VERSION "dbc-export 1 2026.26.6.5"

NS_ :

BS_:

BU_: ADSP APB APP APS APSB BB BMS CC CMP CMPD CP DAS DI DIF DIR DPB EPAS3P EPAS3S EPASTP EPASTS EPBL EPBR ESP EVSE FC GTW HCML HCMR HVP IBST ICR IDB LS OCS1P ODIN PARK PCS PCS2 PLG PM PMF PMR PNCD PTC RADC RCM RCM2 RCM3 RCU SCCM SCM SCS SDCR TAS TCU TCU2 TPMS TRCM UDS UI UIS UMC USM V2G VC VCBATT VCBATT0 VCBATT1 VCBATT2 VCCC VCFRONT VCFRONT1 VCFRONT2 VCLEFT VCRIGHT VCSEAT2L VCSEAT2R VCSEC VEH

BO_ 1318 DIF_alertLog: 8 DIF
 SG_ DIF_alertID M : 0|8@1+ (1,0) [0|255] "" Vector__XXX
 SG_ DIF_alertState : 15|1@1+ (1,0) [0|1] "" Vector__XXX
 SG_ DIF_a001_thermalWarning_H m1 : 16|1@1+ (1,0) [0|1] "" Vector__XXX
 SG_ DIF_a001_thermalShutdown_H m1 : 17|1@1+ (1,0) [0|1] "" Vector__XXX
 SG_ DIF_a001_undervoltVL_H m1 : 18|1@1+ (1,0) [0|1] "" Vector__XXX
 SG_ DIF_a001_undervoltVH_H m1 : 19|1@1+ (1,0) [0|1] "" Vector__XXX
 SG_ DIF_a001_sense_H m1 : 20|1@1+ (1,0) [0|1] "" Vector__XXX
 SG_ DIF_a001_desat_H m1 : 21|1@1+ (1,0) [0|1] "" Vector__XXX
 SG_ DIF_a001_overvoltVL_H m1 : 22|1@1+ (1,0) [0|1] "" Vector__XXX
 SG_ DIF_a001_overvoltVH_H m1 : 23|1@1+ (1,0) [0|1] "" Vector__XXX
 SG_ DIF_a001_undervoltVCC_H m1 : 24|1@1+ (1,0) [0|1] "" Vector__XXX
 SG_ DIF_a001_asynchStop_H m1 : 25|1@1+ (1,0) [0|1] "" Vector__XXX
 SG_ DIF_a001_remoteRegError_H m1 : 26|1@1+ (1,0) [0|1] "" Vector__XXX
 SG_ DIF_a001_undervoltVDD_H m1 : 27|1@1+ (1,0) [0|1] "" Vector__XXX
 SG_ DIF_a001_overvoltVDD_H m1 : 28|1@1+ (1,0) [0|1] "" Vector__XXX
 SG_ DIF_a001_localRegError_H m1 : 29|1@1+ (1,0) [0|1] "" Vector__XXX
 SG_ DIF_a001_spiError_H m1 : 30|1@1+ (1,0) [0|1] "" Vector__XXX
 SG_ DIF_a001_deadtimeError_H m1 : 31|1@1+ (1,0) [0|1] "" Vector__XXX
 SG_ DIF_a001_thermalWarning_L m1 : 32|1@1+ (1,0) [0|1] "" Vector__XXX
 SG_ DIF_a001_thermalShutdown_L m1 : 33|1@1+ (1,0) [0|1] "" Vector__XXX
 SG_ DIF_a001_undervoltVL_L m1 : 34|1@1+ (1,0) [0|1] "" Vector__XXX
 SG_ DIF_a001_undervoltVH_L m1 : 35|1@1+ (1,0) [0|1] "" Vector__XXX
 SG_ DIF_a001_sense_L m1 : 36|1@1+ (1,0) [0|1] "" Vector__XXX
 SG_ DIF_a001_desat_L m1 : 37|1@1+ (1,0) [0|1] "" Vector__XXX
 SG_ DIF_a001_overvoltVL_L m1 : 38|1@1+ (1,0) [0|1] "" Vector__XXX
 SG_ DIF_a001_overvoltVH_L m1 : 39|1@1+ (1,0) [0|1] "" Vector__XXX
 SG_ DIF_a001_undervoltVCC_L m1 : 40|1@1+ (1,0) [0|1] "" Vector__XXX
 SG_ DIF_a001_asynchStop_L m1 : 41|1@1+ (1,0) [0|1] "" Vector__XXX
 SG_ DIF_a001_remoteRegError_L m1 : 42|1@1+ (1,0) [0|1] "" Vector__XXX
 SG_ DIF_a001_undervoltVDD_L m1 : 43|1@1+ (1,0) [0|1] "" Vector__XXX
 SG_ DIF_a001_overvoltVDD_L m1 : 44|1@1+ (1,0) [0|1] "" Vector__XXX
 SG_ DIF_a001_localRegError_L m1 : 45|1@1+ (1,0) [0|1] "" Vector__XXX
 SG_ DIF_a001_spiError_L m1 : 46|1@1+ (1,0) [0|1] "" Vector__XXX
 SG_ DIF_a001_deadtimeError_L m1 : 47|1@1+ (1,0) [0|1] "" Vector__XXX
 SG_ DIF_a001_gateDriveErrCounter m1 : 48|4@1+ (1,0) [0|15] "" Vector__XXX
 SG_ DIF_a001_remoteCommError_H m1 : 52|1@1+ (1,0) [0|1] "" Vector__XXX
 SG_ DIF_a001_localCommError_H m1 : 53|1@1+ (1,0) [0|1] "" Vector__XXX
 SG_ DIF_a001_remoteReset_H m1 : 54|1@1+ (1,0) [0|1] "" Vector__XXX
 SG_ DIF_a001_localReset_H m1 : 55|1@1+ (1,0) [0|1] "" Vector__XXX
 SG_ DIF_a001_remoteCommError_L m1 : 56|1@1+ (1,0) [0|1] "" Vector__XXX
 SG_ DIF_a001_localCommError_L m1 : 57|1@1+ (1,0) [0|1] "" Vector__XXX
 SG_ DIF_a001_remoteReset_L m1 : 58|1@1+ (1,0) [0|1] "" Vector__XXX
 SG_ DIF_a001_localReset_L m1 : 59|1@1+ (1,0) [0|1] "" Vector__XXX
 SG_ DIF_a001_faultLine1Gpio_H m1 : 60|1@1+ (1,0) [0|1] "" Vector__XXX
 SG_ DIF_a001_faultLine1Gpio_L m1 : 61|1@1+ (1,0) [0|1] "" Vector__XXX
 SG_ DIF_a002_thermalWarning_H m2 : 16|1@1+ (1,0) [0|1] "" Vector__XXX
 SG_ DIF_a002_thermalShutdown_H m2 : 17|1@1+ (1,0) [0|1] "" Vector__XXX
 SG_ DIF_a002_undervoltVL_H m2 : 18|1@1+ (1,0) [0|1] "" Vector__XXX
 SG_ DIF_a002_undervoltVH_H m2 : 19|1@1+ (1,0) [0|1] "" Vector__XXX
 SG_ DIF_a002_sense_H m2 : 20|1@1+ (1,0) [0|1] "" Vector__XXX
 SG_ DIF_a002_desat_H m2 : 21|1@1+ (1,0) [0|1] "" Vector__XXX
 SG_ DIF_a002_overvoltVL_H m2 : 22|1@1+ (1,0) [0|1] "" Vector__XXX
 SG_ DIF_a002_overvoltVH_H m2 : 23|1@1+ (1,0) [0|1] "" Vector__XXX
 SG_ DIF_a002_undervoltVCC_H m2 : 24|1@1+ (1,0) [0|1] "" Vector__XXX
 SG_ DIF_a002_asynchStop_H m2 : 25|1@1+ (1,0) [0|1] "" Vector__XXX
 SG_ DIF_a002_remoteRegError_H m2 : 26|1@1+ (1,0) [0|1] "" Vector__XXX
 SG_ DIF_a002_undervoltVDD_H m2 : 27|1@1+ (1,0) [0|1] "" Vector__XXX
 SG_ DIF_a002_overvoltVDD_H m2 : 28|1@1+ (1,0) [0|1] "" Vector__XXX
 SG_ DIF_a002_localRegError_H m2 : 29|1@1+ (1,0) [0|1] "" Vector__XXX
 SG_ DIF_a002_spiError_H m2 : 30|1@1+ (1,0) [0|1] "" Vector__XXX
 SG_ DIF_a002_deadtimeError_H m2 : 31|1@1+ (1,0) [0|1] "" Vector__XXX
 SG_ DIF_a002_thermalWarning_L m2 : 32|1@1+ (1,0) [0|1] "" Vector__XXX
 SG_ DIF_a002_thermalShutdown_L m2 : 33|1@1+ (1,0) [0|1] "" Vector__XXX
 SG_ DIF_a002_undervoltVL_L m2 : 34|1@1+ (1,0) [0|1] "" Vector__XXX
 SG_ DIF_a002_undervoltVH_L m2 : 35|1@1+ (1,0) [0|1] "" Vector__XXX
 SG_ DIF_a002_sense_L m2 : 36|1@1+ (1,0) [0|1] "" Vector__XXX
 SG_ DIF_a002_desat_L m2 : 37|1@1+ (1,0) [0|1] "" Vector__XXX
 SG_ DIF_a002_overvoltVL_L m2 : 38|1@1+ (1,0) [0|1] "" Vector__XXX
 SG_ DIF_a002_overvoltVH_L m2 : 39|1@1+ (1,0) [0|1] "" Vector__XXX
 SG_ DIF_a002_undervoltVCC_L m2 : 40|1@1+ (1,0) [0|1] "" Vector__XXX
 SG_ DIF_a002_asynchStop_L m2 : 41|1@1+ (1,0) [0|1] "" Vector__XXX
 SG_ DIF_a002_remoteRegError_L m2 : 42|1@1+ (1,0) [0|1] "" Vector__XXX
 SG_ DIF_a002_undervoltVDD_L m2 : 43|1@1+ (1,0) [0|1] "" Vector__XXX
 SG_ DIF_a002_overvoltVDD_L m2 : 44|1@1+ (1,0) [0|1] "" Vector__XXX
 SG_ DIF_a002_localRegError_L m2 : 45|1@1+ (1,0) [0|1] "" Vector__XXX
 SG_ DIF_a002_spiError_L m2 : 46|1@1+ (1,0) [0|1] "" Vector__XXX
 SG_ DIF_a002_deadtimeError_L m2 : 47|1@1+ (1,0) [0|1] "" Vector__XXX
 SG_ DIF_a002_gateDriveErrCounter m2 : 48|4@1+ (1,0) [0|15] "" Vector__XXX
 SG_ DIF_a002_remoteCommError_H m2 : 52|1@1+ (1,0) [0|1] "" Vector__XXX
 SG_ DIF_a002_localCommError_H m2 : 53|1@1+ (1,0) [0|1] "" Vector__XXX
 SG_ DIF_a002_remoteReset_H m2 : 54|1@1+ (1,0) [0|1] "" Vector__XXX
 SG_ DIF_a002_localReset_H m2 : 55|1@1+ (1,0) [0|1] "" Vector__XXX
 SG_ DIF_a002_remoteCommError_L m2 : 56|1@1+ (1,0) [0|1] "" Vector__XXX
 SG_ DIF_a002_localCommError_L m2 : 57|1@1+ (1,0) [0|1] "" Vector__XXX
 SG_ DIF_a002_remoteReset_L m2 : 58|1@1+ (1,0) [0|1] "" Vector__XXX
 SG_ DIF_a002_localReset_L m2 : 59|1@1+ (1,0) [0|1] "" Vector__XXX
 SG_ DIF_a002_faultLine1Gpio_H m2 : 60|1@1+ (1,0) [0|1] "" Vector__XXX
 SG_ DIF_a002_faultLine1Gpio_L m2 : 61|1@1+ (1,0) [0|1] "" Vector__XXX
 SG_ DIF_a003_thermalWarning_H m3 : 16|1@1+ (1,0) [0|1] "" Vector__XXX
 SG_ DIF_a003_thermalShutdown_H m3 : 17|1@1+ (1,0) [0|1] "" Vector__XXX
 SG_ DIF_a003_undervoltVL_H m3 : 18|1@1+ (1,0) [0|1] "" Vector__XXX
 SG_ DIF_a003_undervoltVH_H m3 : 19|1@1+ (1,0) [0|1] "" Vector__XXX
 SG_ DIF_a003_sense_H m3 : 20|1@1+ (1,0) [0|1] "" Vector__XXX
 SG_ DIF_a003_desat_H m3 : 21|1@1+ (1,0) [0|1] "" Vector__XXX
 SG_ DIF_a003_overvoltVL_H m3 : 22|1@1+ (1,0) [0|1] "" Vector__XXX
 SG_ DIF_a003_overvoltVH_H m3 : 23|1@1+ (1,0) [0|1] "" Vector__XXX
 SG_ DIF_a003_undervoltVCC_H m3 : 24|1@1+ (1,0) [0|1] "" Vector__XXX
 SG_ DIF_a003_asynchStop_H m3 : 25|1@1+ (1,0) [0|1] "" Vector__XXX
 SG_ DIF_a003_remoteRegError_H m3 : 26|1@1+ (1,0) [0|1] "" Vector__XXX
 SG_ DIF_a003_undervoltVDD_H m3 : 27|1@1+ (1,0) [0|1] "" Vector__XXX
 SG_ DIF_a003_overvoltVDD_H m3 : 28|1@1+ (1,0) [0|1] "" Vector__XXX
 SG_ DIF_a003_localRegError_H m3 : 29|1@1+ (1,0) [0|1] "" Vector__XXX
 SG_ DIF_a003_spiError_H m3 : 30|1@1+ (1,0) [0|1] "" Vector__XXX
 SG_ DIF_a003_deadtimeError_H m3 : 31|1@1+ (1,0) [0|1] "" Vector__XXX
 SG_ DIF_a003_thermalWarning_L m3 : 32|1@1+ (1,0) [0|1] "" Vector__XXX
 SG_ DIF_a003_thermalShutdown_L m3 : 33|1@1+ (1,0) [0|1] "" Vector__XXX
 SG_ DIF_a003_undervoltVL_L m3 : 34|1@1+ (1,0) [0|1] "" Vector__XXX
 SG_ DIF_a003_undervoltVH_L m3 : 35|1@1+ (1,0) [0|1] "" Vector__XXX
 SG_ DIF_a003_sense_L m3 : 36|1@1+ (1,0) [0|1] "" Vector__XXX
 SG_ DIF_a003_desat_L m3 : 37|1@1+ (1,0) [0|1] "" Vector__XXX
 SG_ DIF_a003_overvoltVL_L m3 : 38|1@1+ (1,0) [0|1] "" Vector__XXX
 SG_ DIF_a003_overvoltVH_L m3 : 39|1@1+ (1,0) [0|1] "" Vector__XXX
 SG_ DIF_a003_undervoltVCC_L m3 : 40|1@1+ (1,0) [0|1] "" Vector__XXX
 SG_ DIF_a003_asynchStop_L m3 : 41|1@1+ (1,0) [0|1] "" Vector__XXX
 SG_ DIF_a003_remoteRegError_L m3 : 42|1@1+ (1,0) [0|1] "" Vector__XXX
 SG_ DIF_a003_undervoltVDD_L m3 : 43|1@1+ (1,0) [0|1] "" Vector__XXX
 SG_ DIF_a003_overvoltVDD_L m3 : 44|1@1+ (1,0) [0|1] "" Vector__XXX
 SG_ DIF_a003_localRegError_L m3 : 45|1@1+ (1,0) [0|1] "" Vector__XXX
 SG_ DIF_a003_spiError_L m3 : 46|1@1+ (1,0) [0|1] "" Vector__XXX
 SG_ DIF_a003_deadtimeError_L m3 : 47|1@1+ (1,0) [0|1] "" Vector__XXX
 SG_ DIF_a003_gateDriveErrCounter m3 : 48|4@1+ (1,0) [0|15] "" Vector__XXX
 SG_ DIF_a003_remoteCommError_H m3 : 52|1@1+ (1,0) [0|1] "" Vector__XXX
 SG_ DIF_a003_localCommError_H m3 : 53|1@1+ (1,0) [0|1] "" Vector__XXX
 SG_ DIF_a003_remoteReset_H m3 : 54|1@1+ (1,0) [0|1] "" Vector__XXX
 SG_ DIF_a003_localReset_H m3 : 55|1@1+ (1,0) [0|1] "" Vector__XXX
 SG_ DIF_a003_remoteCommError_L m3 : 56|1@1+ (1,0) [0|1] "" Vector__XXX
 SG_ DIF_a003_localCommError_L m3 : 57|1@1+ (1,0) [0|1] "" Vector__XXX
 SG_ DIF_a003_remoteReset_L m3 : 58|1@1+ (1,0) [0|1] "" Vector__XXX
 SG_ DIF_a003_localReset_L m3 : 59|1@1+ (1,0) [0|1] "" Vector__XXX
 SG_ DIF_a003_faultLine1Gpio_H m3 : 60|1@1+ (1,0) [0|1] "" Vector__XXX
 SG_ DIF_a003_faultLine1Gpio_L m3 : 61|1@1+ (1,0) [0|1] "" Vector__XXX
 SG_ DIF_a007_phaseAcurrent m7 : 16|8@1+ (8,0) [0|2040] "A" Vector__XXX
 SG_ DIF_a007_phaseBcurrent m7 : 24|8@1+ (8,0) [0|2040] "A" Vector__XXX
 SG_ DIF_a007_offsetError m7 : 32|14@1- (0.0003834952,0) [-3.1415926784|3.1412091832] "rad" Vector__XXX
 SG_ DIF_a007_idFdbStdDeviation m7 : 46|8@1+ (4,0) [0|1020] "A" Vector__XXX
 SG_ DIF_a007_iqFdbStdDeviation m7 : 54|8@1+ (4,0) [0|1020] "A" Vector__XXX
 SG_ DIF_a007_motorShift m7 : 62|1@1+ (1,0) [0|1] "" Vector__XXX
 SG_ DIF_a007_motorShort m7 : 63|1@1+ (1,0) [0|1] "" Vector__XXX
 SG_ DIF_a010_sccReset m10 : 16|1@1+ (1,0) [0|1] "" Vector__XXX
 SG_ DIF_a010_hibernate m10 : 17|1@1+ (1,0) [0|1] "" Vector__XXX
 SG_ DIF_a010_hwBist m10 : 18|1@1+ (1,0) [0|1] "" Vector__XXX
 SG_ DIF_a010_nmiWatchdog m10 : 19|1@1+ (1,0) [0|1] "" Vector__XXX
 SG_ DIF_a010_watchdog m10 : 20|1@1+ (1,0) [0|1] "" Vector__XXX
 SG_ DIF_a010_clockFailNmi m10 : 21|1@1+ (1,0) [0|1] "" Vector__XXX
 SG_ DIF_a010_ramUncErrorNmi m10 : 22|1@1+ (1,0) [0|1] "" Vector__XXX
 SG_ DIF_a010_flashUncErrorNmi m10 : 23|1@1+ (1,0) [0|1] "" Vector__XXX
 SG_ DIF_a010_cpu1signMismatchNmi m10 : 24|1@1+ (1,0) [0|1] "" Vector__XXX
 SG_ DIF_a010_cpu2signMismatchNmi m10 : 25|1@1+ (1,0) [0|1] "" Vector__XXX
 SG_ DIF_a010_pieVectErrorNmi m10 : 26|1@1+ (1,0) [0|1] "" Vector__XXX
 SG_ DIF_a010_sysDbgNmi m10 : 27|1@1+ (1,0) [0|1] "" Vector__XXX
 SG_ DIF_a010_rlNmi m10 : 28|1@1+ (1,0) [0|1] "" Vector__XXX
 SG_ DIF_a010_ovfNmi m10 : 29|1@1+ (1,0) [0|1] "" Vector__XXX
 SG_ DIF_a010_wdtFlags m10 : 32|16@1+ (1,0) [0|65535] "" Vector__XXX
 SG_ DIF_a011_reason m11 : 16|3@1+ (1,0) [0|7] "" Vector__XXX
 SG_ DIF_a011_phaseAHigh m11 : 19|1@1+ (1,0) [0|1] "" Vector__XXX
 SG_ DIF_a011_phaseALow m11 : 20|1@1+ (1,0) [0|1] "" Vector__XXX
 SG_ DIF_a011_phaseBHigh m11 : 21|1@1+ (1,0) [0|1] "" Vector__XXX
 SG_ DIF_a011_phaseBLow m11 : 22|1@1+ (1,0) [0|1] "" Vector__XXX
 SG_ DIF_a011_phaseCHigh m11 : 23|1@1+ (1,0) [0|1] "" Vector__XXX
 SG_ DIF_a011_phaseCLow m11 : 24|1@1+ (1,0) [0|1] "" Vector__XXX
 SG_ DIF_a011_regAddress m11 : 25|5@1+ (1,0) [0|31] "" Vector__XXX
 SG_ DIF_a011_badGateDriveIC m11 : 32|3@1+ (1,0) [0|7] "" Vector__XXX
 SG_ DIF_a011_badDataRead m11 : 40|8@1+ (1,0) [0|255] "" Vector__XXX
 SG_ DIF_a011_badDataExpected m11 : 48|8@1+ (1,0) [0|255] "" Vector__XXX
 SG_ DIF_a011_codeBranch m11 : 56|4@1+ (1,0) [0|15] "" Vector__XXX
 SG_ DIF_a012_hvilStatus m12 : 16|2@1+ (1,0) [0|2] "" Vector__XXX
 SG_ DIF_a012_hvilCmVoltage m12 : 24|8@1+ (0.08,0) [0|20.4] "V" Vector__XXX
 SG_ DIF_a012_hvilCurrent m12 : 32|8@1+ (0.1,0) [0|25.5] "mA" Vector__XXX
 SG_ DIF_a012_hvilFaultGpio m12 : 40|1@1+ (1,0) [0|1] "" Vector__XXX
 SG_ DIF_a012_hvilSupplyPinDI m12 : 41|1@1+ (1,0) [0|1] "" Vector__XXX
 SG_ DIF_a012_hvilSupplyPinPM m12 : 42|1@1+ (1,0) [0|1] "" Vector__XXX
 SG_ DIF_a012_activeDisOn3V3 m12 : 43|1@1+ (1,0) [0|1] "" Vector__XXX
 SG_ DIF_a012_hvilHeaderFault m12 : 44|1@1+ (1,0) [0|1] "" Vector__XXX
 SG_ DIF_a013_address m13 : 16|32@1+ (1,0) [0|4294967295] "" Vector__XXX
 SG_ DIF_a013_errorType m13 : 48|4@1+ (1,0) [0|15] "" Vector__XXX
 SG_ DIF_a014_motorSpeed m14 : 16|14@1- (2,0) [-16384|16382] "RPM" Vector__XXX
 SG_ DIF_a014_adState m14 : 30|2@1+ (1,0) [0|3] "" Vector__XXX
 SG_ DIF_a014_torqueCommandFwd m14 : 32|10@1- (2,0) [-1024|1022] "Nm" Vector__XXX
 SG_ DIF_a014_brakeMasterCylPress m14 : 42|10@1+ (0.25,-42.5) [-42.5|213.25] "bar" Vector__XXX
 SG_ DIF_a014_rmsTorqueError m14 : 52|10@1+ (1,0) [0|1023] "Nm" Vector__XXX
 SG_ DIF_a014_tcEnabled m14 : 62|1@1+ (1,0) [0|1] "" Vector__XXX
 SG_ DIF_a014_fbDeratedForRmsError m14 : 63|1@1+ (1,0) [0|1] "" Vector__XXX
 SG_ DIF_a016_newSafeState m16 : 16|2@1+ (1,0) [0|3] "" Vector__XXX
 SG_ DIF_a016_oldSafeState m16 : 18|2@1+ (1,0) [0|3] "" Vector__XXX
 SG_ DIF_a016_gateDriveFaultLine m16 : 20|1@1+ (1,0) [0|1] "" Vector__XXX
 SG_ DIF_a016_ascMonitor m16 : 21|1@1+ (1,0) [0|1] "" Vector__XXX
 SG_ DIF_a016_uncontrolledRegenZone m16 : 22|1@1+ (1,0) [0|1] "" Vector__XXX
 SG_ DIF_a016_pedalMonitorPreWatchdog m16 : 23|1@1+ (1,0) [0|1] "" Vector__XXX
 SG_ DIF_a016_motorRPM m16 : 24|16@1- (1,0) [-32768|32767] "RPM" Vector__XXX
 SG_ DIF_a016_torqueMotor m16 : 40|16@1- (1,0) [-32768|32767] "Nm" Vector__XXX
 SG_ DIF_a016_safetyICfaultLine m16 : 56|1@1+ (1,0) [0|1] "" Vector__XXX
 SG_ DIF_a016_triggerEvent m16 : 57|5@1+ (1,0) [0|31] "" Vector__XXX
 SG_ DIF_a024_vBat m24 : 16|8@1+ (2,0) [0|510] "V" Vector__XXX
 SG_ DIF_a024_failReason m24 : 24|3@1+ (1,0) [0|7] "" Vector__XXX
 SG_ DIF_a024_state m24 : 27|4@1+ (1,0) [0|15] "" Vector__XXX
 SG_ DIF_a024_Ia m24 : 31|7@1- (22.5,0) [-1440|1417.5] "A" Vector__XXX
 SG_ DIF_a024_Ib m24 : 38|7@1- (22.5,0) [-1440|1417.5] "A" Vector__XXX
 SG_ DIF_a024_maxCurrMagSqrd m24 : 45|12@1+ (500,0) [0|2047500] "A2" Vector__XXX
 SG_ DIF_a024_rotorAngle m24 : 57|7@1- (3,0) [-192|189] "degrees" Vector__XXX
 SG_ DIF_a025_Ia m25 : 16|16@1- (0.1,0) [-3276.8|3276.7] "A" Vector__XXX
 SG_ DIF_a025_torqueMotor m25 : 32|13@1- (0.25,0) [-1024|1023.75] "Nm" Vector__XXX
 SG_ DIF_a025_motorSpeed m25 : 48|16@1- (1,0) [-32768|32767] "RPM" Vector__XXX
 SG_ DIF_a026_Ib m26 : 16|16@1- (0.1,0) [-3276.8|3276.7] "A" Vector__XXX
 SG_ DIF_a026_torqueMotor m26 : 32|13@1- (0.25,0) [-1024|1023.75] "Nm" Vector__XXX
 SG_ DIF_a026_motorSpeed m26 : 48|16@1- (1,0) [-32768|32767] "RPM" Vector__XXX
 SG_ DIF_a027_Ic m27 : 16|16@1- (0.1,0) [-3276.8|3276.7] "A" Vector__XXX
 SG_ DIF_a027_torqueMotor m27 : 32|13@1- (0.25,0) [-1024|1023.75] "Nm" Vector__XXX
 SG_ DIF_a027_motorSpeed m27 : 48|16@1- (1,0) [-32768|32767] "RPM" Vector__XXX
 SG_ DIF_a028_phaseAirms m28 : 16|16@1+ (1,0) [0|65535] "A" Vector__XXX
 SG_ DIF_a028_iArmsTorque m28 : 32|16@1+ (0.25,0) [0|16383.75] "Nm" Vector__XXX
 SG_ DIF_a028_iArmsSpeed m28 : 48|16@1+ (1,0) [0|65535] "RPM" Vector__XXX
 SG_ DIF_a029_phaseBirms m29 : 16|16@1+ (1,0) [0|65535] "A" Vector__XXX
 SG_ DIF_a029_iBrmsTorque m29 : 32|16@1+ (0.25,0) [0|16383.75] "Nm" Vector__XXX
 SG_ DIF_a029_iBrmsSpeed m29 : 48|16@1+ (1,0) [0|65535] "RPM" Vector__XXX
 SG_ DIF_a030_phaseCirms m30 : 16|16@1+ (1,0) [0|65535] "A" Vector__XXX
 SG_ DIF_a030_iCrmsTorque m30 : 32|16@1+ (0.25,0) [0|16383.75] "Nm" Vector__XXX
 SG_ DIF_a030_iCrmsSpeed m30 : 48|16@1+ (1,0) [0|65535] "RPM" Vector__XXX
 SG_ DIF_a031_phaseAoffset m31 : 16|15@1- (0.002,0) [-32.768|32.766] "A" Vector__XXX
 SG_ DIF_a032_phaseBoffset m32 : 16|15@1- (0.002,0) [-32.768|32.766] "A" Vector__XXX
 SG_ DIF_a033_phaseAcurrent m33 : 16|16@1- (1,0) [-32768|32767] "A" Vector__XXX
 SG_ DIF_a033_deltaIa m33 : 32|16@1- (1,0) [-32768|32767] "A" Vector__XXX
 SG_ DIF_a033_vRefIa m33 : 48|16@1- (0.001,0) [-32.768|32.767] "V" Vector__XXX
 SG_ DIF_a034_phaseBcurrent m34 : 16|16@1- (1,0) [-32768|32767] "A" Vector__XXX
 SG_ DIF_a034_deltaIb m34 : 32|16@1- (1,0) [-32768|32767] "A" Vector__XXX
 SG_ DIF_a034_vRefIb m34 : 48|16@1- (0.001,0) [-32.768|32.767] "V" Vector__XXX
 SG_ DIF_a035_phaseAerror m35 : 16|1@1+ (1,0) [0|1] "" Vector__XXX
 SG_ DIF_a035_phaseBerror m35 : 17|1@1+ (1,0) [0|1] "" Vector__XXX
 SG_ DIF_a035_phaseCerror m35 : 18|1@1+ (1,0) [0|1] "" Vector__XXX
 SG_ DIF_a035_standbyCurrent m35 : 19|1@1+ (1,0) [0|1] "" Vector__XXX
 SG_ DIF_a035_unbalancedCurrent m35 : 20|1@1+ (1,0) [0|1] "" Vector__XXX
 SG_ DIF_a035_wontMoveCurrent m35 : 21|1@1+ (1,0) [0|1] "" Vector__XXX
 SG_ DIF_a035_reportingPhase m35 : 22|2@1+ (1,0) [0|3] "" Vector__XXX
 SG_ DIF_a035_noDriveCurrent m35 : 24|1@1+ (1,0) [0|1] "" Vector__XXX
 SG_ DIF_a035_phaseDifference m35 : 25|7@1+ (1,0) [0|127] "%" Vector__XXX
 SG_ DIF_a035_phaseCurrent m35 : 32|16@1+ (1,0) [0|65535] "A" Vector__XXX
 SG_ DIF_a035_frequency m35 : 48|10@1+ (1,0) [0|1023] "Hz" Vector__XXX
 SG_ DIF_a036_busVoltage m36 : 16|16@1+ (0.1,0) [0|6553.5] "V" Vector__XXX
 SG_ DIF_a036_busHighLimit m36 : 32|16@1+ (0.1,0) [0|6553.5] "V" Vector__XXX
 SG_ DIF_a037_busVoltage m37 : 16|16@1+ (0.1,0) [0|6553.5] "V" Vector__XXX
 SG_ DIF_a037_busLowLimit m37 : 32|16@1+ (0.1,0) [0|6553.5] "V" Vector__XXX
 SG_ DIF_a038_vBMS m38 : 16|13@1+ (0.2,0) [0|1638.2] "V" Vector__XXX
 SG_ DIF_a038_vBat m38 : 32|13@1+ (0.2,0) [0|1638.2] "V" Vector__XXX
 SG_ DIF_a038_iBat m38 : 48|13@1+ (0.5,0) [0|4095.5] "A" Vector__XXX
 SG_ DIF_a038_reason m38 : 61|2@1+ (1,0) [0|3] "" Vector__XXX
 SG_ DIF_a040_torque m40 : 16|1@1+ (1,0) [0|1] "" Vector__XXX
 SG_ DIF_a040_capability m40 : 17|1@1+ (1,0) [0|1] "" Vector__XXX
 SG_ DIF_a040_power m40 : 18|1@1+ (1,0) [0|1] "" Vector__XXX
 SG_ DIF_a040_status m40 : 19|1@1+ (1,0) [0|1] "" Vector__XXX
 SG_ DIF_a040_capability2 m40 : 20|1@1+ (1,0) [0|1] "" Vector__XXX
 SG_ DIF_a040_hvStatus m40 : 21|1@1+ (1,0) [0|1] "" Vector__XXX
 SG_ DIF_a040_temperature m40 : 22|1@1+ (1,0) [0|1] "" Vector__XXX
 SG_ DIF_a041_uartRxDataAvailable m41 : 16|1@1+ (1,0) [0|1] "" Vector__XXX
 SG_ DIF_a041_SDC_status_MIA m41 : 17|1@1+ (1,0) [0|1] "" Vector__XXX
 SG_ DIF_a041_diUartRxVersion m41 : 18|4@1+ (1,0) [0|15] "" Vector__XXX
 SG_ DIF_a041_sdcUartRxVersion m41 : 24|4@1+ (1,0) [0|15] "" Vector__XXX
 SG_ DIF_a043_outletTemp m43 : 16|16@1- (0.1,0) [-3276.8|3276.7] "C" Vector__XXX
 SG_ DIF_a044_outletTemp m44 : 16|16@1- (0.1,0) [-3276.8|3276.7] "C" Vector__XXX
 SG_ DIF_a045_inletTemp m45 : 16|10@1+ (0.25,-60) [-60|195.75] "DegC" Vector__XXX
 SG_ DIF_a045_outletTemp m45 : 26|10@1+ (0.25,-60) [-60|195.75] "DegC" Vector__XXX
 SG_ DIF_a045_heatsinkTemp m45 : 36|10@1+ (0.25,-60) [-60|195.75] "DegC" Vector__XXX
 SG_ DIF_a045_outletTempSlope m45 : 48|8@1- (0.5,0) [-64|63.5] "DegC/s" Vector__XXX
 SG_ DIF_a046_statorTemp1 m46 : 16|16@1- (0.1,0) [-3276.8|3276.7] "DegC" Vector__XXX
 SG_ DIF_a046_statorTemp2 m46 : 32|16@1- (0.1,0) [-3276.8|3276.7] "DegC" Vector__XXX
 SG_ DIF_a047_statorTemp1 m47 : 16|16@1- (0.1,0) [-3276.8|3276.7] "DegC" Vector__XXX
 SG_ DIF_a047_statorTslope1 m47 : 32|16@1- (0.1,0) [-3276.8|3276.7] "DegC/s" Vector__XXX
 SG_ DIF_a050_statorTemp1 m50 : 16|16@1- (0.1,0) [-3276.8|3276.7] "DegC" Vector__XXX
 SG_ DIF_a050_statorTemp2 m50 : 32|16@1- (0.1,0) [-3276.8|3276.7] "DegC" Vector__XXX
 SG_ DIF_a052_torque m52 : 16|1@1+ (1,0) [0|1] "" Vector__XXX
 SG_ DIF_a052_capability m52 : 17|1@1+ (1,0) [0|1] "" Vector__XXX
 SG_ DIF_a052_power m52 : 18|1@1+ (1,0) [0|1] "" Vector__XXX
 SG_ DIF_a052_status m52 : 19|1@1+ (1,0) [0|1] "" Vector__XXX
 SG_ DIF_a052_capability2 m52 : 20|1@1+ (1,0) [0|1] "" Vector__XXX
 SG_ DIF_a052_hvStatus m52 : 21|1@1+ (1,0) [0|1] "" Vector__XXX
 SG_ DIF_a052_temperature m52 : 22|1@1+ (1,0) [0|1] "" Vector__XXX
 SG_ DIF_a054_outletTemp m54 : 16|16@1- (0.1,0) [-3276.8|3276.7] "C" Vector__XXX
 SG_ DIF_a054_heatsinkTemp m54 : 32|16@1- (0.1,0) [-3276.8|3276.7] "C" Vector__XXX
 SG_ DIF_a055_parameterDI m55 : 16|13@1- (0.25,0) [-1024|1023.75] "Nm" Vector__XXX
 SG_ DIF_a055_parameterPM m55 : 32|13@1- (0.25,0) [-1024|1023.75] "Nm" Vector__XXX
 SG_ DIF_a055_torqueType m55 : 45|2@1+ (1,0) [0|3] "" Vector__XXX
 SG_ DIF_a055_motorRPM m55 : 48|16@1- (1,0) [-32768|32767] "RPM" Vector__XXX
 SG_ DIF_a056_pcbTemp m56 : 16|16@1- (0.1,0) [-3276.8|3276.7] "C" Vector__XXX
 SG_ DIF_a057_pcbTemp m57 : 16|16@1- (0.1,0) [-3276.8|3276.7] "C" Vector__XXX
 SG_ DIF_a058_pcbTemp m58 : 16|10@1+ (0.25,-60) [-60|195.75] "DegC" Vector__XXX
 SG_ DIF_a058_outletTemp m58 : 26|10@1+ (0.25,-60) [-60|195.75] "DegC" Vector__XXX
 SG_ DIF_a058_heatsinkTemp m58 : 36|10@1+ (0.25,-60) [-60|195.75] "DegC" Vector__XXX
 SG_ DIF_a058_pcbTempSlope m58 : 48|8@1- (0.5,0) [-64|63.5] "DegC/s" Vector__XXX
 SG_ DIF_a059_heatsinkTemp m59 : 16|16@1- (0.1,0) [-3276.8|3276.7] "C" Vector__XXX
 SG_ DIF_a060_heatsinkTemp m60 : 16|16@1- (0.1,0) [-3276.8|3276.7] "C" Vector__XXX
 SG_ DIF_a061_sensor m61 : 16|2@1+ (1,0) [0|3] "" Vector__XXX
 SG_ DIF_a061_reason m61 : 18|1@1+ (1,0) [0|1] "" Vector__XXX
 SG_ DIF_a061_phTemp m61 : 24|16@1- (0.1,0) [-3276.8|3276.7] "C" Vector__XXX
 SG_ DIF_a061_otherTemp m61 : 40|16@1- (0.1,0) [-3276.8|3276.7] "C" Vector__XXX
 SG_ DIF_a062_limpReason m62 : 16|6@1+ (1,0) [0|63] "" Vector__XXX
 SG_ DIF_a063_BB_status m63 : 16|1@1+ (1,0) [0|1] "" Vector__XXX
 SG_ DIF_a064_interventionType m64 : 16|4@1+ (1,0) [0|15] "" Vector__XXX
 SG_ DIF_a064_torqueCmdState m64 : 20|4@1+ (1,0) [1|15] "" Vector__XXX
 SG_ DIF_a069_motorSpeed m69 : 16|16@1- (1,0) [-32768|32767] "RPM" Vector__XXX
 SG_ DIF_a069_rotorCoolingPower m69 : 32|8@1+ (20,0) [0|5100] "W" Vector__XXX
 SG_ DIF_a069_rotorMagnetTemp m69 : 40|10@1+ (0.25,-60) [-60|195.75] "DegC" Vector__XXX
 SG_ DIF_a069_fittedTorqueLimit m69 : 50|13@1- (0.25,0) [-1024|1023.75] "Nm" Vector__XXX
 SG_ DIF_a072_reason m72 : 16|2@1+ (1,0) [0|3] "" Vector__XXX
 SG_ DIF_a073_motorSpeedrpm m73 : 16|16@1- (1,0) [-32768|32767] "RPM" Vector__XXX
 SG_ DIF_a075_motorSpeed m75 : 16|16@1+ (1,0) [0|65535] "RPM" Vector__XXX
 SG_ DIF_a075_absSpeed m75 : 32|16@1+ (1,0) [0|65535] "RPM" Vector__XXX
 SG_ DIF_a076_lvSupplyV m76 : 16|16@1+ (0.001,0) [0|65.535] "V" Vector__XXX
 SG_ DIF_a077_lvSupplyV m77 : 16|16@1+ (0.001,0) [0|65.535] "V" Vector__XXX
 SG_ DIF_a078_adcRefChan m78 : 16|4@1+ (1,0) [0|15] "" Vector__XXX
 SG_ DIF_a078_adcRefLowAvg m78 : 24|16@1+ (1,0) [0|65535] "" Vector__XXX
 SG_ DIF_a079_adcRefChan m79 : 16|4@1+ (1,0) [0|15] "" Vector__XXX
 SG_ DIF_a079_adcRefHighAvg m79 : 24|16@1+ (1,0) [0|65535] "" Vector__XXX
 SG_ DIF_a087_gtwCarConfig m87 : 16|1@1+ (1,0) [0|1] "" Vector__XXX
 SG_ DIF_a087_gtwTime m87 : 17|1@1+ (1,0) [0|1] "" Vector__XXX
 SG_ DIF_a087_gtwUpdateStatus m87 : 18|1@1+ (1,0) [0|1] "" Vector__XXX
 SG_ DIF_a087_gearControl m87 : 19|1@1+ (1,0) [0|1] "" Vector__XXX
 SG_ DIF_a087_carState m87 : 20|1@1+ (1,0) [0|1] "" Vector__XXX
 SG_ DIF_a090_reason m90 : 16|1@1+ (1,0) [0|1] "" Vector__XXX
 SG_ DIF_a090_systemState m90 : 17|1@1+ (1,0) [0|1] "" Vector__XXX
 SG_ DIF_a090_state m90 : 18|1@1+ (1,0) [0|1] "" Vector__XXX
 SG_ DIF_a090_locState m90 : 19|1@1+ (1,0) [0|1] "" Vector__XXX
 SG_ DIF_a090_state2 m90 : 20|1@1+ (1,0) [0|1] "" Vector__XXX
 SG_ DIF_a090_state4 m90 : 21|1@1+ (1,0) [0|1] "" Vector__XXX
 SG_ DIF_a091_ESP_brakeTorque m91 : 16|1@1+ (1,0) [0|1] "" Vector__XXX
 SG_ DIF_a091_ESP_wheelSpeeds m91 : 17|1@1+ (1,0) [0|1] "" Vector__XXX
 SG_ DIF_a091_ESP_wheelRotation m91 : 18|1@1+ (1,0) [0|1] "" Vector__XXX
 SG_ DIF_a091_ESP_motorLimits m91 : 19|1@1+ (1,0) [0|1] "" Vector__XXX
 SG_ DIF_a091_ESP_offsets m91 : 20|1@1+ (1,0) [0|1] "" Vector__XXX
 SG_ DIF_a091_ESP_status m91 : 21|1@1+ (1,0) [0|1] "" Vector__XXX
 SG_ DIF_a091_ESP_party3 m91 : 22|1@1+ (1,0) [0|1] "" Vector__XXX
 SG_ DIF_a091_ESP_redundantBrakingSta m91 : 23|1@1+ (1,0) [0|1] "" Vector__XXX
 SG_ DIF_a092_bmsStatus m92 : 16|1@1+ (1,0) [0|1] "" Vector__XXX
 SG_ DIF_a092_bmsDriveLimits m92 : 17|1@1+ (1,0) [0|1] "" Vector__XXX
 SG_ DIF_a092_bmsHvBusStatus m92 : 18|1@1+ (1,0) [0|1] "" Vector__XXX
 SG_ DIF_a092_bmsPowerAvailable m92 : 19|1@1+ (1,0) [0|1] "" Vector__XXX
 SG_ DIF_a092_bmsBmbMinMax m92 : 20|1@1+ (1,0) [0|1] "" Vector__XXX
 SG_ DIF_a092_bmsSocStatus m92 : 21|1@1+ (1,0) [0|1] "" Vector__XXX
 SG_ DIF_a092_bmsThermalStatus m92 : 22|1@1+ (1,0) [0|1] "" Vector__XXX
 SG_ DIF_a092_bmsCtrStatus m92 : 23|1@1+ (1,0) [0|1] "" Vector__XXX
 SG_ DIF_a092_bmsVoltageRegGain m92 : 24|1@1+ (1,0) [0|1] "" Vector__XXX
 SG_ DIF_a092_bmsPackConfig m92 : 25|1@1+ (1,0) [0|1] "" Vector__XXX
 SG_ DIF_a092_bmsSystemStatus m92 : 26|1@1+ (1,0) [0|1] "" Vector__XXX
 SG_ DIF_a096_const_fast m96 : 16|1@1+ (1,0) [0|1] "" Vector__XXX
 SG_ DIF_a096_text_fast m96 : 17|1@1+ (1,0) [0|1] "" Vector__XXX
 SG_ DIF_a096_text_flash m96 : 18|1@1+ (1,0) [0|1] "" Vector__XXX
 SG_ DIF_a096_mem_data m96 : 19|1@1+ (1,0) [0|1] "" Vector__XXX
 SG_ DIF_a096_mem_regs m96 : 20|1@1+ (1,0) [0|1] "" Vector__XXX
 SG_ DIF_a096_boot_flash m96 : 21|1@1+ (1,0) [0|1] "" Vector__XXX
 SG_ DIF_a096_word1 m96 : 24|16@1+ (1,0) [0|65535] "" Vector__XXX
 SG_ DIF_a096_word2 m96 : 40|16@1+ (1,0) [0|65535] "" Vector__XXX
 SG_ DIF_a097_errorType m97 : 16|3@1+ (1,0) [0|7] "" Vector__XXX
 SG_ DIF_a097_lineNumber m97 : 24|16@1+ (1,0) [0|65535] "" Vector__XXX
 SG_ DIF_a097_argument m97 : 40|16@1+ (1,0) [0|65535] "" Vector__XXX
 SG_ DIF_a098_pwmCount m98 : 16|16@1+ (1,0) [0|65535] "" Vector__XXX
 SG_ DIF_a098_fluxState m98 : 32|4@1+ (1,0) [0|15] "" Vector__XXX
 SG_ DIF_a103_fluidTorDeltaT m103 : 16|8@1- (2.007874,68.2677154541) [-188.740156546|323.267713454] "C" Vector__XXX
 SG_ DIF_a103_noFlowDetected m103 : 24|1@1+ (1,0) [0|1] "" Vector__XXX
 SG_ DIF_a103_lowFlowDetected m103 : 25|1@1+ (1,0) [0|1] "" Vector__XXX
 SG_ DIF_a103_fluidImplausible m103 : 26|1@1+ (1,0) [0|1] "" Vector__XXX
 SG_ DIF_a103_inverterTemp m103 : 27|8@1- (2.007874,68.2677154541) [-188.740156546|323.267713454] "C" Vector__XXX
 SG_ DIF_a103_rmsCurrent m103 : 35|10@1- (12.8199605942,0) [-6563.81982423|6550.99986364] "A" Vector__XXX
 SG_ DIF_a103_ambientTemp m103 : 45|7@1- (1.5873016119,11.1111106873) [-90.4761924743|111.111112237] "C" Vector__XXX
 SG_ DIF_a103_sensorTempEst m103 : 52|8@1- (1.25984251499,40.31496) [-120.944881919|200.314959404] "C" Vector__XXX
 SG_ DIF_a107_fpgaVersion m107 : 16|16@1+ (1,0) [0|65535] "" Vector__XXX
 SG_ DIF_a107_fpgaBootVersion m107 : 32|16@1+ (1,0) [0|65535] "" Vector__XXX
 SG_ DIF_a107_fpgaMasterActive m107 : 48|1@1+ (1,0) [0|1] "" Vector__XXX
 SG_ DIF_a107_fpgaFaultActive m107 : 49|1@1+ (1,0) [0|1] "" Vector__XXX
 SG_ DIF_a107_fpgaWarningActive m107 : 50|1@1+ (1,0) [0|1] "" Vector__XXX
 SG_ DIF_a108_fromState m108 : 16|8@1+ (1,0) [0|255] "" Vector__XXX
 SG_ DIF_a108_toState m108 : 24|8@1+ (1,0) [0|255] "" Vector__XXX
 SG_ DIF_a108_blockingAlert m108 : 32|8@1+ (1,0) [0|255] "" Vector__XXX
 SG_ DIF_a110_EPBL_status m110 : 16|1@1+ (1,0) [0|1] "" Vector__XXX
 SG_ DIF_a110_EPBR_status m110 : 17|1@1+ (1,0) [0|1] "" Vector__XXX
 SG_ DIF_a110_EPBL_autonomyHealth m110 : 18|1@1+ (1,0) [0|1] "" Vector__XXX
 SG_ DIF_a110_EPBR_autonomyHealth m110 : 19|1@1+ (1,0) [0|1] "" Vector__XXX
 SG_ DIF_a111_phAcalib m111 : 16|16@1+ (1,0) [0|65535] "" Vector__XXX
 SG_ DIF_a111_phBcalib m111 : 32|16@1+ (1,0) [0|65535] "" Vector__XXX
 SG_ DIF_a112_pwmSwitching m112 : 16|1@1+ (1,0) [0|1] "" Vector__XXX
 SG_ DIF_a112_gdicResetLine m112 : 17|1@1+ (1,0) [0|1] "" Vector__XXX
 SG_ DIF_a112_allOffSafeState m112 : 18|1@1+ (1,0) [0|1] "" Vector__XXX
 SG_ DIF_a112_ls3psSafeState m112 : 19|1@1+ (1,0) [0|1] "" Vector__XXX
 SG_ DIF_a112_hs3psSafeState m112 : 20|1@1+ (1,0) [0|1] "" Vector__XXX
 SG_ DIF_a112_modulationIndex m112 : 21|11@1+ (0.00048828125,0) [0|0.99951171875] "-" Vector__XXX
 SG_ DIF_a113_heatsink1Temp m113 : 16|16@1- (0.1,0) [-3276.8|3276.7] "C" Vector__XXX
 SG_ DIF_a113_heatsink2Temp m113 : 32|16@1- (0.1,0) [-3276.8|3276.7] "C" Vector__XXX
 SG_ DIF_a113_heatsink3Temp m113 : 48|16@1- (0.1,0) [-3276.8|3276.7] "C" Vector__XXX
 SG_ DIF_a117_torque m117 : 16|1@1+ (1,0) [0|1] "" Vector__XXX
 SG_ DIF_a117_slaveCommand m117 : 17|1@1+ (1,0) [0|1] "" Vector__XXX
 SG_ DIF_a117_power m117 : 18|1@1+ (1,0) [0|1] "" Vector__XXX
 SG_ DIF_a117_slaveCommand2 m117 : 19|1@1+ (1,0) [0|1] "" Vector__XXX
 SG_ DIF_a117_speed m117 : 20|1@1+ (1,0) [0|1] "" Vector__XXX
 SG_ DIF_a117_chassisControl m117 : 21|1@1+ (1,0) [0|1] "" Vector__XXX
 SG_ DIF_a117_systemStatus m117 : 22|1@1+ (1,0) [0|1] "" Vector__XXX
 SG_ DIF_a117_temperature m117 : 23|1@1+ (1,0) [0|1] "" Vector__XXX
 SG_ DIF_a117_vehicle m117 : 24|1@1+ (1,0) [0|1] "" Vector__XXX
 SG_ DIF_a117_AddTcLimit m117 : 26|1@1+ (1,0) [0|1] "" Vector__XXX
 SG_ DIF_a117_dixCommand m117 : 27|1@1+ (1,0) [0|1] "" Vector__XXX
 SG_ DIF_a117_odometerStatus m117 : 30|1@1+ (1,0) [0|1] "" Vector__XXX
 SG_ DIF_a119_hvpFaults m119 : 16|1@1+ (1,0) [0|1] "" Vector__XXX
 SG_ DIF_a120_dcLinkInfo m120 : 16|1@1+ (1,0) [0|1] "" Vector__XXX
 SG_ DIF_a121_badRegReason m121 : 16|3@1+ (1,0) [0|7] "" Vector__XXX
 SG_ DIF_a121_torqueDelta m121 : 19|13@1- (0.25,0) [-1024|1023.75] "Nm" Vector__XXX
 SG_ DIF_a121_badCurrent m121 : 32|16@1- (0.1,0) [-3276.8|3276.7] "A" Vector__XXX
 SG_ DIF_a121_badFlux m121 : 48|16@1+ (0.0001,0) [0|6.5535] "Wb" Vector__XXX
 SG_ DIF_a123_lossReason m123 : 16|3@1+ (1,0) [0|7] "" Vector__XXX
 SG_ DIF_a123_busVoltage m123 : 19|6@1+ (4,250) [250|502] "V" Vector__XXX
 SG_ DIF_a123_badFlux m123 : 25|7@1+ (0.0015,0) [0|0.1905] "Wb" Vector__XXX
 SG_ DIF_a123_lossRequest m123 : 32|7@1+ (0.1,0) [0|12.7] "kW" Vector__XXX
 SG_ DIF_a123_badCurrent m123 : 39|9@1- (10,0) [-2560|2550] "A" Vector__XXX
 SG_ DIF_a123_motorRPM m123 : 48|8@1- (150,0) [-19200|19050] "RPM" Vector__XXX
 SG_ DIF_a123_varianceD m123 : 56|4@1+ (20,0) [0|300] "A" Vector__XXX
 SG_ DIF_a123_varianceQ m123 : 60|4@1+ (20,0) [0|300] "A" Vector__XXX
 SG_ DIF_a126_limpReason m126 : 16|6@1+ (1,0) [0|63] "" Vector__XXX
 SG_ DIF_a127_gpoReason m127 : 16|4@1+ (1,0) [0|15] "" Vector__XXX
 SG_ DIF_a127_temp m127 : 24|16@1- (0.1,0) [-3276.8|3276.7] "C" Vector__XXX
 SG_ DIF_a133_capacitorTemp m133 : 16|16@1- (0.1,0) [-3276.8|3276.7] "C" Vector__XXX
 SG_ DIF_a133_badValue1 m133 : 32|16@1- (0.1,0) [-3276.8|3276.7] "C" Vector__XXX
 SG_ DIF_a133_badValue2 m133 : 48|16@1- (0.1,0) [-3276.8|3276.7] "C" Vector__XXX
 SG_ DIF_a134_wheelSpeedDiffFrL m134 : 16|12@1- (0.0625,0) [-128|127.9375] "kph" Vector__XXX
 SG_ DIF_a134_wheelSpeedDiffFrR m134 : 28|12@1- (0.0625,0) [-128|127.9375] "kph" Vector__XXX
 SG_ DIF_a134_wheelSpeedDiffReL m134 : 40|12@1- (0.0625,0) [-128|127.9375] "kph" Vector__XXX
 SG_ DIF_a134_wheelSpeedDiffReR m134 : 52|12@1- (0.0625,0) [-128|127.9375] "kph" Vector__XXX
 SG_ DIF_a136_spiError_BL m136 : 16|1@1+ (1,0) [0|1] "" Vector__XXX
 SG_ DIF_a136_crcError_BL m136 : 17|1@1+ (1,0) [0|1] "" Vector__XXX
 SG_ DIF_a136_busyError_BL m136 : 18|1@1+ (1,0) [0|1] "" Vector__XXX
 SG_ DIF_a136_spiError_BH m136 : 19|1@1+ (1,0) [0|1] "" Vector__XXX
 SG_ DIF_a136_crcError_BH m136 : 20|1@1+ (1,0) [0|1] "" Vector__XXX
 SG_ DIF_a136_busyError_BH m136 : 21|1@1+ (1,0) [0|1] "" Vector__XXX
 SG_ DIF_a136_spiError_CL m136 : 22|1@1+ (1,0) [0|1] "" Vector__XXX
 SG_ DIF_a136_crcError_CL m136 : 23|1@1+ (1,0) [0|1] "" Vector__XXX
 SG_ DIF_a136_busyError_CL m136 : 24|1@1+ (1,0) [0|1] "" Vector__XXX
 SG_ DIF_a136_spiError_CH m136 : 25|1@1+ (1,0) [0|1] "" Vector__XXX
 SG_ DIF_a136_crcError_CH m136 : 26|1@1+ (1,0) [0|1] "" Vector__XXX
 SG_ DIF_a136_busyError_CH m136 : 27|1@1+ (1,0) [0|1] "" Vector__XXX
 SG_ DIF_a136_spiError_AL m136 : 28|1@1+ (1,0) [0|1] "" Vector__XXX
 SG_ DIF_a136_crcError_AL m136 : 29|1@1+ (1,0) [0|1] "" Vector__XXX
 SG_ DIF_a136_busyError_AL m136 : 30|1@1+ (1,0) [0|1] "" Vector__XXX
 SG_ DIF_a136_spiError_AH m136 : 31|1@1+ (1,0) [0|1] "" Vector__XXX
 SG_ DIF_a136_crcError_AH m136 : 32|1@1+ (1,0) [0|1] "" Vector__XXX
 SG_ DIF_a136_busyError_AH m136 : 33|1@1+ (1,0) [0|1] "" Vector__XXX
 SG_ DIF_a144_autopilot m144 : 16|1@1+ (1,0) [0|1] "" Vector__XXX
 SG_ DIF_a144_chassisType m144 : 17|1@1+ (1,0) [0|1] "" Vector__XXX
 SG_ DIF_a144_drivetrainType m144 : 18|1@1+ (1,0) [0|1] "" Vector__XXX
 SG_ DIF_a144_packEnergy m144 : 19|1@1+ (1,0) [0|1] "" Vector__XXX
 SG_ DIF_a144_packPerformanceDeviatio m144 : 20|1@1+ (1,0) [0|1] "" Vector__XXX
 SG_ DIF_a144_performancePackage m144 : 21|1@1+ (1,0) [0|1] "" Vector__XXX
 SG_ DIF_a144_vdcType m144 : 22|1@1+ (1,0) [0|1] "" Vector__XXX
 SG_ DIF_a144_brakeHWType m144 : 23|1@1+ (1,0) [0|1] "" Vector__XXX
 SG_ DIF_a144_inverterHardware m144 : 24|1@1+ (1,0) [0|1] "" Vector__XXX
 SG_ DIF_a144_cabinPTCHeaterType m144 : 25|1@1+ (1,0) [0|1] "" Vector__XXX
 SG_ DIF_a144_frunkLatchType m144 : 26|1@1+ (1,0) [0|1] "" Vector__XXX
 SG_ DIF_a144_platformMaxBusVoltage m144 : 27|1@1+ (1,0) [0|1] "" Vector__XXX
 SG_ DIF_a144_oilPump1HwType m144 : 28|1@1+ (1,0) [0|1] "" Vector__XXX
 SG_ DIF_a144_oilPump2HwType m144 : 29|1@1+ (1,0) [0|1] "" Vector__XXX
 SG_ DIF_a144_heatsinkType m144 : 30|1@1+ (1,0) [0|1] "" Vector__XXX
 SG_ DIF_a144_softPerformanceLimit m144 : 31|1@1+ (1,0) [0|1] "" Vector__XXX
 SG_ DIF_a144_brakeActuationType m144 : 32|1@1+ (1,0) [0|1] "" Vector__XXX
 SG_ DIF_a144_dasHw m144 : 33|1@1+ (1,0) [0|1] "" Vector__XXX
 SG_ DIF_a144_powerLiftgateType m144 : 34|1@1+ (1,0) [0|1] "" Vector__XXX
 SG_ DIF_a144_chassisSubType m144 : 35|1@1+ (1,0) [0|1] "" Vector__XXX
 SG_ DIF_a144_autonomyFeatureType m144 : 36|1@1+ (1,0) [0|1] "" Vector__XXX
 SG_ DIF_a147_overtorque1UsedCount m147 : 16|8@1+ (1,0) [0|255] "" Vector__XXX
 SG_ DIF_a147_overtorque2UsedCount m147 : 24|10@1+ (1,0) [0|1023] "" Vector__XXX
 SG_ DIF_a147_accumulatedWear m147 : 34|10@1+ (0.005,0) [0|5.115] "1" Vector__XXX
 SG_ DIF_a147_wearIsValid m147 : 44|1@1+ (1,0) [0|1] "" Vector__XXX
 SG_ DIF_a149_flow m149 : 16|8@1+ (0.1,0) [0|25.4] "LPM" Vector__XXX
 SG_ DIF_a149_voltage m149 : 24|8@1+ (0.1,0) [0|25.5] "V" Vector__XXX
 SG_ DIF_a149_temperature m149 : 32|8@1+ (1,-40) [-40|215] "DegC" Vector__XXX
 SG_ DIF_a149_state m149 : 40|3@1+ (1,0) [0|6] "" Vector__XXX
 SG_ DIF_a149_fluidTempSNA m149 : 43|1@1+ (1,0) [0|1] "" Vector__XXX
 SG_ DIF_a149_insufficientFlow m149 : 44|1@1+ (1,0) [0|1] "" Vector__XXX
 SG_ DIF_a149_motorOpenPhase m149 : 45|1@1+ (1,0) [0|1] "" Vector__XXX
 SG_ DIF_a149_motorShorted m149 : 46|1@1+ (1,0) [0|1] "" Vector__XXX
 SG_ DIF_a149_motorFlowSNA m149 : 47|1@1+ (1,0) [0|1] "" Vector__XXX
 SG_ DIF_a149_responseError m149 : 48|1@1+ (1,0) [0|1] "" Vector__XXX
 SG_ DIF_a149_pcbaID m149 : 49|1@1+ (1,0) [0|1] "" Vector__XXX
 SG_ DIF_a150_vBatRawMinusFiltered m150 : 16|10@1- (1,0) [-512|511] "V" Vector__XXX
 SG_ DIF_a150_vBatFilteredRate m150 : 32|8@1- (100,0) [-12800|12700] "V/s" Vector__XXX
 SG_ DIF_a150_elapsedMs m150 : 40|8@1+ (1,0) [0|255] "ms" Vector__XXX
 SG_ DIF_a150_energy m150 : 48|16@1+ (1,0) [0|65535] "J" Vector__XXX
 SG_ DIF_a152_errorType m152 : 16|3@1+ (1,0) [0|7] "" Vector__XXX
 SG_ DIF_a152_frameId m152 : 24|8@1+ (1,0) [0|255] "" Vector__XXX
 SG_ DIF_a152_badValue m152 : 32|8@1+ (1,0) [0|255] "" Vector__XXX
 SG_ DIF_a152_expectedValue m152 : 40|8@1+ (1,0) [0|255] "" Vector__XXX
 SG_ DIF_a154_motorRPM m154 : 16|16@1- (1,0) [-32768|32767] "RPM" Vector__XXX
 SG_ DIF_a154_phaseError m154 : 32|8@1- (0.004,0) [-0.512|0.508] "1" Vector__XXX
 SG_ DIF_a154_commonGain m154 : 40|8@1+ (0.02,0) [0|5.1] "1" Vector__XXX
 SG_ DIF_a154_noCalibration m154 : 48|1@1+ (1,0) [0|1] "" Vector__XXX
 SG_ DIF_a154_noPhaseLock m154 : 49|1@1+ (1,0) [0|1] "" Vector__XXX
 SG_ DIF_a154_noCarrier m154 : 50|1@1+ (1,0) [0|1] "" Vector__XXX
 SG_ DIF_a154_notReady m154 : 51|1@1+ (1,0) [0|1] "" Vector__XXX
 SG_ DIF_a154_errorTableInvalid m154 : 52|1@1+ (1,0) [0|1] "" Vector__XXX
 SG_ DIF_a154_carrierOffset m154 : 53|1@1+ (1,0) [0|1] "" Vector__XXX
 SG_ DIF_a154_trackerIrrational m154 : 54|1@1+ (1,0) [0|1] "" Vector__XXX
 SG_ DIF_a154_claMIA m154 : 55|1@1+ (1,0) [0|1] "" Vector__XXX
 SG_ DIF_a155_sensors m155 : 16|1@1+ (1,0) [0|1] "" Vector__XXX
 SG_ DIF_a155_coolant m155 : 17|1@1+ (1,0) [0|1] "" Vector__XXX
 SG_ DIF_a155_LVPowerState m155 : 18|1@1+ (1,0) [0|1] "" Vector__XXX
 SG_ DIF_a155_vehicleStatus m155 : 19|1@1+ (1,0) [0|1] "" Vector__XXX
 SG_ DIF_a155_status m155 : 20|1@1+ (1,0) [0|1] "" Vector__XXX
 SG_ DIF_a155_leftDoorStatus m155 : 21|1@1+ (1,0) [0|1] "" Vector__XXX
 SG_ DIF_a155_rightDoorStatus m155 : 22|1@1+ (1,0) [0|1] "" Vector__XXX
 SG_ DIF_a155_vcleftSwitchStatus m155 : 23|1@1+ (1,0) [0|1] "" Vector__XXX
 SG_ DIF_a155_restraintStatus m155 : 24|1@1+ (1,0) [0|1] "" Vector__XXX
 SG_ DIF_a155_systemStatus m155 : 25|1@1+ (1,0) [0|1] "" Vector__XXX
 SG_ DIF_a155_prndStatus m155 : 26|1@1+ (1,0) [0|1] "" Vector__XXX
 SG_ DIF_a155_liftgateStatus m155 : 27|1@1+ (1,0) [0|1] "" Vector__XXX
 SG_ DIF_a157_RCM_inertial1 m157 : 16|1@1+ (1,0) [0|1] "" Vector__XXX
 SG_ DIF_a157_RCM_inertial2 m157 : 17|1@1+ (1,0) [0|1] "" Vector__XXX
 SG_ DIF_a158_IBST_party1 m158 : 16|1@1+ (1,0) [0|1] "" Vector__XXX
 SG_ DIF_a158_BUS1_IBST_status m158 : 17|1@1+ (1,0) [0|1] "" Vector__XXX
 SG_ DIF_a158_BUS2_IBST_status m158 : 18|1@1+ (1,0) [0|1] "" Vector__XXX
 SG_ DIF_a158_IBST_redundantBrakingSt m158 : 19|1@1+ (1,0) [0|1] "" Vector__XXX
 SG_ DIF_a160_vBatRawMinusFiltered m160 : 16|10@1- (1,0) [-512|511] "V" Vector__XXX
 SG_ DIF_a160_vBatFilteredRate m160 : 32|8@1- (100,0) [-12800|12700] "V/s" Vector__XXX
 SG_ DIF_a160_elapsedMs m160 : 40|8@1+ (1,0) [0|255] "ms" Vector__XXX
 SG_ DIF_a160_energy m160 : 48|16@1+ (1,0) [0|65535] "J" Vector__XXX
 SG_ DIF_a161_EPAS3P_sysStatus m161 : 16|1@1+ (1,0) [0|1] "" Vector__XXX
 SG_ DIF_a161_EPAS3P_angleCalib m161 : 17|1@1+ (1,0) [0|1] "" Vector__XXX
 SG_ DIF_a172_statorTemp1 m172 : 16|16@1- (0.1,0) [-3276.8|3276.7] "DegC" Vector__XXX
 SG_ DIF_a172_statorTemp2 m172 : 32|16@1- (0.1,0) [-3276.8|3276.7] "DegC" Vector__XXX
 SG_ DIF_a202_reason m202 : 16|4@1+ (1,0) [0|15] "" Vector__XXX
 SG_ DIF_a202_movement m202 : 20|9@1+ (0.005,0) [0|2.555] "m" Vector__XXX
 SG_ DIF_a202_sysStateExitCondition m202 : 32|5@1+ (1,0) [0|31] "" Vector__XXX
 SG_ DIF_a233_missedMsgCount m233 : 16|4@1+ (1,0) [0|15] "" Vector__XXX
 SG_ DIF_a233_serviceModeActive m233 : 20|1@1+ (1,0) [0|1] "" Vector__XXX
 SG_ DIF_a234_PCS_dcdcStatus m234 : 16|1@1+ (1,0) [0|1] "" Vector__XXX
 SG_ DIF_a236_states m236 : 16|1@1+ (1,0) [0|1] "" Vector__XXX
 SG_ DIF_a240_shortedSwitches m240 : 16|6@1+ (1,0) [0|63] "" Vector__XXX
 SG_ DIF_a240_primaryPattern m240 : 22|6@1+ (1,0) [0|63] "" Vector__XXX
 SG_ DIF_a240_secondaryPattern m240 : 28|6@1+ (1,0) [0|63] "" Vector__XXX
 SG_ DIF_a240_fuseA_I2t m240 : 34|6@1+ (8,0) [0|504] "A^2s" Vector__XXX
 SG_ DIF_a240_fuseB_I2t m240 : 40|6@1+ (8,0) [0|504] "A^2s" Vector__XXX
 SG_ DIF_a240_primaryTimeout m240 : 46|1@1+ (1,0) [0|1] "" Vector__XXX
 SG_ DIF_a240_secondaryTimeout m240 : 47|1@1+ (1,0) [0|1] "" Vector__XXX
 SG_ DIF_a240_primNoCurrentA m240 : 48|1@1+ (1,0) [0|1] "" Vector__XXX
 SG_ DIF_a240_primNoCurrentB m240 : 49|1@1+ (1,0) [0|1] "" Vector__XXX
 SG_ DIF_a240_secNoCurrentA m240 : 50|1@1+ (1,0) [0|1] "" Vector__XXX
 SG_ DIF_a240_secNoCurrentB m240 : 51|1@1+ (1,0) [0|1] "" Vector__XXX
 SG_ DIF_a240_primaryDutyCycle m240 : 52|5@1+ (1,0) [0|31] "" Vector__XXX
 SG_ DIF_a240_secondaryDutyCycle m240 : 57|5@1+ (1,0) [0|31] "" Vector__XXX
 SG_ DIF_a240_confNoCurrentDetected m240 : 62|1@1+ (1,0) [0|1] "" Vector__XXX
 SG_ DIF_a240_secondaryStrategy3ps m240 : 63|1@1+ (1,0) [0|1] "" Vector__XXX
 SG_ DIF_a242_RotorOffset m242 : 16|1@1+ (1,0) [0|1] "" Vector__XXX
 SG_ DIF_a242_RotorFlux m242 : 17|1@1+ (1,0) [0|1] "" Vector__XXX
 SG_ DIF_a242_ResolverError m242 : 18|1@1+ (1,0) [0|1] "" Vector__XXX
 SG_ DIF_a244_desatHighSide m244 : 16|1@1+ (1,0) [0|1] "" Vector__XXX
 SG_ DIF_a244_desatLowSide m244 : 17|1@1+ (1,0) [0|1] "" Vector__XXX
 SG_ DIF_a244_singleSwitchShort m244 : 18|1@1+ (1,0) [0|1] "" Vector__XXX
 SG_ DIF_a244_flybackFault m244 : 19|1@1+ (1,0) [0|1] "" Vector__XXX
 SG_ DIF_a244_postShortTestFailed m244 : 20|1@1+ (1,0) [0|1] "" Vector__XXX
 SG_ DIF_a244_udsSelfTest m244 : 21|1@1+ (1,0) [0|1] "" Vector__XXX
 SG_ DIF_a244_irSensorV m244 : 24|6@1+ (0.1,0) [0|6.3] "V" Vector__XXX
 SG_ DIF_a244_gateDriveICUndervoltage m244 : 30|1@1+ (1,0) [0|1] "" Vector__XXX
 SG_ DIF_a244_plausibleSingleSwitchSh m244 : 31|1@1+ (1,0) [0|1] "" Vector__XXX
 SG_ DIF_a244_delay m244 : 32|16@1+ (1,0) [0|65535] "us" Vector__XXX
 SG_ DIF_a246_atSpeedDIResetCount m246 : 16|4@1+ (1,4294967295) [4294967295|4294967310] "" Vector__XXX
 SG_ DIF_a246_didPMCauseSwitchOf_0001 m246 : 20|1@1+ (1,0) [0|1] "" Vector__XXX
 SG_ DIF_a246_didPMCauseSwitchOffPath m246 : 21|1@1+ (1,0) [0|1] "" Vector__XXX
 SG_ DIF_a246_currentSensorRational m246 : 22|1@1+ (1,0) [0|1] "" Vector__XXX
 SG_ DIF_a246_observerDetectedSw_0001 m246 : 23|1@1+ (1,0) [0|1] "" Vector__XXX
 SG_ DIF_a246_observerDetectedSwitchO m246 : 24|1@1+ (1,0) [0|1] "" Vector__XXX
 SG_ DIF_a246_hvIsGood m246 : 25|1@1+ (1,0) [0|1] "" Vector__XXX
 SG_ DIF_a246_lvIsGood m246 : 26|1@1+ (1,0) [0|1] "" Vector__XXX
 SG_ DIF_a246_codeBranch m246 : 27|2@1+ (1,0) [0|3] "" Vector__XXX
 SG_ DIF_a246_motorRPM m246 : 32|8@1- (150,0) [-19200|19050] "RPM" Vector__XXX
 SG_ DIF_a246_eepromOffsetIa m246 : 40|6@1- (0.763,0) [-24.416|23.653] "A" Vector__XXX
 SG_ DIF_a246_eepromOffsetIb m246 : 48|6@1- (0.763,0) [-24.416|23.653] "A" Vector__XXX
 SG_ DIF_a246_soptPreviouslyPassed m246 : 54|1@1+ (1,0) [0|1] "" Vector__XXX
 SG_ DIF_a246_lowSpeedRecoveryEnabled m246 : 55|1@1+ (1,0) [0|1] "" Vector__XXX
 SG_ DIF_a247_rotorOffsetEst m247 : 16|10@1- (0.05,0) [-25.6|25.55] "degrees" Vector__XXX
 SG_ DIF_a247_motorRPM m247 : 32|16@1- (1,0) [-32768|32767] "RPM" Vector__XXX
 SG_ DIF_a247_torqueMotor m247 : 48|16@1- (1,0) [-32768|32767] "Nm" Vector__XXX
 SG_ DIF_a251_oilFlow m251 : 16|8@1+ (0.1,0) [0|25.4] "LPM" Vector__XXX
 SG_ DIF_a251_oilTemperature m251 : 24|8@1+ (1,-40) [-40|214] "DegC" Vector__XXX
 SG_ DIF_a251_dcVoltage m251 : 32|8@1+ (0.3,0) [0|76.2] "V" Vector__XXX
 SG_ DIF_a251_dcCurrent m251 : 40|8@1+ (0.1,0) [0|25.4] "A" Vector__XXX
 SG_ DIF_a251_phaseCurrent m251 : 48|8@1+ (0.1,0) [0|25.4] "A" Vector__XXX
 SG_ DIF_a251_leadAngle m251 : 56|4@1+ (1.875,0) [0|28.125] "degrees" Vector__XXX
 SG_ DIF_a251_reason m251 : 60|3@1+ (1,0) [0|7] "" Vector__XXX
 SG_ DIF_a253_voltage m253 : 16|14@1+ (0.002,0) [0|32.766] "V" Vector__XXX
 SG_ DIF_a253_reason m253 : 30|2@1+ (1,0) [0|3] "" Vector__XXX

BO_ 854 DIF_alertMatrix: 8 DIF
 SG_ DIF_matrixIndex M : 0|4@1+ (1,0) [0|15] "" Vector__XXX
 SG_ DIF_a001_hwPhaseAgateDrive m0 : 4|1@1+ (1,0) [0|1] "" Vector__XXX
 SG_ DIF_a002_hwPhaseBgateDrive m0 : 5|1@1+ (1,0) [0|1] "" Vector__XXX
 SG_ DIF_a003_hwPhaseCgateDrive m0 : 6|1@1+ (1,0) [0|1] "" Vector__XXX
 SG_ DIF_a004_hwPhaseApeak m0 : 7|1@1+ (1,0) [0|1] "" Vector__XXX
 SG_ DIF_a005_hwPhaseBpeak m0 : 8|1@1+ (1,0) [0|1] "" Vector__XXX
 SG_ DIF_a006_hwPhaseCpeak m0 : 9|1@1+ (1,0) [0|1] "" Vector__XXX
 SG_ DIF_a007_statorAnomalyDetected m0 : 10|1@1+ (1,0) [0|1] "" Vector__XXX
 SG_ DIF_a008_hwEncoderA m0 : 11|1@1+ (1,0) [0|1] "" Vector__XXX
 SG_ DIF_a009_hwEncoderB m0 : 12|1@1+ (1,0) [0|1] "" Vector__XXX
 SG_ DIF_a010_unintendedReset m0 : 13|1@1+ (1,0) [0|1] "" Vector__XXX
 SG_ DIF_a011_swPowerStageNotReady m0 : 14|1@1+ (1,0) [0|1] "" Vector__XXX
 SG_ DIF_a012_hvilNotClosed m0 : 15|1@1+ (1,0) [0|1] "" Vector__XXX
 SG_ DIF_a013_eccError m0 : 16|1@1+ (1,0) [0|1] "" Vector__XXX
 SG_ DIF_a014_activeDamping m0 : 17|1@1+ (1,0) [0|1] "" Vector__XXX
 SG_ DIF_a015_mechSafeStateAnomaly m0 : 18|1@1+ (1,0) [0|1] "" Vector__XXX
 SG_ DIF_a016_safeStateApplied m0 : 19|1@1+ (1,0) [0|1] "" Vector__XXX
 SG_ DIF_a017_hwPedalMonitor m0 : 20|1@1+ (1,0) [0|1] "" Vector__XXX
 SG_ DIF_a018_hwLVSupplyUV m0 : 21|1@1+ (1,0) [0|1] "" Vector__XXX
 SG_ DIF_a020_hwMotorEncoder m0 : 23|1@1+ (1,0) [0|1] "" Vector__XXX
 SG_ DIF_a021_hwBusOV m0 : 24|1@1+ (1,0) [0|1] "" Vector__XXX
 SG_ DIF_a022_hw5vSupplyUV m0 : 25|1@1+ (1,0) [0|1] "" Vector__XXX
 SG_ DIF_a024_selfTest m0 : 27|1@1+ (1,0) [0|1] "" Vector__XXX
 SG_ DIF_a025_phaseApeak m0 : 28|1@1+ (1,0) [0|1] "" Vector__XXX
 SG_ DIF_a026_phaseBpeak m0 : 29|1@1+ (1,0) [0|1] "" Vector__XXX
 SG_ DIF_a027_phaseCpeak m0 : 30|1@1+ (1,0) [0|1] "" Vector__XXX
 SG_ DIF_a028_phaseArms m0 : 31|1@1+ (1,0) [0|1] "" Vector__XXX
 SG_ DIF_a029_phaseBrms m0 : 32|1@1+ (1,0) [0|1] "" Vector__XXX
 SG_ DIF_a030_phaseCrms m0 : 33|1@1+ (1,0) [0|1] "" Vector__XXX
 SG_ DIF_a031_phaseAcurrentOffset m0 : 34|1@1+ (1,0) [0|1] "" Vector__XXX
 SG_ DIF_a032_phaseBcurrentOffset m0 : 35|1@1+ (1,0) [0|1] "" Vector__XXX
 SG_ DIF_a033_phaseAcurrentSensor m0 : 36|1@1+ (1,0) [0|1] "" Vector__XXX
 SG_ DIF_a034_phaseBcurrentSensor m0 : 37|1@1+ (1,0) [0|1] "" Vector__XXX
 SG_ DIF_a035_phaseCurrentBalance m0 : 38|1@1+ (1,0) [0|1] "" Vector__XXX
 SG_ DIF_a036_busOV m0 : 39|1@1+ (1,0) [0|1] "" Vector__XXX
 SG_ DIF_a037_busUV m0 : 40|1@1+ (1,0) [0|1] "" Vector__XXX
 SG_ DIF_a038_busVsensor m0 : 41|1@1+ (1,0) [0|1] "" Vector__XXX
 SG_ DIF_a039_exceptionUndefinedInstr m0 : 42|1@1+ (1,0) [0|1] "" Vector__XXX
 SG_ DIF_a040_difMIA m0 : 43|1@1+ (1,0) [0|1] "" Vector__XXX
 SG_ DIF_a041_sdcMIA m0 : 44|1@1+ (1,0) [0|1] "" Vector__XXX
 SG_ DIF_a042_inletSensor m0 : 45|1@1+ (1,0) [0|1] "" Vector__XXX
 SG_ DIF_a043_outletOT m0 : 46|1@1+ (1,0) [0|1] "" Vector__XXX
 SG_ DIF_a044_outletUT m0 : 47|1@1+ (1,0) [0|1] "" Vector__XXX
 SG_ DIF_a045_outletSensor m0 : 48|1@1+ (1,0) [0|1] "" Vector__XXX
 SG_ DIF_a046_statorOT m0 : 49|1@1+ (1,0) [0|1] "" Vector__XXX
 SG_ DIF_a047_statorSensor1 m0 : 50|1@1+ (1,0) [0|1] "" Vector__XXX
 SG_ DIF_a048_statorSensor2 m0 : 51|1@1+ (1,0) [0|1] "" Vector__XXX
 SG_ DIF_a049_statorSensorDiff m0 : 52|1@1+ (1,0) [0|1] "" Vector__XXX
 SG_ DIF_a050_noStatorSensor m0 : 53|1@1+ (1,0) [0|1] "" Vector__XXX
 SG_ DIF_a052_dirMIA m0 : 55|1@1+ (1,0) [0|1] "" Vector__XXX
 SG_ DIF_a053_unexpectedLatchState m0 : 56|1@1+ (1,0) [0|1] "" Vector__XXX
 SG_ DIF_a054_driveInverterOT m0 : 57|1@1+ (1,0) [0|1] "" Vector__XXX
 SG_ DIF_a055_trqCrossCheck m0 : 58|1@1+ (1,0) [0|1] "" Vector__XXX
 SG_ DIF_a056_ambientOT m0 : 59|1@1+ (1,0) [0|1] "" Vector__XXX
 SG_ DIF_a057_ambientUT m0 : 60|1@1+ (1,0) [0|1] "" Vector__XXX
 SG_ DIF_a058_ambientSensor m0 : 61|1@1+ (1,0) [0|1] "" Vector__XXX
 SG_ DIF_a059_heatsinkOT m0 : 62|1@1+ (1,0) [0|1] "" Vector__XXX
 SG_ DIF_a060_heatsinkUT m0 : 63|1@1+ (1,0) [0|1] "" Vector__XXX
 SG_ DIF_a061_heatsinkSensor m1 : 4|1@1+ (1,0) [0|1] "" Vector__XXX
 SG_ DIF_a062_systemLimpMode m1 : 5|1@1+ (1,0) [0|1] "" Vector__XXX
 SG_ DIF_a063_bbMIA m1 : 6|1@1+ (1,0) [0|1] "" Vector__XXX
 SG_ DIF_a064_torqueIntervention m1 : 7|1@1+ (1,0) [0|1] "" Vector__XXX
 SG_ DIF_a065_canHardwareBusB m1 : 8|1@1+ (1,0) [0|1] "" Vector__XXX
 SG_ DIF_a066_canDataBusB m1 : 9|1@1+ (1,0) [0|1] "" Vector__XXX
 SG_ DIF_a067_canOverrunBusB m1 : 10|1@1+ (1,0) [0|1] "" Vector__XXX
 SG_ DIF_a069_rotorTempLimit m1 : 12|1@1+ (1,0) [0|1] "" Vector__XXX
 SG_ DIF_a070_udsTransactionInitiated m1 : 13|1@1+ (1,0) [0|1] "" Vector__XXX
 SG_ DIF_a071_busDisconnected m1 : 14|1@1+ (1,0) [0|1] "" Vector__XXX
 SG_ DIF_a072_gateDriveFaultCounter m1 : 15|1@1+ (1,0) [0|1] "" Vector__XXX
 SG_ DIF_a073_motorSpeed m1 : 16|1@1+ (1,0) [0|1] "" Vector__XXX
 SG_ DIF_a074_motorEncoder m1 : 17|1@1+ (1,0) [0|1] "" Vector__XXX
 SG_ DIF_a075_motorSpeedMismatch m1 : 18|1@1+ (1,0) [0|1] "" Vector__XXX
 SG_ DIF_a076_lvSupplyOV m1 : 19|1@1+ (1,0) [0|1] "" Vector__XXX
 SG_ DIF_a077_lvSupplyUV m1 : 20|1@1+ (1,0) [0|1] "" Vector__XXX
 SG_ DIF_a078_adcRefLow m1 : 21|1@1+ (1,0) [0|1] "" Vector__XXX
 SG_ DIF_a079_adcRefHigh m1 : 22|1@1+ (1,0) [0|1] "" Vector__XXX
 SG_ DIF_a084_eccTestData0 m1 : 27|1@1+ (1,0) [0|1] "" Vector__XXX
 SG_ DIF_d085_driveInverterBoardFailu m1 : 28|1@1+ (1,0) [0|1] "" Vector__XXX
 SG_ DIF_a086_activeDischargeOn m1 : 29|1@1+ (1,0) [0|1] "" Vector__XXX
 SG_ DIF_a087_gtwMIA m1 : 30|1@1+ (1,0) [0|1] "" Vector__XXX
 SG_ DIF_a088_uiMIA m1 : 31|1@1+ (1,0) [0|1] "" Vector__XXX
 SG_ DIF_d089_invalidTorqueCommand m1 : 32|1@1+ (1,0) [0|1] "" Vector__XXX
 SG_ DIF_a090_pmMIA m1 : 33|1@1+ (1,0) [0|1] "" Vector__XXX
 SG_ DIF_a091_espMIA m1 : 34|1@1+ (1,0) [0|1] "" Vector__XXX
 SG_ DIF_a092_bmsMIA m1 : 35|1@1+ (1,0) [0|1] "" Vector__XXX
 SG_ DIF_a093_canHardwareBusA m1 : 36|1@1+ (1,0) [0|1] "" Vector__XXX
 SG_ DIF_a094_canDataBusA m1 : 37|1@1+ (1,0) [0|1] "" Vector__XXX
 SG_ DIF_a095_canOverrunBusA m1 : 38|1@1+ (1,0) [0|1] "" Vector__XXX
 SG_ DIF_a096_memoryError m1 : 39|1@1+ (1,0) [0|1] "" Vector__XXX
 SG_ DIF_a097_eepromError m1 : 40|1@1+ (1,0) [0|1] "" Vector__XXX
 SG_ DIF_a098_intTimeTooLong m1 : 41|1@1+ (1,0) [0|1] "" Vector__XXX
 SG_ DIF_a099_threadOverrun m1 : 42|1@1+ (1,0) [0|1] "" Vector__XXX
 SG_ DIF_a100_assertion m1 : 43|1@1+ (1,0) [0|1] "" Vector__XXX
 SG_ DIF_a101_eccTestData1 m1 : 44|1@1+ (1,0) [0|1] "" Vector__XXX
 SG_ DIF_a102_exceptionPrefetchAbort m1 : 45|1@1+ (1,0) [0|1] "" Vector__XXX
 SG_ DIF_a103_lowFlow m1 : 46|1@1+ (1,0) [0|1] "" Vector__XXX
 SG_ DIF_d104_resetUnintended m1 : 47|1@1+ (1,0) [0|1] "" Vector__XXX
 SG_ DIF_d105_busVoltageSensorIssue m1 : 48|1@1+ (1,0) [0|1] "" Vector__XXX
 SG_ DIF_a106_idleTaskStarving m1 : 49|1@1+ (1,0) [0|1] "" Vector__XXX
 SG_ DIF_a107_fpgaError m1 : 50|1@1+ (1,0) [0|1] "" Vector__XXX
 SG_ DIF_a108_stateTrans m1 : 51|1@1+ (1,0) [0|1] "" Vector__XXX
 SG_ DIF_a109_ahbWriteError m1 : 52|1@1+ (1,0) [0|1] "" Vector__XXX
 SG_ DIF_a110_brakeMIA m1 : 53|1@1+ (1,0) [0|1] "" Vector__XXX
 SG_ DIF_a111_badPhaseSensorCalib m1 : 54|1@1+ (1,0) [0|1] "" Vector__XXX
 SG_ DIF_a112_noPhaseCurrent m1 : 55|1@1+ (1,0) [0|1] "" Vector__XXX
 SG_ DIF_a113_noFuncHeatsinkSensor m1 : 56|1@1+ (1,0) [0|1] "" Vector__XXX
 SG_ DIF_a114_exceptionDataAbort m1 : 57|1@1+ (1,0) [0|1] "" Vector__XXX
 SG_ DIF_a115_exceptionDataAbort2 m1 : 58|1@1+ (1,0) [0|1] "" Vector__XXX
 SG_ DIF_a116_highSpeedWearCounter m1 : 59|1@1+ (1,0) [0|1] "" Vector__XXX
 SG_ DIF_a117_diMIA m1 : 60|1@1+ (1,0) [0|1] "" Vector__XXX
 SG_ DIF_d118_oilPumpCommsLost m1 : 61|1@1+ (1,0) [0|1] "" Vector__XXX
 SG_ DIF_a119_hvpMIA m1 : 62|1@1+ (1,0) [0|1] "" Vector__XXX
 SG_ DIF_a120_hvlinkMIA m1 : 63|1@1+ (1,0) [0|1] "" Vector__XXX
 SG_ DIF_a121_motorControlRegulation m2 : 4|1@1+ (1,0) [0|1] "" Vector__XXX
 SG_ DIF_a122_highStackUsage m2 : 5|1@1+ (1,0) [0|1] "" Vector__XXX
 SG_ DIF_a123_lossMotorControl m2 : 6|1@1+ (1,0) [0|1] "" Vector__XXX
 SG_ DIF_d124_oilPumpServiceRequired m2 : 7|1@1+ (1,0) [0|1] "" Vector__XXX
 SG_ DIF_d125_currentSensorIssue m2 : 8|1@1+ (1,0) [0|1] "" Vector__XXX
 SG_ DIF_a126_limpMode m2 : 9|1@1+ (1,0) [0|1] "" Vector__XXX
 SG_ DIF_a127_gracefulPowerOff m2 : 10|1@1+ (1,0) [0|1] "" Vector__XXX
 SG_ DIF_a128_fpgaVersionMismatch m2 : 11|1@1+ (1,0) [0|1] "" Vector__XXX
 SG_ DIF_d129_oilPumpIssue m2 : 12|1@1+ (1,0) [0|1] "" Vector__XXX
 SG_ DIF_d130_positionSensorIssue m2 : 13|1@1+ (1,0) [0|1] "" Vector__XXX
 SG_ DIF_d131_currentSensorOffset m2 : 14|1@1+ (1,0) [0|1] "" Vector__XXX
 SG_ DIF_d132_busUVIssue m2 : 15|1@1+ (1,0) [0|1] "" Vector__XXX
 SG_ DIF_a133_capacitorOT m2 : 16|1@1+ (1,0) [0|1] "" Vector__XXX
 SG_ DIF_a134_wheelSpeedIrrational m2 : 17|1@1+ (1,0) [0|1] "" Vector__XXX
 SG_ DIF_d135_rotatedStator m2 : 18|1@1+ (1,0) [0|1] "" Vector__XXX
 SG_ DIF_a136_spiError m2 : 19|1@1+ (1,0) [0|1] "" Vector__XXX
 SG_ DIF_d137_currentSensorOutOfRange m2 : 20|1@1+ (1,0) [0|1] "" Vector__XXX
 SG_ DIF_d138_inverterLVPowerSupplyLo m2 : 21|1@1+ (1,0) [0|1] "" Vector__XXX
 SG_ DIF_d141_coolingSystemIssue m2 : 24|1@1+ (1,0) [0|1] "" Vector__XXX
 SG_ DIF_a142_highLashAngle m2 : 25|1@1+ (1,0) [0|1] "" Vector__XXX
 SG_ DIF_d143_wheelSpeedCorrelationIs m2 : 26|1@1+ (1,0) [0|1] "" Vector__XXX
 SG_ DIF_a144_configMismatch m2 : 27|1@1+ (1,0) [0|1] "" Vector__XXX
 SG_ DIF_a147_highTorqueWearLimit m2 : 30|1@1+ (1,0) [0|1] "" Vector__XXX
 SG_ DIF_a148_burnInCycleEnded m2 : 31|1@1+ (1,0) [0|1] "" Vector__XXX
 SG_ DIF_a149_oilPumpFailure m2 : 32|1@1+ (1,0) [0|1] "" Vector__XXX
 SG_ DIF_a150_busVD m2 : 33|1@1+ (1,0) [0|1] "" Vector__XXX
 SG_ DIF_a151_shockTorqueLimiter m2 : 34|1@1+ (1,0) [0|1] "" Vector__XXX
 SG_ DIF_a152_linError m2 : 35|1@1+ (1,0) [0|1] "" Vector__XXX
 SG_ DIF_a153_oilPumpDiagnostics m2 : 36|1@1+ (1,0) [0|1] "" Vector__XXX
 SG_ DIF_a154_resolver m2 : 37|1@1+ (1,0) [0|1] "" Vector__XXX
 SG_ DIF_a155_vcfrontMIA m2 : 38|1@1+ (1,0) [0|1] "" Vector__XXX
 SG_ DIF_a156_currentObserver m2 : 39|1@1+ (1,0) [0|1] "" Vector__XXX
 SG_ DIF_a157_rcmMIA m2 : 40|1@1+ (1,0) [0|1] "" Vector__XXX
 SG_ DIF_a158_ibstMIA m2 : 41|1@1+ (1,0) [0|1] "" Vector__XXX
 SG_ DIF_a160_busVoltageAnomaly m2 : 43|1@1+ (1,0) [0|1] "" Vector__XXX
 SG_ DIF_a161_epas3pMIA m2 : 44|1@1+ (1,0) [0|1] "" Vector__XXX
 SG_ DIF_a162_endOfLifetimeBurnIn m2 : 45|1@1+ (1,0) [0|1] "" Vector__XXX
 SG_ DIF_d163_recoverableOvercurrent m2 : 46|1@1+ (1,0) [0|1] "" Vector__XXX
 SG_ DIF_d164_firmwareConfigMismatch m2 : 47|1@1+ (1,0) [0|1] "" Vector__XXX
 SG_ DIF_d165_statorOverTemperature m2 : 48|1@1+ (1,0) [0|1] "" Vector__XXX
 SG_ DIF_d166_rotorOverTemperature m2 : 49|1@1+ (1,0) [0|1] "" Vector__XXX
 SG_ DIF_d167_tempSensorIssue m2 : 50|1@1+ (1,0) [0|1] "" Vector__XXX
 SG_ DIF_d168_clutchPerformance m2 : 51|1@1+ (1,0) [0|1] "" Vector__XXX
 SG_ DIF_d169_clutchPosition m2 : 52|1@1+ (1,0) [0|1] "" Vector__XXX
 SG_ DIF_d170_clutchFailure m2 : 53|1@1+ (1,0) [0|1] "" Vector__XXX
 SG_ DIF_a172_statorOilTempOT m2 : 55|1@1+ (1,0) [0|1] "" Vector__XXX
 SG_ DIF_a173_ascFdbkDiagnostic m2 : 56|1@1+ (1,0) [0|1] "" Vector__XXX
 SG_ DIF_a174_unitMayNotRestart m2 : 57|1@1+ (1,0) [0|1] "" Vector__XXX
 SG_ DIF_a176_safetyICFault m2 : 59|1@1+ (1,0) [0|1] "" Vector__XXX
 SG_ DIF_a177_fluxReferenceCorrected m2 : 60|1@1+ (1,0) [0|1] "" Vector__XXX
 SG_ DIF_a202_excessHeatUnavailable m3 : 25|1@1+ (1,0) [0|1] "" Vector__XXX
 SG_ DIF_a225_tmpEstPlausibility m3 : 48|1@1+ (1,0) [0|1] "" Vector__XXX
 SG_ DIF_a229_busVsensorOverCAN m3 : 52|1@1+ (1,0) [0|1] "" Vector__XXX
 SG_ DIF_a233_diMsgMissed m3 : 56|1@1+ (1,0) [0|1] "" Vector__XXX
 SG_ DIF_a234_pcsMIA m3 : 57|1@1+ (1,0) [0|1] "" Vector__XXX
 SG_ DIF_a236_tasMIA m3 : 59|1@1+ (1,0) [0|1] "" Vector__XXX
 SG_ DIF_a240_clearFusesRoutine m3 : 63|1@1+ (1,0) [0|1] "" Vector__XXX
 SG_ DIF_a241_systemThermallyLimited m4 : 4|1@1+ (1,0) [0|1] "" Vector__XXX
 SG_ DIF_a242_spinDownLearning m4 : 5|1@1+ (1,0) [0|1] "" Vector__XXX
 SG_ DIF_a243_ecuLogAvailable m4 : 6|1@1+ (1,0) [0|1] "" Vector__XXX
 SG_ DIF_a244_mechSafeStateApplied m4 : 7|1@1+ (1,0) [0|1] "" Vector__XXX
 SG_ DIF_a245_mechSafeStatePreWarn m4 : 8|1@1+ (1,0) [0|1] "" Vector__XXX
 SG_ DIF_a246_recoveryAtSpeedError m4 : 9|1@1+ (1,0) [0|1] "" Vector__XXX
 SG_ DIF_a247_rotorOffsetError m4 : 10|1@1+ (1,0) [0|1] "" Vector__XXX
 SG_ DIF_a249_highStatorTempFromResis m4 : 12|1@1+ (1,0) [0|1] "" Vector__XXX
 SG_ DIF_a250_preregulatorRail m4 : 13|1@1+ (1,0) [0|1] "" Vector__XXX
 SG_ DIF_a251_oilPumpService m4 : 14|1@1+ (1,0) [0|1] "" Vector__XXX
 SG_ DIF_a252_currentCoreFallback m4 : 15|1@1+ (1,0) [0|1] "" Vector__XXX
 SG_ DIF_a253_lvBoostedRail m4 : 16|1@1+ (1,0) [0|1] "" Vector__XXX
 SG_ DIF_a254_activeDischargeRail m4 : 17|1@1+ (1,0) [0|1] "" Vector__XXX
 SG_ DIF_a255_currentGainFallback m4 : 18|1@1+ (1,0) [0|1] "" Vector__XXX

BO_ 1879 DIF_debug: 8 DIF
 SG_ DIF_debugSelector M : 0|8@1+ (1,0) [0|255] "" Vector__XXX
 SG_ DIF_motorIA m32 : 8|16@1+ (0.1,0) [0|6553.5] "A" Vector__XXX
 SG_ DIF_motorIB m32 : 24|16@1+ (0.1,0) [0|6553.5] "A" Vector__XXX
 SG_ DIF_motorIC m32 : 40|16@1+ (0.1,0) [0|6553.5] "A" Vector__XXX
 SG_ DIF_statorIDref m33 : 8|16@1- (0.1,0) [-3276.8|3276.7] "A" Vector__XXX
 SG_ DIF_statorIDfdb m33 : 24|16@1- (0.1,0) [-3276.8|3276.7] "A" Vector__XXX
 SG_ DIF_torquePerAmp m33 : 40|16@1+ (0.0001,0) [0|6.5535] "Nm/A" Vector__XXX
 SG_ DIF_rsScale m34 : 8|8@1+ (0.01,0) [0|2.55] "scale" Vector__XXX
 SG_ DIF_statorIQref m34 : 16|16@1- (0.1,0) [-3276.8|3276.7] "A" Vector__XXX
 SG_ DIF_statorIQfdb m34 : 32|16@1- (0.1,0) [-3276.8|3276.7] "A" Vector__XXX
 SG_ DIF_motorV m34 : 48|16@1+ (2.0e-05,0) [0|1.3107] "mindex" Vector__XXX
 SG_ DIF_tqScaleDifferential m35 : 8|8@1+ (0.4,0) [0|102] "%" Vector__XXX
 SG_ DIF_statorFluxRef m35 : 16|16@1+ (0.0001,0) [0|6.5535] "Wb" Vector__XXX
 SG_ DIF_statorFluxFdb m35 : 32|16@1+ (0.0001,0) [0|6.5535] "Wb" Vector__XXX
 SG_ DIF_lmScale m36 : 8|8@1+ (0.004,0) [0|1.02] "scale" Vector__XXX
 SG_ DIF_statorVQ m36 : 16|16@1- (4.0e-05,0) [-1.31072|1.31068] "mindex" Vector__XXX
 SG_ DIF_statorVD m36 : 32|16@1- (4.0e-05,0) [-1.31072|1.31068] "mindex" Vector__XXX
 SG_ DIF_peakFlux m36 : 48|16@1+ (0.0001,0) [0|6.5535] "Wb" Vector__XXX
 SG_ DIF_gainScale m37 : 8|8@1+ (0.01,0) [0|2.55] "scale" Vector__XXX
 SG_ DIF_usmState m38 : 12|3@1+ (1,0) [0|7] "" Vector__XXX
 SG_ DIF_peakIQref m38 : 16|16@1+ (0.1,0) [0|6553.5] "A" Vector__XXX
 SG_ DIF_motorIAavg m38 : 32|16@1- (0.1,0) [-3276.8|3276.7] "A" Vector__XXX
 SG_ DIF_motorIBavg m38 : 48|16@1- (0.1,0) [-3276.8|3276.7] "A" Vector__XXX
 SG_ DIF_tqSatThermal m39 : 8|8@1+ (0.4,0) [0|102] "%" Vector__XXX
 SG_ DIF_tqSatMotorVoltage m39 : 32|8@1+ (0.4,0) [0|102] "%" Vector__XXX
 SG_ DIF_tqSatMotorCurrent m39 : 40|8@1+ (0.4,0) [0|102] "%" Vector__XXX
 SG_ DIF_tcMaxRequest m40 : 16|8@1+ (5,0) [0|1275] "Nm" Vector__XXX
 SG_ DIF_tcMinRequest m40 : 24|8@1+ (5,0) [0|1275] "Nm" Vector__XXX
 SG_ DIF_tqScaleMaxMotorSpeed m40 : 48|8@1+ (0.4,0) [0|102] "%" Vector__XXX
 SG_ DIF_wasteCurrentLimit m41 : 32|16@1+ (0.1,0) [0|6553.5] "A" Vector__XXX
 SG_ DIF_llsScale m42 : 24|8@1+ (0.004,0) [0|1.02] "scale" Vector__XXX
 SG_ DIF_llrScale m42 : 32|8@1+ (0.015,0) [0|3.825] "scale" Vector__XXX
 SG_ DIF_oilPumpMotorSpeed m46 : 8|8@1+ (40,0) [0|10200] "RPM" Vector__XXX
 SG_ DIF_rotorFlux m47 : 16|16@1+ (0.0001,0) [0|6.5535] "Wb" Vector__XXX
 SG_ DIF_dcCableHeat m47 : 32|16@1+ (0.001,0) [0|65.535] "kA2s" Vector__XXX
 SG_ DIF_magnetTempEst m47 : 48|8@1+ (1,-40) [-40|215] "DegC" Vector__XXX
 SG_ DIF_resolverReady m48 : 40|1@1+ (1,0) [0|1] "" Vector__XXX
 SG_ DIF_resolverNoCarrier m48 : 41|1@1+ (1,0) [0|1] "" Vector__XXX
 SG_ DIF_resolverNoPhaseLock m48 : 42|1@1+ (1,0) [0|1] "" Vector__XXX
 SG_ DIF_resolverClaMIA m48 : 43|1@1+ (1,0) [0|1] "" Vector__XXX
 SG_ DIF_soptMaxCurrentMagSqrd m49 : 40|16@1+ (100,0) [0|6553500] "A2" Vector__XXX
 SG_ DIF_statorVDFiltered m63 : 16|16@1- (4.0e-05,0) [-1.31072|1.31068] "mindex" Vector__XXX
 SG_ DIF_statorVQFiltered m63 : 32|16@1- (4.0e-05,0) [-1.31072|1.31068] "mindex" Vector__XXX
 SG_ DIF_pwmState m63 : 48|2@1+ (1,0) [0|3] "" Vector__XXX
 SG_ DIF_dcCapTemp m64 : 8|8@1+ (1,-40) [-40|215] "DegC" Vector__XXX
 SG_ DIF_busbarTemp m64 : 16|8@1+ (1,-40) [-40|215] "DegC" Vector__XXX
 SG_ DIF_pcsTemp m64 : 24|8@1+ (1,-40) [-40|215] "DegC" Vector__XXX
 SG_ DIF_statorTemp1 m64 : 32|8@1+ (1,-40) [-40|215] "DegC" Vector__XXX
 SG_ DIF_statorTemp2 m64 : 40|8@1+ (1,-40) [-40|215] "DegC" Vector__XXX
 SG_ DIF_cpu10HzMin m66 : 8|8@1+ (0.4,0) [0|102] "%" Vector__XXX
 SG_ DIF_cpu10HzAvg m66 : 16|8@1+ (0.4,0) [0|102] "%" Vector__XXX
 SG_ DIF_cpu100HzMin m66 : 24|8@1+ (0.4,0) [0|102] "%" Vector__XXX
 SG_ DIF_cpu100HzAvg m66 : 32|8@1+ (0.4,0) [0|102] "%" Vector__XXX
 SG_ DIF_cpu10msMin m66 : 40|8@1+ (0.4,0) [0|102] "%" Vector__XXX
 SG_ DIF_cpu1kHzMin m67 : 8|8@1+ (0.4,0) [0|102] "%" Vector__XXX
 SG_ DIF_cpu1kHzAvg m67 : 16|8@1+ (0.4,0) [0|102] "%" Vector__XXX
 SG_ DIF_cpu20kHzMin m67 : 24|8@1+ (0.4,0) [0|102] "%" Vector__XXX
 SG_ DIF_cpu20kHzAvg m67 : 32|8@1+ (0.4,0) [0|102] "%" Vector__XXX
 SG_ DIF_hwFaultCount m69 : 8|4@1+ (1,0) [0|15] "" Vector__XXX
 SG_ DIF_driveUnitOdometer m69 : 32|32@1+ (10,0) [0|42949672950] "rev" Vector__XXX
 SG_ DIF_phaseOutBusbarTemp m70 : 8|8@1+ (1,-40) [-39|215] "DegC" Vector__XXX
 SG_ DIF_phaseOutBusbarWeldTemp m70 : 16|8@1+ (1,-40) [-39|215] "DegC" Vector__XXX
 SG_ DIF_phaseOutLugTemp m70 : 24|8@1+ (1,-40) [-39|215] "DegC" Vector__XXX
 SG_ DIF_dcLinkCapTemp m70 : 32|8@1+ (1,-40) [-39|215] "DegC" Vector__XXX
 SG_ DIF_hvDcCableTemp m70 : 40|8@1+ (1,-40) [-39|215] "DegC" Vector__XXX
 SG_ DIF_negDcBusbarTemp m70 : 48|8@1+ (1,-40) [-39|215] "DegC" Vector__XXX
 SG_ DIF_posDcBusbarTemp m70 : 56|8@1+ (1,-40) [-39|215] "DegC" Vector__XXX
 SG_ DIF_statorEndWindingTemp m72 : 8|8@1+ (1,-40) [-39|215] "DegC" Vector__XXX
 SG_ DIF_rotorMaxMagnetTemp m72 : 16|8@1+ (1,-40) [-39|215] "DegC" Vector__XXX
 SG_ DIF_lightSenseV m72 : 24|6@1+ (0.1,0) [0|3.3] "V" Vector__XXX
 SG_ DIF_pyroSenseV m72 : 30|8@1+ (0.02,0) [0|3.3] "V" Vector__XXX
 SG_ DIF_statorSlotWindingTemp m72 : 46|8@1+ (1,-40) [-39|215] "DegC" Vector__XXX
 SG_ DIF_intervalMaxHvBusV m72 : 54|10@1+ (1,0) [0|1023] "V" Vector__XXX
 SG_ DIF_cpu1HzMin m128 : 8|8@1+ (0.4,0) [0|102] "%" Vector__XXX
 SG_ DIF_cpu1HzAvg m128 : 16|8@1+ (0.4,0) [0|102] "%" Vector__XXX
 SG_ DIF_cpuIDWord0 m131 : 16|16@1+ (1,0) [0|65535] "" Vector__XXX
 SG_ DIF_cpuIDWord1 m132 : 16|16@1+ (1,0) [0|65535] "" Vector__XXX
 SG_ DIF_cpuIDWord2 m132 : 32|16@1+ (1,0) [0|65535] "" Vector__XXX
 SG_ DIF_cpuIDWord3 m132 : 48|16@1+ (1,0) [0|65535] "" Vector__XXX

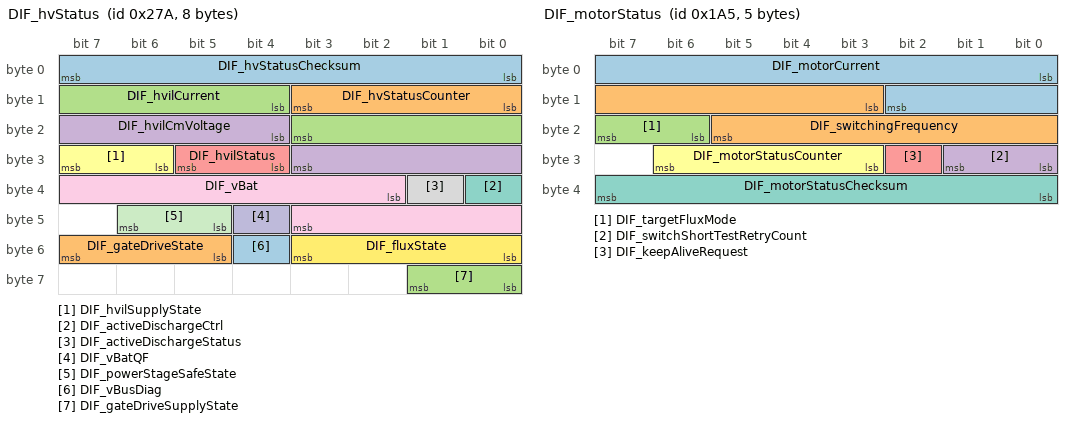
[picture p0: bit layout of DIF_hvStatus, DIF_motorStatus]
BO_ 634 DIF_hvStatus: 8 DIF
 SG_ DIF_hvStatusChecksum : 0|8@1+ (1,0) [0|255] "" Vector__XXX
 SG_ DIF_hvStatusCounter : 8|4@1+ (1,0) [0|15] "" Vector__XXX
 SG_ DIF_hvilCurrent : 12|8@1+ (0.1,0) [0|25.5] "mA" Vector__XXX
 SG_ DIF_hvilCmVoltage : 20|8@1+ (0.08,0) [0|20.4] "V" Vector__XXX
 SG_ DIF_hvilStatus : 28|2@1+ (1,0) [0|2] "" Vector__XXX
 SG_ DIF_hvilSupplyState : 30|2@1+ (1,0) [0|3] "" Vector__XXX
 SG_ DIF_activeDischargeCtrl : 32|1@1+ (1,0) [0|1] "" Vector__XXX
 SG_ DIF_activeDischargeStatus : 33|1@1+ (1,0) [0|1] "" Vector__XXX
 SG_ DIF_vBat : 34|10@1+ (1,0) [0|1023] "V" Vector__XXX
 SG_ DIF_vBatQF : 44|1@1+ (1,0) [0|1] "" Vector__XXX
 SG_ DIF_powerStageSafeState : 45|2@1+ (1,0) [0|3] "" Vector__XXX
 SG_ DIF_fluxState : 48|4@1+ (1,0) [0|15] "" Vector__XXX
 SG_ DIF_vBusDiag : 52|1@1+ (1,0) [0|1] "" Vector__XXX
 SG_ DIF_gateDriveState : 53|3@1+ (1,0) [0|7] "" Vector__XXX
 SG_ DIF_gateDriveSupplyState : 56|2@1+ (1,0) [0|3] "" Vector__XXX

BO_ 1622 DIF_info: 8 DIF
 SG_ DIF_infoIndex M : 0|8@1+ (1,0) [0|255] "" Vector__XXX
 SG_ DIF_buildType m10 : 8|3@1+ (1,0) [0|7] "" Vector__XXX
 SG_ DIF_buildConfigurationId m10 : 16|16@1+ (1,0) [0|65535] "" Vector__XXX
 SG_ DIF_hardwareId m10 : 32|8@1+ (1,0) [0|252] "" Vector__XXX
 SG_ DIF_componentId m10 : 48|16@1+ (1,0) [0|65535] "" Vector__XXX
 SG_ DIF_pcbaId m11 : 16|8@1+ (1,0) [0|255] "" Vector__XXX
 SG_ DIF_assemblyId m11 : 24|8@1+ (1,0) [0|255] "" Vector__XXX
 SG_ DIF_usageId m11 : 32|16@1+ (1,0) [0|65535] "" Vector__XXX
 SG_ DIF_subUsageId m11 : 48|16@1+ (1,0) [0|65535] "" Vector__XXX
 SG_ DIF_motorType m12 : 8|6@1+ (1,0) [1|63] "" Vector__XXX
 SG_ DIF_siliconType m12 : 16|1@1+ (1,0) [0|1] "" Vector__XXX
 SG_ DIF_mechSafeStateType m12 : 24|2@1+ (1,0) [1|3] "" Vector__XXX
 SG_ DIF_applicationCrc m13 : 32|32@1+ (1,0) [0|4294967295] "" Vector__XXX
 SG_ DIF_oilPumpBuildType m16 : 8|3@1+ (1,0) [0|7] "" Vector__XXX
 SG_ DIF_oilPumpAppCrc m16 : 16|32@1+ (1,0) [0|4294967295] "" Vector__XXX
 SG_ DIF_FPGA_version m16 : 48|8@1+ (1,0) [0|254] "" Vector__XXX
 SG_ DIF_appGitHash m17 : 8|56@1+ (1,0) [0|7.20575940379e+16] "" Vector__XXX
 SG_ DIF_bootGitHash m18 : 8|56@1+ (1,0) [0|7.20575940379e+16] "" Vector__XXX
 SG_ DIF_platformTyp m19 : 8|8@1+ (1,0) [0|255] "" Vector__XXX
 SG_ DIF_infoBootLdUdsProtocolVersion m20 : 8|8@1+ (1,0) [0|255] "" Vector__XXX
 SG_ DIF_bootloaderCrc m20 : 32|32@1+ (1,0) [0|4294967295] "" Vector__XXX
 SG_ DIF_subcomponentGitHash m31 : 8|56@1+ (1,0) [0|7.20575940379e+16] "" Vector__XXX
 SG_ DIF_oilPumpPcbaId m33 : 8|8@1+ (1,0) [0|255] "" Vector__XXX
 SG_ DIF_oilPumpAssemblyId m33 : 16|8@1+ (1,0) [0|255] "" Vector__XXX
 SG_ DIF_oilPumpUsageId m33 : 24|16@1+ (1,0) [0|65535] "" Vector__XXX
 SG_ DIF_refRotorFlux m35 : 8|16@1+ (0.0001,0) [0|6.5535] "Wb" Vector__XXX
 SG_ DIF_refRotorOffset m35 : 24|12@1- (0.1,0) [-180|180] "deg" Vector__XXX
 SG_ DIF_speedWearTotal m36 : 8|8@1+ (0.4,0) [0|100] "%" Vector__XXX
 SG_ DIF_torqueWearTotal m36 : 24|8@1+ (0.02,0) [0|5.08] "1" Vector__XXX

BO_ 421 DIF_motorStatus: 5 DIF
 SG_ DIF_motorCurrent : 0|11@1+ (1,0) [0|2047] "A" Vector__XXX
 SG_ DIF_switchingFrequency : 11|11@1+ (0.01,0) [0|20] "kHz" Vector__XXX
 SG_ DIF_targetFluxMode : 22|2@1+ (1,0) [0|3] "" Vector__XXX
 SG_ DIF_switchShortTestRetryCount : 24|2@1+ (1,0) [0|3] "" Vector__XXX
 SG_ DIF_keepAliveRequest : 26|1@1+ (1,0) [0|1] "" Vector__XXX
 SG_ DIF_motorStatusCounter : 27|4@1+ (1,0) [0|15] "" Vector__XXX
 SG_ DIF_motorStatusChecksum : 32|8@1+ (1,0) [0|255] "" Vector__XXX

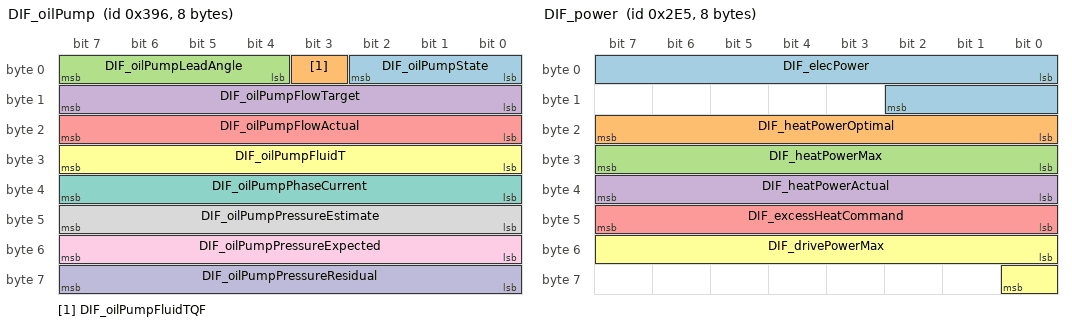
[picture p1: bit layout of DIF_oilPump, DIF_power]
BO_ 918 DIF_oilPump: 8 DIF
 SG_ DIF_oilPumpState : 0|3@1+ (1,0) [0|6] "" Vector__XXX
 SG_ DIF_oilPumpFluidTQF : 3|1@1+ (1,0) [0|1] "" Vector__XXX
 SG_ DIF_oilPumpLeadAngle : 4|4@1+ (1.875,0) [0|28.125] "degrees" Vector__XXX
 SG_ DIF_oilPumpFlowTarget : 8|8@1+ (0.1,0) [0|25.4] "LPM" Vector__XXX
 SG_ DIF_oilPumpFlowActual : 16|8@1+ (0.1,0) [0|25.4] "LPM" Vector__XXX
 SG_ DIF_oilPumpFluidT : 24|8@1+ (1,-40) [-40|214] "DegC" Vector__XXX
 SG_ DIF_oilPumpPhaseCurrent : 32|8@1+ (0.1,0) [0|25.4] "A" Vector__XXX
 SG_ DIF_oilPumpPressureEstimate : 40|8@1+ (2,0) [0|500] "kPa" Vector__XXX
 SG_ DIF_oilPumpPressureExpected : 48|8@1+ (2,0) [0|500] "kPa" Vector__XXX
 SG_ DIF_oilPumpPressureResidual : 56|8@1+ (4,-500) [-500|500] "kPa" Vector__XXX

BO_ 741 DIF_power: 8 DIF
 SG_ DIF_elecPower : 0|11@1- (0.5,0) [-500|500] "kW" Vector__XXX
 SG_ DIF_heatPowerOptimal : 16|8@1+ (0.08,0) [0|20] "kW" Vector__XXX
 SG_ DIF_heatPowerMax : 24|8@1+ (0.08,0) [0|20] "kW" Vector__XXX
 SG_ DIF_heatPowerActual : 32|8@1+ (0.08,0) [0|20] "kW" Vector__XXX
 SG_ DIF_excessHeatCommand : 40|8@1+ (0.08,0) [0|20] "kW" Vector__XXX
 SG_ DIF_drivePowerMax : 48|9@1+ (1,0) [0|400] "kW" Vector__XXX

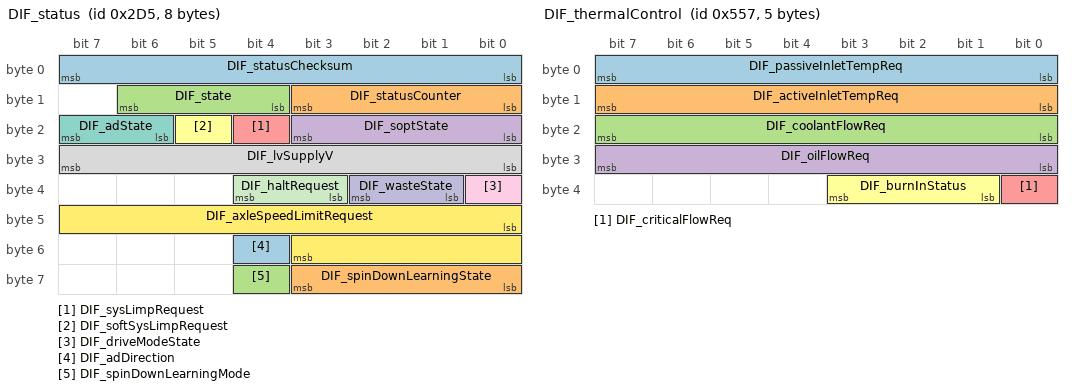
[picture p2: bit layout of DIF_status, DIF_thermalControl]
BO_ 725 DIF_status: 8 DIF
 SG_ DIF_statusChecksum : 0|8@1+ (1,0) [0|255] "" Vector__XXX
 SG_ DIF_statusCounter : 8|4@1+ (1,0) [0|15] "" Vector__XXX
 SG_ DIF_state : 12|3@1+ (1,0) [0|7] "" Vector__XXX
 SG_ DIF_soptState : 16|4@1+ (1,0) [0|15] "" Vector__XXX
 SG_ DIF_sysLimpRequest : 20|1@1+ (1,0) [0|1] "" Vector__XXX
 SG_ DIF_softSysLimpRequest : 21|1@1+ (1,0) [0|1] "" Vector__XXX
 SG_ DIF_adState : 22|2@1+ (1,0) [0|3] "" Vector__XXX
 SG_ DIF_lvSupplyV : 24|8@1+ (0.1,0) [0|25.5] "V" Vector__XXX
 SG_ DIF_driveModeState : 32|1@1+ (1,0) [0|1] "" Vector__XXX
 SG_ DIF_wasteState : 33|2@1+ (1,0) [0|3] "" Vector__XXX
 SG_ DIF_haltRequest : 35|2@1+ (1,0) [0|3] "" Vector__XXX
 SG_ DIF_axleSpeedLimitRequest : 40|12@1+ (1,40) [40|2750] "RPM" Vector__XXX
 SG_ DIF_adDirection : 52|1@1+ (1,0) [0|1] "" Vector__XXX
 SG_ DIF_spinDownLearningState : 56|4@1+ (1,0) [0|15] "" Vector__XXX
 SG_ DIF_spinDownLearningMode : 60|1@1+ (1,0) [0|1] "" Vector__XXX

BO_ 886 DIF_temperature: 8 DIF
 SG_ DIF_tempIndex M : 0|3@1+ (1,0) [0|7] "" Vector__XXX
 SG_ DIF_inverterTQF m0 : 3|2@1+ (1,0) [0|3] "" Vector__XXX
 SG_ DIF_pcbT m0 : 8|8@1+ (1,-40) [-39|215] "DegC" Vector__XXX
 SG_ DIF_inverterT m0 : 16|8@1+ (1,-40) [-40|215] "DegC" Vector__XXX
 SG_ DIF_statorT m0 : 24|8@1+ (1,-40) [-39|215] "DegC" Vector__XXX
 SG_ DIF_dcCapT m0 : 32|8@1+ (1,-40) [-39|215] "DegC" Vector__XXX
 SG_ DIF_heatsinkT m0 : 40|8@1+ (1,-40) [-39|215] "DegC" Vector__XXX
 SG_ DIF_inverterTpct m0 : 48|8@1+ (0.4,0) [0|100] "%" Vector__XXX
 SG_ DIF_statorTpct m0 : 56|8@1+ (0.4,0) [0|100] "%" Vector__XXX
 SG_ DIF_fluidInTemp m2 : 8|8@1+ (1,-40) [-39|215] "DegC" Vector__XXX
 SG_ DIF_normalFetBurnIn m2 : 16|16@1+ (0.00763,0) [0|500] "Hours" Vector__XXX
 SG_ DIF_additionalFetBurnIn m2 : 32|16@1+ (0.00763,0) [0|500] "Hours" Vector__XXX
 SG_ DIF_currentWeibullMiles m3 : 3|16@1+ (8,0) [0|500000] "miles" Vector__XXX
 SG_ DIF_endOfServiceWeibullMiles m3 : 19|16@1+ (8,0) [0|500000] "miles" Vector__XXX
 SG_ DIF_burnInDamageRatio m3 : 35|9@1+ (0.01,0) [0|5] "1" Vector__XXX
 SG_ DIF_inverterSensorEst m3 : 44|8@1+ (1,-40) [-40|120] "C" Vector__XXX
 SG_ DIF_inverterHS1Est m3 : 52|8@1+ (1,-40) [-40|120] "C" Vector__XXX
 SG_ DIF_initialBurnInVehicleOdometer m4 : 8|32@1+ (0.001,0) [0|4294967.294] "km" Vector__XXX
 SG_ DIF_inverterHS2Est m4 : 40|8@1+ (1,-40) [-40|120] "C" Vector__XXX
 SG_ DIF_inverterInletEst m4 : 48|8@1+ (1,-40) [-40|120] "C" Vector__XXX
 SG_ DIF_statorHousingTemp m4 : 56|8@1+ (1,-40) [-39|215] "DegC" Vector__XXX

BO_ 1367 DIF_thermalControl: 5 DIF
 SG_ DIF_passiveInletTempReq : 0|8@1+ (1,-40) [-40|215] "DegC" Vector__XXX
 SG_ DIF_activeInletTempReq : 8|8@1+ (1,-40) [-40|215] "DegC" Vector__XXX
 SG_ DIF_coolantFlowReq : 16|8@1+ (0.2,0) [0|50] "LPM" Vector__XXX
 SG_ DIF_oilFlowReq : 24|8@1+ (0.1,0) [0|25.4] "LPM" Vector__XXX
 SG_ DIF_criticalFlowReq : 32|1@1+ (1,0) [0|1] "" Vector__XXX
 SG_ DIF_burnInStatus : 33|3@1+ (1,0) [0|7] "" Vector__XXX

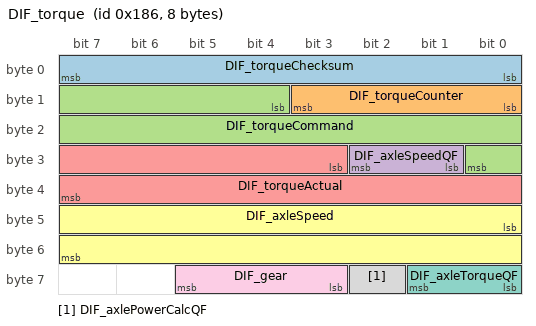
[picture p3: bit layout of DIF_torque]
BO_ 390 DIF_torque: 8 DIF
 SG_ DIF_torqueChecksum : 0|8@1+ (1,0) [0|255] "" Vector__XXX
 SG_ DIF_torqueCounter : 8|4@1+ (1,0) [0|15] "" Vector__XXX
 SG_ DIF_torqueCommand : 12|13@1- (2,0) [-7500|7500] "Nm" Vector__XXX
 SG_ DIF_axleSpeedQF : 25|2@1+ (1,0) [0|3] "" Vector__XXX
 SG_ DIF_torqueActual : 27|13@1- (2,0) [-7500|7500] "Nm" Vector__XXX
 SG_ DIF_axleSpeed : 40|16@1- (0.1,0) [-2750|2750] "RPM" Vector__XXX
 SG_ DIF_axleTorqueQF : 56|2@1+ (1,0) [0|3] "" Vector__XXX
 SG_ DIF_axlePowerCalcQF : 58|1@1+ (1,0) [0|1] "" Vector__XXX
 SG_ DIF_gear : 59|3@1+ (1,0) [0|6] "" Vector__XXX

BO_ 1557 DIF_udsResponse: 8 DIF
 SG_ DIF_udsResponseData : 7|64@0+ (1,0) [0|1.84467440737e+19] "" Vector__XXX

BO_TX_BU_ 1318 : DIF;
BO_TX_BU_ 854 : DIF;
BO_TX_BU_ 1879 : DIF;
BO_TX_BU_ 634 : DIF;
BO_TX_BU_ 1622 : DIF;
BO_TX_BU_ 421 : DIF;
BO_TX_BU_ 918 : DIF;
BO_TX_BU_ 741 : DIF;
BO_TX_BU_ 725 : DIF;
BO_TX_BU_ 886 : DIF;
BO_TX_BU_ 1367 : DIF;
BO_TX_BU_ 390 : DIF;
BO_TX_BU_ 1557 : DIF;
CM_ BO_ 1318 "Front drive inverter message: alert log";
CM_ SG_ 1318 DIF_alertID "Front drive inverter: alert ID";
CM_ SG_ 1318 DIF_alertState "Front drive inverter: alert state";
CM_ SG_ 1318 DIF_a001_thermalWarning_H "Front drive inverter: a001 thermal warning h";
CM_ SG_ 1318 DIF_a001_thermalShutdown_H "Front drive inverter: a001 thermal shutdown h";
CM_ SG_ 1318 DIF_a001_undervoltVL_H "Front drive inverter: a001 undervolt VL h";
CM_ SG_ 1318 DIF_a001_undervoltVH_H "Front drive inverter: a001 undervolt VH h";
CM_ SG_ 1318 DIF_a001_sense_H "Front drive inverter: a001 sense h";
CM_ SG_ 1318 DIF_a001_desat_H "Front drive inverter: a001 desat h";
CM_ SG_ 1318 DIF_a001_overvoltVL_H "Front drive inverter: a001 overvolt VL h";
CM_ SG_ 1318 DIF_a001_overvoltVH_H "Front drive inverter: a001 overvolt VH h";
CM_ SG_ 1318 DIF_a001_undervoltVCC_H "Front drive inverter: a001 undervolt VCC h";
CM_ SG_ 1318 DIF_a001_asynchStop_H "Front drive inverter: a001 asynch stop h";
CM_ SG_ 1318 DIF_a001_remoteRegError_H "Front drive inverter: a001 remote reg error h";
CM_ SG_ 1318 DIF_a001_undervoltVDD_H "Front drive inverter: a001 undervolt VDD h";
CM_ SG_ 1318 DIF_a001_overvoltVDD_H "Front drive inverter: a001 overvolt VDD h";
CM_ SG_ 1318 DIF_a001_localRegError_H "Front drive inverter: a001 local reg error h";
CM_ SG_ 1318 DIF_a001_spiError_H "Front drive inverter: a001 spi error h";
CM_ SG_ 1318 DIF_a001_deadtimeError_H "Front drive inverter: a001 deadtime error h";
CM_ SG_ 1318 DIF_a001_thermalWarning_L "Front drive inverter: a001 thermal warning l";
CM_ SG_ 1318 DIF_a001_thermalShutdown_L "Front drive inverter: a001 thermal shutdown l";
CM_ SG_ 1318 DIF_a001_undervoltVL_L "Front drive inverter: a001 undervolt VL l";
CM_ SG_ 1318 DIF_a001_undervoltVH_L "Front drive inverter: a001 undervolt VH l";
CM_ SG_ 1318 DIF_a001_sense_L "Front drive inverter: a001 sense l";
CM_ SG_ 1318 DIF_a001_desat_L "Front drive inverter: a001 desat l";
CM_ SG_ 1318 DIF_a001_overvoltVL_L "Front drive inverter: a001 overvolt VL l";
CM_ SG_ 1318 DIF_a001_overvoltVH_L "Front drive inverter: a001 overvolt VH l";
CM_ SG_ 1318 DIF_a001_undervoltVCC_L "Front drive inverter: a001 undervolt VCC l";
CM_ SG_ 1318 DIF_a001_asynchStop_L "Front drive inverter: a001 asynch stop l";
CM_ SG_ 1318 DIF_a001_remoteRegError_L "Front drive inverter: a001 remote reg error l";
CM_ SG_ 1318 DIF_a001_undervoltVDD_L "Front drive inverter: a001 undervolt VDD l";
CM_ SG_ 1318 DIF_a001_overvoltVDD_L "Front drive inverter: a001 overvolt VDD l";
CM_ SG_ 1318 DIF_a001_localRegError_L "Front drive inverter: a001 local reg error l";
CM_ SG_ 1318 DIF_a001_spiError_L "Front drive inverter: a001 spi error l";
CM_ SG_ 1318 DIF_a001_deadtimeError_L "Front drive inverter: a001 deadtime error l";
CM_ SG_ 1318 DIF_a001_gateDriveErrCounter "Front drive inverter: a001 gate drive err counter";
CM_ SG_ 1318 DIF_a001_remoteCommError_H "Front drive inverter: a001 remote comm error h";
CM_ SG_ 1318 DIF_a001_localCommError_H "Front drive inverter: a001 local comm error h";
CM_ SG_ 1318 DIF_a001_remoteReset_H "Front drive inverter: a001 remote reset h";
CM_ SG_ 1318 DIF_a001_localReset_H "Front drive inverter: a001 local reset h";
CM_ SG_ 1318 DIF_a001_remoteCommError_L "Front drive inverter: a001 remote comm error l";
CM_ SG_ 1318 DIF_a001_localCommError_L "Front drive inverter: a001 local comm error l";
CM_ SG_ 1318 DIF_a001_remoteReset_L "Front drive inverter: a001 remote reset l";
CM_ SG_ 1318 DIF_a001_localReset_L "Front drive inverter: a001 local reset l";
CM_ SG_ 1318 DIF_a001_faultLine1Gpio_H "Front drive inverter: a001 fault line1 gpio h";
CM_ SG_ 1318 DIF_a001_faultLine1Gpio_L "Front drive inverter: a001 fault line1 gpio l";
CM_ SG_ 1318 DIF_a002_thermalWarning_H "Front drive inverter: a002 thermal warning h";
CM_ SG_ 1318 DIF_a002_thermalShutdown_H "Front drive inverter: a002 thermal shutdown h";
CM_ SG_ 1318 DIF_a002_undervoltVL_H "Front drive inverter: a002 undervolt VL h";
CM_ SG_ 1318 DIF_a002_undervoltVH_H "Front drive inverter: a002 undervolt VH h";
CM_ SG_ 1318 DIF_a002_sense_H "Front drive inverter: a002 sense h";
CM_ SG_ 1318 DIF_a002_desat_H "Front drive inverter: a002 desat h";
CM_ SG_ 1318 DIF_a002_overvoltVL_H "Front drive inverter: a002 overvolt VL h";
CM_ SG_ 1318 DIF_a002_overvoltVH_H "Front drive inverter: a002 overvolt VH h";
CM_ SG_ 1318 DIF_a002_undervoltVCC_H "Front drive inverter: a002 undervolt VCC h";
CM_ SG_ 1318 DIF_a002_asynchStop_H "Front drive inverter: a002 asynch stop h";
CM_ SG_ 1318 DIF_a002_remoteRegError_H "Front drive inverter: a002 remote reg error h";
CM_ SG_ 1318 DIF_a002_undervoltVDD_H "Front drive inverter: a002 undervolt VDD h";
CM_ SG_ 1318 DIF_a002_overvoltVDD_H "Front drive inverter: a002 overvolt VDD h";
CM_ SG_ 1318 DIF_a002_localRegError_H "Front drive inverter: a002 local reg error h";
CM_ SG_ 1318 DIF_a002_spiError_H "Front drive inverter: a002 spi error h";
CM_ SG_ 1318 DIF_a002_deadtimeError_H "Front drive inverter: a002 deadtime error h";
CM_ SG_ 1318 DIF_a002_thermalWarning_L "Front drive inverter: a002 thermal warning l";
CM_ SG_ 1318 DIF_a002_thermalShutdown_L "Front drive inverter: a002 thermal shutdown l";
CM_ SG_ 1318 DIF_a002_undervoltVL_L "Front drive inverter: a002 undervolt VL l";
CM_ SG_ 1318 DIF_a002_undervoltVH_L "Front drive inverter: a002 undervolt VH l";
CM_ SG_ 1318 DIF_a002_sense_L "Front drive inverter: a002 sense l";
CM_ SG_ 1318 DIF_a002_desat_L "Front drive inverter: a002 desat l";
CM_ SG_ 1318 DIF_a002_overvoltVL_L "Front drive inverter: a002 overvolt VL l";
CM_ SG_ 1318 DIF_a002_overvoltVH_L "Front drive inverter: a002 overvolt VH l";
CM_ SG_ 1318 DIF_a002_undervoltVCC_L "Front drive inverter: a002 undervolt VCC l";
CM_ SG_ 1318 DIF_a002_asynchStop_L "Front drive inverter: a002 asynch stop l";
CM_ SG_ 1318 DIF_a002_remoteRegError_L "Front drive inverter: a002 remote reg error l";
CM_ SG_ 1318 DIF_a002_undervoltVDD_L "Front drive inverter: a002 undervolt VDD l";
CM_ SG_ 1318 DIF_a002_overvoltVDD_L "Front drive inverter: a002 overvolt VDD l";
CM_ SG_ 1318 DIF_a002_localRegError_L "Front drive inverter: a002 local reg error l";
CM_ SG_ 1318 DIF_a002_spiError_L "Front drive inverter: a002 spi error l";
CM_ SG_ 1318 DIF_a002_deadtimeError_L "Front drive inverter: a002 deadtime error l";
CM_ SG_ 1318 DIF_a002_gateDriveErrCounter "Front drive inverter: a002 gate drive err counter";
CM_ SG_ 1318 DIF_a002_remoteCommError_H "Front drive inverter: a002 remote comm error h";
CM_ SG_ 1318 DIF_a002_localCommError_H "Front drive inverter: a002 local comm error h";
CM_ SG_ 1318 DIF_a002_remoteReset_H "Front drive inverter: a002 remote reset h";
CM_ SG_ 1318 DIF_a002_localReset_H "Front drive inverter: a002 local reset h";
CM_ SG_ 1318 DIF_a002_remoteCommError_L "Front drive inverter: a002 remote comm error l";
CM_ SG_ 1318 DIF_a002_localCommError_L "Front drive inverter: a002 local comm error l";
CM_ SG_ 1318 DIF_a002_remoteReset_L "Front drive inverter: a002 remote reset l";
CM_ SG_ 1318 DIF_a002_localReset_L "Front drive inverter: a002 local reset l";
CM_ SG_ 1318 DIF_a002_faultLine1Gpio_H "Front drive inverter: a002 fault line1 gpio h";
CM_ SG_ 1318 DIF_a002_faultLine1Gpio_L "Front drive inverter: a002 fault line1 gpio l";
CM_ SG_ 1318 DIF_a003_thermalWarning_H "Front drive inverter: a003 thermal warning h";
CM_ SG_ 1318 DIF_a003_thermalShutdown_H "Front drive inverter: a003 thermal shutdown h";
CM_ SG_ 1318 DIF_a003_undervoltVL_H "Front drive inverter: a003 undervolt VL h";
CM_ SG_ 1318 DIF_a003_undervoltVH_H "Front drive inverter: a003 undervolt VH h";
CM_ SG_ 1318 DIF_a003_sense_H "Front drive inverter: a003 sense h";
CM_ SG_ 1318 DIF_a003_desat_H "Front drive inverter: a003 desat h";
CM_ SG_ 1318 DIF_a003_overvoltVL_H "Front drive inverter: a003 overvolt VL h";
CM_ SG_ 1318 DIF_a003_overvoltVH_H "Front drive inverter: a003 overvolt VH h";
CM_ SG_ 1318 DIF_a003_undervoltVCC_H "Front drive inverter: a003 undervolt VCC h";
CM_ SG_ 1318 DIF_a003_asynchStop_H "Front drive inverter: a003 asynch stop h";
CM_ SG_ 1318 DIF_a003_remoteRegError_H "Front drive inverter: a003 remote reg error h";
CM_ SG_ 1318 DIF_a003_undervoltVDD_H "Front drive inverter: a003 undervolt VDD h";
CM_ SG_ 1318 DIF_a003_overvoltVDD_H "Front drive inverter: a003 overvolt VDD h";
CM_ SG_ 1318 DIF_a003_localRegError_H "Front drive inverter: a003 local reg error h";
CM_ SG_ 1318 DIF_a003_spiError_H "Front drive inverter: a003 spi error h";
CM_ SG_ 1318 DIF_a003_deadtimeError_H "Front drive inverter: a003 deadtime error h";
CM_ SG_ 1318 DIF_a003_thermalWarning_L "Front drive inverter: a003 thermal warning l";
CM_ SG_ 1318 DIF_a003_thermalShutdown_L "Front drive inverter: a003 thermal shutdown l";
CM_ SG_ 1318 DIF_a003_undervoltVL_L "Front drive inverter: a003 undervolt VL l";
CM_ SG_ 1318 DIF_a003_undervoltVH_L "Front drive inverter: a003 undervolt VH l";
CM_ SG_ 1318 DIF_a003_sense_L "Front drive inverter: a003 sense l";
CM_ SG_ 1318 DIF_a003_desat_L "Front drive inverter: a003 desat l";
CM_ SG_ 1318 DIF_a003_overvoltVL_L "Front drive inverter: a003 overvolt VL l";
CM_ SG_ 1318 DIF_a003_overvoltVH_L "Front drive inverter: a003 overvolt VH l";
CM_ SG_ 1318 DIF_a003_undervoltVCC_L "Front drive inverter: a003 undervolt VCC l";
CM_ SG_ 1318 DIF_a003_asynchStop_L "Front drive inverter: a003 asynch stop l";
CM_ SG_ 1318 DIF_a003_remoteRegError_L "Front drive inverter: a003 remote reg error l";
CM_ SG_ 1318 DIF_a003_undervoltVDD_L "Front drive inverter: a003 undervolt VDD l";
CM_ SG_ 1318 DIF_a003_overvoltVDD_L "Front drive inverter: a003 overvolt VDD l";
CM_ SG_ 1318 DIF_a003_localRegError_L "Front drive inverter: a003 local reg error l";
CM_ SG_ 1318 DIF_a003_spiError_L "Front drive inverter: a003 spi error l";
CM_ SG_ 1318 DIF_a003_deadtimeError_L "Front drive inverter: a003 deadtime error l";
CM_ SG_ 1318 DIF_a003_gateDriveErrCounter "Front drive inverter: a003 gate drive err counter";
CM_ SG_ 1318 DIF_a003_remoteCommError_H "Front drive inverter: a003 remote comm error h";
CM_ SG_ 1318 DIF_a003_localCommError_H "Front drive inverter: a003 local comm error h";
CM_ SG_ 1318 DIF_a003_remoteReset_H "Front drive inverter: a003 remote reset h";
CM_ SG_ 1318 DIF_a003_localReset_H "Front drive inverter: a003 local reset h";
CM_ SG_ 1318 DIF_a003_remoteCommError_L "Front drive inverter: a003 remote comm error l";
CM_ SG_ 1318 DIF_a003_localCommError_L "Front drive inverter: a003 local comm error l";
CM_ SG_ 1318 DIF_a003_remoteReset_L "Front drive inverter: a003 remote reset l";
CM_ SG_ 1318 DIF_a003_localReset_L "Front drive inverter: a003 local reset l";
CM_ SG_ 1318 DIF_a003_faultLine1Gpio_H "Front drive inverter: a003 fault line1 gpio h";
CM_ SG_ 1318 DIF_a003_faultLine1Gpio_L "Front drive inverter: a003 fault line1 gpio l";
CM_ SG_ 1318 DIF_a007_phaseAcurrent "Front drive inverter: a007 phase acurrent";
CM_ SG_ 1318 DIF_a007_phaseBcurrent "Front drive inverter: a007 phase bcurrent";
CM_ SG_ 1318 DIF_a007_offsetError "Front drive inverter: a007 offset error";
CM_ SG_ 1318 DIF_a007_idFdbStdDeviation "Front drive inverter: a007 id fdb std deviation";
CM_ SG_ 1318 DIF_a007_iqFdbStdDeviation "Front drive inverter: a007 iq fdb std deviation";
CM_ SG_ 1318 DIF_a007_motorShift "Front drive inverter: a007 motor shift";
CM_ SG_ 1318 DIF_a007_motorShort "Front drive inverter: a007 motor short";
CM_ SG_ 1318 DIF_a010_sccReset "Front drive inverter: a010 scc reset";
CM_ SG_ 1318 DIF_a010_hibernate "Front drive inverter: a010 hibernate";
CM_ SG_ 1318 DIF_a010_hwBist "Front drive inverter: a010 hw bist";
CM_ SG_ 1318 DIF_a010_nmiWatchdog "Front drive inverter: a010 nmi watchdog";
CM_ SG_ 1318 DIF_a010_watchdog "Front drive inverter: a010 watchdog";
CM_ SG_ 1318 DIF_a010_clockFailNmi "Front drive inverter: a010 clock fail nmi";
CM_ SG_ 1318 DIF_a010_ramUncErrorNmi "Front drive inverter: a010 ram unc error nmi";
CM_ SG_ 1318 DIF_a010_flashUncErrorNmi "Front drive inverter: a010 flash unc error nmi";
CM_ SG_ 1318 DIF_a010_cpu1signMismatchNmi "Front drive inverter: a010 cpu1sign mismatch nmi";
CM_ SG_ 1318 DIF_a010_cpu2signMismatchNmi "Front drive inverter: a010 cpu2sign mismatch nmi";
CM_ SG_ 1318 DIF_a010_pieVectErrorNmi "Front drive inverter: a010 pie vect error nmi";
CM_ SG_ 1318 DIF_a010_sysDbgNmi "Front drive inverter: a010 sys dbg nmi";
CM_ SG_ 1318 DIF_a010_rlNmi "Front drive inverter: a010 rl nmi";
CM_ SG_ 1318 DIF_a010_ovfNmi "Front drive inverter: a010 ovf nmi";
CM_ SG_ 1318 DIF_a010_wdtFlags "Front drive inverter: a010 wdt flags";
CM_ SG_ 1318 DIF_a011_reason "Front drive inverter: a011 reason";
CM_ SG_ 1318 DIF_a011_phaseAHigh "Front drive inverter: a011 phase a high";
CM_ SG_ 1318 DIF_a011_phaseALow "Front drive inverter: a011 phase a low";
CM_ SG_ 1318 DIF_a011_phaseBHigh "Front drive inverter: a011 phase b high";
CM_ SG_ 1318 DIF_a011_phaseBLow "Front drive inverter: a011 phase b low";
CM_ SG_ 1318 DIF_a011_phaseCHigh "Front drive inverter: a011 phase c high";
CM_ SG_ 1318 DIF_a011_phaseCLow "Front drive inverter: a011 phase c low";
CM_ SG_ 1318 DIF_a011_regAddress "Front drive inverter: a011 reg address";
CM_ SG_ 1318 DIF_a011_badGateDriveIC "Front drive inverter: a011 bad gate drive IC";
CM_ SG_ 1318 DIF_a011_badDataRead "Front drive inverter: a011 bad data read";
CM_ SG_ 1318 DIF_a011_badDataExpected "Front drive inverter: a011 bad data expected";
CM_ SG_ 1318 DIF_a011_codeBranch "Front drive inverter: a011 code branch";
CM_ SG_ 1318 DIF_a012_hvilStatus "Front drive inverter: a012 hvil status; raw 3 = signal not available (SNA)";
CM_ SG_ 1318 DIF_a012_hvilCmVoltage "Front drive inverter: a012 hvil cm voltage";
CM_ SG_ 1318 DIF_a012_hvilCurrent "Front drive inverter: a012 hvil current";
CM_ SG_ 1318 DIF_a012_hvilFaultGpio "Front drive inverter: a012 hvil fault gpio";
CM_ SG_ 1318 DIF_a012_hvilSupplyPinDI "Front drive inverter: a012 hvil supply pin DI";
CM_ SG_ 1318 DIF_a012_hvilSupplyPinPM "Front drive inverter: a012 hvil supply pin PM";
CM_ SG_ 1318 DIF_a012_activeDisOn3V3 "Front drive inverter: a012 active dis on3 V3";
CM_ SG_ 1318 DIF_a012_hvilHeaderFault "Front drive inverter: a012 hvil header fault";
CM_ SG_ 1318 DIF_a013_address "Front drive inverter: a013 address";
CM_ SG_ 1318 DIF_a013_errorType "Front drive inverter: a013 error type";
CM_ SG_ 1318 DIF_a014_motorSpeed "Front drive inverter: a014 motor speed";
CM_ SG_ 1318 DIF_a014_adState "Front drive inverter: a014 ad state";
CM_ SG_ 1318 DIF_a014_torqueCommandFwd "Front drive inverter: a014 torque command fwd";
CM_ SG_ 1318 DIF_a014_brakeMasterCylPress "Front drive inverter: a014 brake master cyl press";
CM_ SG_ 1318 DIF_a014_rmsTorqueError "Front drive inverter: a014 rms torque error";
CM_ SG_ 1318 DIF_a014_tcEnabled "Front drive inverter: a014 tc enabled";
CM_ SG_ 1318 DIF_a014_fbDeratedForRmsError "Front drive inverter: a014 fb derated for rms error";
CM_ SG_ 1318 DIF_a016_newSafeState "Front drive inverter: a016 new safe state";
CM_ SG_ 1318 DIF_a016_oldSafeState "Front drive inverter: a016 old safe state";
CM_ SG_ 1318 DIF_a016_gateDriveFaultLine "Front drive inverter: a016 gate drive fault line";
CM_ SG_ 1318 DIF_a016_ascMonitor "Front drive inverter: a016 asc monitor";
CM_ SG_ 1318 DIF_a016_uncontrolledRegenZone "Front drive inverter: a016 uncontrolled regen zone";
CM_ SG_ 1318 DIF_a016_pedalMonitorPreWatchdog "Front drive inverter: a016 pedal monitor pre watchdog";
CM_ SG_ 1318 DIF_a016_motorRPM "Front drive inverter: a016 motor RPM";
CM_ SG_ 1318 DIF_a016_torqueMotor "Front drive inverter: a016 torque motor";
CM_ SG_ 1318 DIF_a016_safetyICfaultLine "Front drive inverter: a016 safety i cfault line";
CM_ SG_ 1318 DIF_a016_triggerEvent "Front drive inverter: a016 trigger event";
CM_ SG_ 1318 DIF_a024_vBat "Front drive inverter: a024 v bat";
CM_ SG_ 1318 DIF_a024_failReason "Front drive inverter: a024 fail reason";
CM_ SG_ 1318 DIF_a024_state "Front drive inverter: a024 state";
CM_ SG_ 1318 DIF_a024_Ia "Front drive inverter: a024 ia";
CM_ SG_ 1318 DIF_a024_Ib "Front drive inverter: a024 ib";
CM_ SG_ 1318 DIF_a024_maxCurrMagSqrd "Front drive inverter: a024 max curr mag sqrd";
CM_ SG_ 1318 DIF_a024_rotorAngle "Front drive inverter: a024 rotor angle";
CM_ SG_ 1318 DIF_a025_Ia "Front drive inverter: a025 ia";
CM_ SG_ 1318 DIF_a025_torqueMotor "Front drive inverter: a025 torque motor";
CM_ SG_ 1318 DIF_a025_motorSpeed "Front drive inverter: a025 motor speed";
CM_ SG_ 1318 DIF_a026_Ib "Front drive inverter: a026 ib";
CM_ SG_ 1318 DIF_a026_torqueMotor "Front drive inverter: a026 torque motor";
CM_ SG_ 1318 DIF_a026_motorSpeed "Front drive inverter: a026 motor speed";
CM_ SG_ 1318 DIF_a027_Ic "Front drive inverter: a027 ic";
CM_ SG_ 1318 DIF_a027_torqueMotor "Front drive inverter: a027 torque motor";
CM_ SG_ 1318 DIF_a027_motorSpeed "Front drive inverter: a027 motor speed";
CM_ SG_ 1318 DIF_a028_phaseAirms "Front drive inverter: a028 phase airms";
CM_ SG_ 1318 DIF_a028_iArmsTorque "Front drive inverter: a028 i arms torque";
CM_ SG_ 1318 DIF_a028_iArmsSpeed "Front drive inverter: a028 i arms speed";
CM_ SG_ 1318 DIF_a029_phaseBirms "Front drive inverter: a029 phase birms";
CM_ SG_ 1318 DIF_a029_iBrmsTorque "Front drive inverter: a029 i brms torque";
CM_ SG_ 1318 DIF_a029_iBrmsSpeed "Front drive inverter: a029 i brms speed";
CM_ SG_ 1318 DIF_a030_phaseCirms "Front drive inverter: a030 phase cirms";
CM_ SG_ 1318 DIF_a030_iCrmsTorque "Front drive inverter: a030 i crms torque";
CM_ SG_ 1318 DIF_a030_iCrmsSpeed "Front drive inverter: a030 i crms speed";
CM_ SG_ 1318 DIF_a031_phaseAoffset "Front drive inverter: a031 phase aoffset";
CM_ SG_ 1318 DIF_a032_phaseBoffset "Front drive inverter: a032 phase boffset";
CM_ SG_ 1318 DIF_a033_phaseAcurrent "Front drive inverter: a033 phase acurrent";
CM_ SG_ 1318 DIF_a033_deltaIa "Front drive inverter: a033 delta ia";
CM_ SG_ 1318 DIF_a033_vRefIa "Front drive inverter: a033 v ref ia";
CM_ SG_ 1318 DIF_a034_phaseBcurrent "Front drive inverter: a034 phase bcurrent";
CM_ SG_ 1318 DIF_a034_deltaIb "Front drive inverter: a034 delta ib";
CM_ SG_ 1318 DIF_a034_vRefIb "Front drive inverter: a034 v ref ib";
CM_ SG_ 1318 DIF_a035_phaseAerror "Front drive inverter: a035 phase aerror";
CM_ SG_ 1318 DIF_a035_phaseBerror "Front drive inverter: a035 phase berror";
CM_ SG_ 1318 DIF_a035_phaseCerror "Front drive inverter: a035 phase cerror";
CM_ SG_ 1318 DIF_a035_standbyCurrent "Front drive inverter: a035 standby current";
CM_ SG_ 1318 DIF_a035_unbalancedCurrent "Front drive inverter: a035 unbalanced current";
CM_ SG_ 1318 DIF_a035_wontMoveCurrent "Front drive inverter: a035 wont move current";
CM_ SG_ 1318 DIF_a035_reportingPhase "Front drive inverter: a035 reporting phase";
CM_ SG_ 1318 DIF_a035_noDriveCurrent "Front drive inverter: a035 no drive current";
CM_ SG_ 1318 DIF_a035_phaseDifference "Front drive inverter: a035 phase difference";
CM_ SG_ 1318 DIF_a035_phaseCurrent "Front drive inverter: a035 phase current";
CM_ SG_ 1318 DIF_a035_frequency "Front drive inverter: a035 frequency";
CM_ SG_ 1318 DIF_a036_busVoltage "Front drive inverter: a036 bus voltage";
CM_ SG_ 1318 DIF_a036_busHighLimit "Front drive inverter: a036 bus high limit";
CM_ SG_ 1318 DIF_a037_busVoltage "Front drive inverter: a037 bus voltage";
CM_ SG_ 1318 DIF_a037_busLowLimit "Front drive inverter: a037 bus low limit";
CM_ SG_ 1318 DIF_a038_vBMS "Front drive inverter: a038 v BMS";
CM_ SG_ 1318 DIF_a038_vBat "Front drive inverter: a038 v bat";
CM_ SG_ 1318 DIF_a038_iBat "Front drive inverter: a038 i bat";
CM_ SG_ 1318 DIF_a038_reason "Front drive inverter: a038 reason";
CM_ SG_ 1318 DIF_a040_torque "Front drive inverter: a040 torque";
CM_ SG_ 1318 DIF_a040_capability "Front drive inverter: a040 capability";
CM_ SG_ 1318 DIF_a040_power "Front drive inverter: a040 power";
CM_ SG_ 1318 DIF_a040_status "Front drive inverter: a040 status";
CM_ SG_ 1318 DIF_a040_capability2 "Front drive inverter: a040 capability2";
CM_ SG_ 1318 DIF_a040_hvStatus "Front drive inverter: a040 hv status";
CM_ SG_ 1318 DIF_a040_temperature "Front drive inverter: a040 temperature";
CM_ SG_ 1318 DIF_a041_uartRxDataAvailable "Front drive inverter: a041 uart rx data available";
CM_ SG_ 1318 DIF_a041_SDC_status_MIA "Front drive inverter: a041 SDC status MIA";
CM_ SG_ 1318 DIF_a041_diUartRxVersion "Front drive inverter: a041 di uart rx version";
CM_ SG_ 1318 DIF_a041_sdcUartRxVersion "Front drive inverter: a041 sdc uart rx version";
CM_ SG_ 1318 DIF_a043_outletTemp "Front drive inverter: a043 outlet temp";
CM_ SG_ 1318 DIF_a044_outletTemp "Front drive inverter: a044 outlet temp";
CM_ SG_ 1318 DIF_a045_inletTemp "Front drive inverter: a045 inlet temp";
CM_ SG_ 1318 DIF_a045_outletTemp "Front drive inverter: a045 outlet temp";
CM_ SG_ 1318 DIF_a045_heatsinkTemp "Front drive inverter: a045 heatsink temp";
CM_ SG_ 1318 DIF_a045_outletTempSlope "Front drive inverter: a045 outlet temp slope";
CM_ SG_ 1318 DIF_a046_statorTemp1 "Front drive inverter: a046 stator temp1";
CM_ SG_ 1318 DIF_a046_statorTemp2 "Front drive inverter: a046 stator temp2";
CM_ SG_ 1318 DIF_a047_statorTemp1 "Front drive inverter: a047 stator temp1";
CM_ SG_ 1318 DIF_a047_statorTslope1 "Front drive inverter: a047 stator tslope1";
CM_ SG_ 1318 DIF_a050_statorTemp1 "Front drive inverter: a050 stator temp1";
CM_ SG_ 1318 DIF_a050_statorTemp2 "Front drive inverter: a050 stator temp2";
CM_ SG_ 1318 DIF_a052_torque "Front drive inverter: a052 torque";
CM_ SG_ 1318 DIF_a052_capability "Front drive inverter: a052 capability";
CM_ SG_ 1318 DIF_a052_power "Front drive inverter: a052 power";
CM_ SG_ 1318 DIF_a052_status "Front drive inverter: a052 status";
CM_ SG_ 1318 DIF_a052_capability2 "Front drive inverter: a052 capability2";
CM_ SG_ 1318 DIF_a052_hvStatus "Front drive inverter: a052 hv status";
CM_ SG_ 1318 DIF_a052_temperature "Front drive inverter: a052 temperature";
CM_ SG_ 1318 DIF_a054_outletTemp "Front drive inverter: a054 outlet temp";
CM_ SG_ 1318 DIF_a054_heatsinkTemp "Front drive inverter: a054 heatsink temp";
CM_ SG_ 1318 DIF_a055_parameterDI "Front drive inverter: a055 parameter DI";
CM_ SG_ 1318 DIF_a055_parameterPM "Front drive inverter: a055 parameter PM";
CM_ SG_ 1318 DIF_a055_torqueType "Front drive inverter: a055 torque type";
CM_ SG_ 1318 DIF_a055_motorRPM "Front drive inverter: a055 motor RPM";
CM_ SG_ 1318 DIF_a056_pcbTemp "Front drive inverter: a056 pcb temp";
CM_ SG_ 1318 DIF_a057_pcbTemp "Front drive inverter: a057 pcb temp";
CM_ SG_ 1318 DIF_a058_pcbTemp "Front drive inverter: a058 pcb temp";
CM_ SG_ 1318 DIF_a058_outletTemp "Front drive inverter: a058 outlet temp";
CM_ SG_ 1318 DIF_a058_heatsinkTemp "Front drive inverter: a058 heatsink temp";
CM_ SG_ 1318 DIF_a058_pcbTempSlope "Front drive inverter: a058 pcb temp slope";
CM_ SG_ 1318 DIF_a059_heatsinkTemp "Front drive inverter: a059 heatsink temp";
CM_ SG_ 1318 DIF_a060_heatsinkTemp "Front drive inverter: a060 heatsink temp";
CM_ SG_ 1318 DIF_a061_sensor "Front drive inverter: a061 sensor";
CM_ SG_ 1318 DIF_a061_reason "Front drive inverter: a061 reason";
CM_ SG_ 1318 DIF_a061_phTemp "Front drive inverter: a061 ph temp";
CM_ SG_ 1318 DIF_a061_otherTemp "Front drive inverter: a061 other temp";
CM_ SG_ 1318 DIF_a062_limpReason "Front drive inverter: a062 limp reason";
CM_ SG_ 1318 DIF_a063_BB_status "Front drive inverter: a063 BB status";
CM_ SG_ 1318 DIF_a064_interventionType "Front drive inverter: a064 intervention type";
CM_ SG_ 1318 DIF_a064_torqueCmdState "Front drive inverter: a064 torque cmd state; raw 0 = signal not available (SNA)";
CM_ SG_ 1318 DIF_a069_motorSpeed "Front drive inverter: a069 motor speed";
CM_ SG_ 1318 DIF_a069_rotorCoolingPower "Front drive inverter: a069 rotor cooling power";
CM_ SG_ 1318 DIF_a069_rotorMagnetTemp "Front drive inverter: a069 rotor magnet temp";
CM_ SG_ 1318 DIF_a069_fittedTorqueLimit "Front drive inverter: a069 fitted torque limit";
CM_ SG_ 1318 DIF_a072_reason "Front drive inverter: a072 reason";
CM_ SG_ 1318 DIF_a073_motorSpeedrpm "Front drive inverter: a073 motor speedrpm";
CM_ SG_ 1318 DIF_a075_motorSpeed "Front drive inverter: a075 motor speed";
CM_ SG_ 1318 DIF_a075_absSpeed "Front drive inverter: a075 abs speed";
CM_ SG_ 1318 DIF_a076_lvSupplyV "Front drive inverter: a076 lv supply v";
CM_ SG_ 1318 DIF_a077_lvSupplyV "Front drive inverter: a077 lv supply v";
CM_ SG_ 1318 DIF_a078_adcRefChan "Front drive inverter: a078 adc ref chan";
CM_ SG_ 1318 DIF_a078_adcRefLowAvg "Front drive inverter: a078 adc ref low avg";
CM_ SG_ 1318 DIF_a079_adcRefChan "Front drive inverter: a079 adc ref chan";
CM_ SG_ 1318 DIF_a079_adcRefHighAvg "Front drive inverter: a079 adc ref high avg";
CM_ SG_ 1318 DIF_a087_gtwCarConfig "Front drive inverter: a087 gtw car config";
CM_ SG_ 1318 DIF_a087_gtwTime "Front drive inverter: a087 gtw time";
CM_ SG_ 1318 DIF_a087_gtwUpdateStatus "Front drive inverter: a087 gtw update status";
CM_ SG_ 1318 DIF_a087_gearControl "Front drive inverter: a087 gear control";
CM_ SG_ 1318 DIF_a087_carState "Front drive inverter: a087 car state";
CM_ SG_ 1318 DIF_a090_reason "Front drive inverter: a090 reason";
CM_ SG_ 1318 DIF_a090_systemState "Front drive inverter: a090 system state";
CM_ SG_ 1318 DIF_a090_state "Front drive inverter: a090 state";
CM_ SG_ 1318 DIF_a090_locState "Front drive inverter: a090 loc state";
CM_ SG_ 1318 DIF_a090_state2 "Front drive inverter: a090 state2";
CM_ SG_ 1318 DIF_a090_state4 "Front drive inverter: a090 state4";
CM_ SG_ 1318 DIF_a091_ESP_brakeTorque "Front drive inverter: a091 ESP brake torque";
CM_ SG_ 1318 DIF_a091_ESP_wheelSpeeds "Front drive inverter: a091 ESP wheel speeds";
CM_ SG_ 1318 DIF_a091_ESP_wheelRotation "Front drive inverter: a091 ESP wheel rotation";
CM_ SG_ 1318 DIF_a091_ESP_motorLimits "Front drive inverter: a091 ESP motor limits";
CM_ SG_ 1318 DIF_a091_ESP_offsets "Front drive inverter: a091 ESP offsets";
CM_ SG_ 1318 DIF_a091_ESP_status "Front drive inverter: a091 ESP status";
CM_ SG_ 1318 DIF_a091_ESP_party3 "Front drive inverter: a091 ESP party3";
CM_ SG_ 1318 DIF_a091_ESP_redundantBrakingSta "Front drive inverter: a091 ESP redundant braking status";
CM_ SG_ 1318 DIF_a092_bmsStatus "Front drive inverter: a092 bms status";
CM_ SG_ 1318 DIF_a092_bmsDriveLimits "Front drive inverter: a092 bms drive limits";
CM_ SG_ 1318 DIF_a092_bmsHvBusStatus "Front drive inverter: a092 bms hv bus status";
CM_ SG_ 1318 DIF_a092_bmsPowerAvailable "Front drive inverter: a092 bms power available";
CM_ SG_ 1318 DIF_a092_bmsBmbMinMax "Front drive inverter: a092 bms bmb min max";
CM_ SG_ 1318 DIF_a092_bmsSocStatus "Front drive inverter: a092 bms soc status";
CM_ SG_ 1318 DIF_a092_bmsThermalStatus "Front drive inverter: a092 bms thermal status";
CM_ SG_ 1318 DIF_a092_bmsCtrStatus "Front drive inverter: a092 bms ctr status";
CM_ SG_ 1318 DIF_a092_bmsVoltageRegGain "Front drive inverter: a092 bms voltage reg gain";
CM_ SG_ 1318 DIF_a092_bmsPackConfig "Front drive inverter: a092 bms pack config";
CM_ SG_ 1318 DIF_a092_bmsSystemStatus "Front drive inverter: a092 bms system status";
CM_ SG_ 1318 DIF_a096_const_fast "Front drive inverter: a096 const fast";
CM_ SG_ 1318 DIF_a096_text_fast "Front drive inverter: a096 text fast";
CM_ SG_ 1318 DIF_a096_text_flash "Front drive inverter: a096 text flash";
CM_ SG_ 1318 DIF_a096_mem_data "Front drive inverter: a096 mem data";
CM_ SG_ 1318 DIF_a096_mem_regs "Front drive inverter: a096 mem regs";
CM_ SG_ 1318 DIF_a096_boot_flash "Front drive inverter: a096 boot flash";
CM_ SG_ 1318 DIF_a096_word1 "Front drive inverter: a096 word1";
CM_ SG_ 1318 DIF_a096_word2 "Front drive inverter: a096 word2";
CM_ SG_ 1318 DIF_a097_errorType "Front drive inverter: a097 error type";
CM_ SG_ 1318 DIF_a097_lineNumber "Front drive inverter: a097 line number";
CM_ SG_ 1318 DIF_a097_argument "Front drive inverter: a097 argument";
CM_ SG_ 1318 DIF_a098_pwmCount "Front drive inverter: a098 pwm count";
CM_ SG_ 1318 DIF_a098_fluxState "Front drive inverter: a098 flux state";
CM_ SG_ 1318 DIF_a103_fluidTorDeltaT "Front drive inverter: a103 fluid tor delta t";
CM_ SG_ 1318 DIF_a103_noFlowDetected "Front drive inverter: a103 no flow detected";
CM_ SG_ 1318 DIF_a103_lowFlowDetected "Front drive inverter: a103 low flow detected";
CM_ SG_ 1318 DIF_a103_fluidImplausible "Front drive inverter: a103 fluid implausible";
CM_ SG_ 1318 DIF_a103_inverterTemp "Front drive inverter: a103 inverter temp";
CM_ SG_ 1318 DIF_a103_rmsCurrent "Front drive inverter: a103 rms current";
CM_ SG_ 1318 DIF_a103_ambientTemp "Front drive inverter: a103 ambient temp";
CM_ SG_ 1318 DIF_a103_sensorTempEst "Front drive inverter: a103 sensor temp est";
CM_ SG_ 1318 DIF_a107_fpgaVersion "Front drive inverter: a107 fpga version";
CM_ SG_ 1318 DIF_a107_fpgaBootVersion "Front drive inverter: a107 fpga boot version";
CM_ SG_ 1318 DIF_a107_fpgaMasterActive "Front drive inverter: a107 fpga master active";
CM_ SG_ 1318 DIF_a107_fpgaFaultActive "Front drive inverter: a107 fpga fault active";
CM_ SG_ 1318 DIF_a107_fpgaWarningActive "Front drive inverter: a107 fpga warning active";
CM_ SG_ 1318 DIF_a108_fromState "Front drive inverter: a108 from state";
CM_ SG_ 1318 DIF_a108_toState "Front drive inverter: a108 to state";
CM_ SG_ 1318 DIF_a108_blockingAlert "Front drive inverter: a108 blocking alert";
CM_ SG_ 1318 DIF_a110_EPBL_status "Front drive inverter: a110 EPBL status";
CM_ SG_ 1318 DIF_a110_EPBR_status "Front drive inverter: a110 EPBR status";
CM_ SG_ 1318 DIF_a110_EPBL_autonomyHealth "Front drive inverter: a110 EPBL autonomy health";
CM_ SG_ 1318 DIF_a110_EPBR_autonomyHealth "Front drive inverter: a110 EPBR autonomy health";
CM_ SG_ 1318 DIF_a111_phAcalib "Front drive inverter: a111 ph acalib";
CM_ SG_ 1318 DIF_a111_phBcalib "Front drive inverter: a111 ph bcalib";
CM_ SG_ 1318 DIF_a112_pwmSwitching "Front drive inverter: a112 pwm switching";
CM_ SG_ 1318 DIF_a112_gdicResetLine "Front drive inverter: a112 gdic reset line";
CM_ SG_ 1318 DIF_a112_allOffSafeState "Front drive inverter: a112 all off safe state";
CM_ SG_ 1318 DIF_a112_ls3psSafeState "Front drive inverter: a112 ls3ps safe state";
CM_ SG_ 1318 DIF_a112_hs3psSafeState "Front drive inverter: a112 hs3ps safe state";
CM_ SG_ 1318 DIF_a112_modulationIndex "Front drive inverter: a112 modulation index";
CM_ SG_ 1318 DIF_a113_heatsink1Temp "Front drive inverter: a113 heatsink1 temp";
CM_ SG_ 1318 DIF_a113_heatsink2Temp "Front drive inverter: a113 heatsink2 temp";
CM_ SG_ 1318 DIF_a113_heatsink3Temp "Front drive inverter: a113 heatsink3 temp";
CM_ SG_ 1318 DIF_a117_torque "Front drive inverter: a117 torque";
CM_ SG_ 1318 DIF_a117_slaveCommand "Front drive inverter: a117 slave command";
CM_ SG_ 1318 DIF_a117_power "Front drive inverter: a117 power";
CM_ SG_ 1318 DIF_a117_slaveCommand2 "Front drive inverter: a117 slave command2";
CM_ SG_ 1318 DIF_a117_speed "Front drive inverter: a117 speed";
CM_ SG_ 1318 DIF_a117_chassisControl "Front drive inverter: a117 chassis control";
CM_ SG_ 1318 DIF_a117_systemStatus "Front drive inverter: a117 system status";
CM_ SG_ 1318 DIF_a117_temperature "Front drive inverter: a117 temperature";
CM_ SG_ 1318 DIF_a117_vehicle "Front drive inverter: a117 vehicle";
CM_ SG_ 1318 DIF_a117_AddTcLimit "Front drive inverter: a117 add tc limit";
CM_ SG_ 1318 DIF_a117_dixCommand "Front drive inverter: a117 dix command";
CM_ SG_ 1318 DIF_a117_odometerStatus "Front drive inverter: a117 odometer status";
CM_ SG_ 1318 DIF_a119_hvpFaults "Front drive inverter: a119 hvp faults";
CM_ SG_ 1318 DIF_a120_dcLinkInfo "Front drive inverter: a120 dc link info";
CM_ SG_ 1318 DIF_a121_badRegReason "Front drive inverter: a121 bad reg reason";
CM_ SG_ 1318 DIF_a121_torqueDelta "Front drive inverter: a121 torque delta";
CM_ SG_ 1318 DIF_a121_badCurrent "Front drive inverter: a121 bad current";
CM_ SG_ 1318 DIF_a121_badFlux "Front drive inverter: a121 bad flux";
CM_ SG_ 1318 DIF_a123_lossReason "Front drive inverter: a123 loss reason";
CM_ SG_ 1318 DIF_a123_busVoltage "Front drive inverter: a123 bus voltage";
CM_ SG_ 1318 DIF_a123_badFlux "Front drive inverter: a123 bad flux";
CM_ SG_ 1318 DIF_a123_lossRequest "Front drive inverter: a123 loss request";
CM_ SG_ 1318 DIF_a123_badCurrent "Front drive inverter: a123 bad current";
CM_ SG_ 1318 DIF_a123_motorRPM "Front drive inverter: a123 motor RPM";
CM_ SG_ 1318 DIF_a123_varianceD "Front drive inverter: a123 variance d";
CM_ SG_ 1318 DIF_a123_varianceQ "Front drive inverter: a123 variance q";
CM_ SG_ 1318 DIF_a126_limpReason "Front drive inverter: a126 limp reason";
CM_ SG_ 1318 DIF_a127_gpoReason "Front drive inverter: a127 gpo reason";
CM_ SG_ 1318 DIF_a127_temp "Front drive inverter: a127 temp";
CM_ SG_ 1318 DIF_a133_capacitorTemp "Front drive inverter: a133 capacitor temp";
CM_ SG_ 1318 DIF_a133_badValue1 "Front drive inverter: a133 bad value1";
CM_ SG_ 1318 DIF_a133_badValue2 "Front drive inverter: a133 bad value2";
CM_ SG_ 1318 DIF_a134_wheelSpeedDiffFrL "Front drive inverter: a134 wheel speed diff fr l";
CM_ SG_ 1318 DIF_a134_wheelSpeedDiffFrR "Front drive inverter: a134 wheel speed diff fr r";
CM_ SG_ 1318 DIF_a134_wheelSpeedDiffReL "Front drive inverter: a134 wheel speed diff re l";
CM_ SG_ 1318 DIF_a134_wheelSpeedDiffReR "Front drive inverter: a134 wheel speed diff re r";
CM_ SG_ 1318 DIF_a136_spiError_BL "Front drive inverter: a136 spi error BL";
CM_ SG_ 1318 DIF_a136_crcError_BL "Front drive inverter: a136 crc error BL";
CM_ SG_ 1318 DIF_a136_busyError_BL "Front drive inverter: a136 busy error BL";
CM_ SG_ 1318 DIF_a136_spiError_BH "Front drive inverter: a136 spi error BH";
CM_ SG_ 1318 DIF_a136_crcError_BH "Front drive inverter: a136 crc error BH";
CM_ SG_ 1318 DIF_a136_busyError_BH "Front drive inverter: a136 busy error BH";
CM_ SG_ 1318 DIF_a136_spiError_CL "Front drive inverter: a136 spi error CL";
CM_ SG_ 1318 DIF_a136_crcError_CL "Front drive inverter: a136 crc error CL";
CM_ SG_ 1318 DIF_a136_busyError_CL "Front drive inverter: a136 busy error CL";
CM_ SG_ 1318 DIF_a136_spiError_CH "Front drive inverter: a136 spi error CH";
CM_ SG_ 1318 DIF_a136_crcError_CH "Front drive inverter: a136 crc error CH";
CM_ SG_ 1318 DIF_a136_busyError_CH "Front drive inverter: a136 busy error CH";
CM_ SG_ 1318 DIF_a136_spiError_AL "Front drive inverter: a136 spi error AL";
CM_ SG_ 1318 DIF_a136_crcError_AL "Front drive inverter: a136 crc error AL";
CM_ SG_ 1318 DIF_a136_busyError_AL "Front drive inverter: a136 busy error AL";
CM_ SG_ 1318 DIF_a136_spiError_AH "Front drive inverter: a136 spi error AH";
CM_ SG_ 1318 DIF_a136_crcError_AH "Front drive inverter: a136 crc error AH";
CM_ SG_ 1318 DIF_a136_busyError_AH "Front drive inverter: a136 busy error AH";
CM_ SG_ 1318 DIF_a144_autopilot "Front drive inverter: a144 autopilot";
CM_ SG_ 1318 DIF_a144_chassisType "Front drive inverter: a144 chassis type";
CM_ SG_ 1318 DIF_a144_drivetrainType "Front drive inverter: a144 drivetrain type";
CM_ SG_ 1318 DIF_a144_packEnergy "Front drive inverter: a144 pack energy";
CM_ SG_ 1318 DIF_a144_packPerformanceDeviatio "Front drive inverter: a144 pack performance deviation";
CM_ SG_ 1318 DIF_a144_performancePackage "Front drive inverter: a144 performance package";
CM_ SG_ 1318 DIF_a144_vdcType "Front drive inverter: a144 vdc type";
CM_ SG_ 1318 DIF_a144_brakeHWType "Front drive inverter: a144 brake HW type";
CM_ SG_ 1318 DIF_a144_inverterHardware "Front drive inverter: a144 inverter hardware";
CM_ SG_ 1318 DIF_a144_cabinPTCHeaterType "Front drive inverter: a144 cabin PTC heater type";
CM_ SG_ 1318 DIF_a144_frunkLatchType "Front drive inverter: a144 frunk latch type";
CM_ SG_ 1318 DIF_a144_platformMaxBusVoltage "Front drive inverter: a144 platform max bus voltage";
CM_ SG_ 1318 DIF_a144_oilPump1HwType "Front drive inverter: a144 oil pump1 hw type";
CM_ SG_ 1318 DIF_a144_oilPump2HwType "Front drive inverter: a144 oil pump2 hw type";
CM_ SG_ 1318 DIF_a144_heatsinkType "Front drive inverter: a144 heatsink type";
CM_ SG_ 1318 DIF_a144_softPerformanceLimit "Front drive inverter: a144 soft performance limit";
CM_ SG_ 1318 DIF_a144_brakeActuationType "Front drive inverter: a144 brake actuation type";
CM_ SG_ 1318 DIF_a144_dasHw "Front drive inverter: a144 das hw";
CM_ SG_ 1318 DIF_a144_powerLiftgateType "Front drive inverter: a144 power liftgate type";
CM_ SG_ 1318 DIF_a144_chassisSubType "Front drive inverter: a144 chassis sub type";
CM_ SG_ 1318 DIF_a144_autonomyFeatureType "Front drive inverter: a144 autonomy feature type";
CM_ SG_ 1318 DIF_a147_overtorque1UsedCount "Front drive inverter: a147 overtorque1 used count";
CM_ SG_ 1318 DIF_a147_overtorque2UsedCount "Front drive inverter: a147 overtorque2 used count";
CM_ SG_ 1318 DIF_a147_accumulatedWear "Front drive inverter: a147 accumulated wear";
CM_ SG_ 1318 DIF_a147_wearIsValid "Front drive inverter: a147 wear is valid";
CM_ SG_ 1318 DIF_a149_flow "Front drive inverter: a149 flow; raw 255 = signal not available (SNA)";
CM_ SG_ 1318 DIF_a149_voltage "Front drive inverter: a149 voltage";
CM_ SG_ 1318 DIF_a149_temperature "Front drive inverter: a149 temperature";
CM_ SG_ 1318 DIF_a149_state "Front drive inverter: a149 state; raw 7 = signal not available (SNA)";
CM_ SG_ 1318 DIF_a149_fluidTempSNA "Front drive inverter: a149 fluid temp SNA";
CM_ SG_ 1318 DIF_a149_insufficientFlow "Front drive inverter: a149 insufficient flow";
CM_ SG_ 1318 DIF_a149_motorOpenPhase "Front drive inverter: a149 motor open phase";
CM_ SG_ 1318 DIF_a149_motorShorted "Front drive inverter: a149 motor shorted";
CM_ SG_ 1318 DIF_a149_motorFlowSNA "Front drive inverter: a149 motor flow SNA";
CM_ SG_ 1318 DIF_a149_responseError "Front drive inverter: a149 response error";
CM_ SG_ 1318 DIF_a149_pcbaID "Front drive inverter: a149 pcba ID";
CM_ SG_ 1318 DIF_a150_vBatRawMinusFiltered "Front drive inverter: a150 v bat raw minus filtered";
CM_ SG_ 1318 DIF_a150_vBatFilteredRate "Front drive inverter: a150 v bat filtered rate";
CM_ SG_ 1318 DIF_a150_elapsedMs "Front drive inverter: a150 elapsed ms";
CM_ SG_ 1318 DIF_a150_energy "Front drive inverter: a150 energy";
CM_ SG_ 1318 DIF_a152_errorType "Front drive inverter: a152 error type";
CM_ SG_ 1318 DIF_a152_frameId "Front drive inverter: a152 frame id";
CM_ SG_ 1318 DIF_a152_badValue "Front drive inverter: a152 bad value";
CM_ SG_ 1318 DIF_a152_expectedValue "Front drive inverter: a152 expected value";
CM_ SG_ 1318 DIF_a154_motorRPM "Front drive inverter: a154 motor RPM";
CM_ SG_ 1318 DIF_a154_phaseError "Front drive inverter: a154 phase error";
CM_ SG_ 1318 DIF_a154_commonGain "Front drive inverter: a154 common gain";
CM_ SG_ 1318 DIF_a154_noCalibration "Front drive inverter: a154 no calibration";
CM_ SG_ 1318 DIF_a154_noPhaseLock "Front drive inverter: a154 no phase lock";
CM_ SG_ 1318 DIF_a154_noCarrier "Front drive inverter: a154 no carrier";
CM_ SG_ 1318 DIF_a154_notReady "Front drive inverter: a154 not ready";
CM_ SG_ 1318 DIF_a154_errorTableInvalid "Front drive inverter: a154 error table invalid";
CM_ SG_ 1318 DIF_a154_carrierOffset "Front drive inverter: a154 carrier offset";
CM_ SG_ 1318 DIF_a154_trackerIrrational "Front drive inverter: a154 tracker irrational";
CM_ SG_ 1318 DIF_a154_claMIA "Front drive inverter: a154 cla MIA";
CM_ SG_ 1318 DIF_a155_sensors "Front drive inverter: a155 sensors";
CM_ SG_ 1318 DIF_a155_coolant "Front drive inverter: a155 coolant";
CM_ SG_ 1318 DIF_a155_LVPowerState "Front drive inverter: a155 LV power state";
CM_ SG_ 1318 DIF_a155_vehicleStatus "Front drive inverter: a155 vehicle status";
CM_ SG_ 1318 DIF_a155_status "Front drive inverter: a155 status";
CM_ SG_ 1318 DIF_a155_leftDoorStatus "Front drive inverter: a155 left door status";
CM_ SG_ 1318 DIF_a155_rightDoorStatus "Front drive inverter: a155 right door status";
CM_ SG_ 1318 DIF_a155_vcleftSwitchStatus "Front drive inverter: a155 vcleft switch status";
CM_ SG_ 1318 DIF_a155_restraintStatus "Front drive inverter: a155 restraint status";
CM_ SG_ 1318 DIF_a155_systemStatus "Front drive inverter: a155 system status";
CM_ SG_ 1318 DIF_a155_prndStatus "Front drive inverter: a155 prnd status";
CM_ SG_ 1318 DIF_a155_liftgateStatus "Front drive inverter: a155 liftgate status";
CM_ SG_ 1318 DIF_a157_RCM_inertial1 "Front drive inverter: a157 RCM inertial1";
CM_ SG_ 1318 DIF_a157_RCM_inertial2 "Front drive inverter: a157 RCM inertial2";
CM_ SG_ 1318 DIF_a158_IBST_party1 "Front drive inverter: a158 IBST party1";
CM_ SG_ 1318 DIF_a158_BUS1_IBST_status "Front drive inverter: a158 BUS1 IBST status";
CM_ SG_ 1318 DIF_a158_BUS2_IBST_status "Front drive inverter: a158 BUS2 IBST status";
CM_ SG_ 1318 DIF_a158_IBST_redundantBrakingSt "Front drive inverter: a158 IBST redundant braking status";
CM_ SG_ 1318 DIF_a160_vBatRawMinusFiltered "Front drive inverter: a160 v bat raw minus filtered";
CM_ SG_ 1318 DIF_a160_vBatFilteredRate "Front drive inverter: a160 v bat filtered rate";
CM_ SG_ 1318 DIF_a160_elapsedMs "Front drive inverter: a160 elapsed ms";
CM_ SG_ 1318 DIF_a160_energy "Front drive inverter: a160 energy";
CM_ SG_ 1318 DIF_a161_EPAS3P_sysStatus "Front drive inverter: a161 EPAS3 p sys status";
CM_ SG_ 1318 DIF_a161_EPAS3P_angleCalib "Front drive inverter: a161 EPAS3 p angle calib";
CM_ SG_ 1318 DIF_a172_statorTemp1 "Front drive inverter: a172 stator temp1";
CM_ SG_ 1318 DIF_a172_statorTemp2 "Front drive inverter: a172 stator temp2";
CM_ SG_ 1318 DIF_a202_reason "Front drive inverter: a202 reason";
CM_ SG_ 1318 DIF_a202_movement "Front drive inverter: a202 movement";
CM_ SG_ 1318 DIF_a202_sysStateExitCondition "Front drive inverter: a202 sys state exit condition";
CM_ SG_ 1318 DIF_a233_missedMsgCount "Front drive inverter: a233 missed msg count";
CM_ SG_ 1318 DIF_a233_serviceModeActive "Signal reported by Front drive inverter";
CM_ SG_ 1318 DIF_a234_PCS_dcdcStatus "Front drive inverter: a234 PCS dcdc status";
CM_ SG_ 1318 DIF_a236_states "Front drive inverter: a236 states";
CM_ SG_ 1318 DIF_a240_shortedSwitches "Front drive inverter: a240 shorted switches";
CM_ SG_ 1318 DIF_a240_primaryPattern "Front drive inverter: a240 primary pattern";
CM_ SG_ 1318 DIF_a240_secondaryPattern "Front drive inverter: a240 secondary pattern";
CM_ SG_ 1318 DIF_a240_fuseA_I2t "Front drive inverter: a240 fuse a i2t";
CM_ SG_ 1318 DIF_a240_fuseB_I2t "Front drive inverter: a240 fuse b i2t";
CM_ SG_ 1318 DIF_a240_primaryTimeout "Front drive inverter: a240 primary timeout";
CM_ SG_ 1318 DIF_a240_secondaryTimeout "Front drive inverter: a240 secondary timeout";
CM_ SG_ 1318 DIF_a240_primNoCurrentA "Front drive inverter: a240 prim no current a";
CM_ SG_ 1318 DIF_a240_primNoCurrentB "Front drive inverter: a240 prim no current b";
CM_ SG_ 1318 DIF_a240_secNoCurrentA "Front drive inverter: a240 sec no current a";
CM_ SG_ 1318 DIF_a240_secNoCurrentB "Front drive inverter: a240 sec no current b";
CM_ SG_ 1318 DIF_a240_primaryDutyCycle "Front drive inverter: a240 primary duty cycle";
CM_ SG_ 1318 DIF_a240_secondaryDutyCycle "Front drive inverter: a240 secondary duty cycle";
CM_ SG_ 1318 DIF_a240_confNoCurrentDetected "Front drive inverter: a240 conf no current detected";
CM_ SG_ 1318 DIF_a240_secondaryStrategy3ps "Front drive inverter: a240 secondary strategy3ps";
CM_ SG_ 1318 DIF_a242_RotorOffset "Front drive inverter: a242 rotor offset";
CM_ SG_ 1318 DIF_a242_RotorFlux "Front drive inverter: a242 rotor flux";
CM_ SG_ 1318 DIF_a242_ResolverError "Front drive inverter: a242 resolver error";
CM_ SG_ 1318 DIF_a244_desatHighSide "Front drive inverter: a244 desat high side";
CM_ SG_ 1318 DIF_a244_desatLowSide "Front drive inverter: a244 desat low side";
CM_ SG_ 1318 DIF_a244_singleSwitchShort "Front drive inverter: a244 single switch short";
CM_ SG_ 1318 DIF_a244_flybackFault "Front drive inverter: a244 flyback fault";
CM_ SG_ 1318 DIF_a244_postShortTestFailed "Front drive inverter: a244 post short test failed";
CM_ SG_ 1318 DIF_a244_udsSelfTest "Front drive inverter: a244 uds self test";
CM_ SG_ 1318 DIF_a244_irSensorV "Front drive inverter: a244 ir sensor v";
CM_ SG_ 1318 DIF_a244_gateDriveICUndervoltage "Front drive inverter: a244 gate drive IC undervoltage";
CM_ SG_ 1318 DIF_a244_plausibleSingleSwitchSh "Front drive inverter: a244 plausible single switch short only";
CM_ SG_ 1318 DIF_a244_delay "Front drive inverter: a244 delay";
CM_ SG_ 1318 DIF_a246_atSpeedDIResetCount "Front drive inverter: a246 at speed DI reset count";
CM_ SG_ 1318 DIF_a246_didPMCauseSwitchOf_0001 "Front drive inverter: a246 did PM cause switch off path nominal";
CM_ SG_ 1318 DIF_a246_didPMCauseSwitchOffPath "Front drive inverter: a246 did PM cause switch off path low speed";
CM_ SG_ 1318 DIF_a246_currentSensorRational "Front drive inverter: a246 current sensor rational";
CM_ SG_ 1318 DIF_a246_observerDetectedSw_0001 "Front drive inverter: a246 observer detected switch off path nominal";
CM_ SG_ 1318 DIF_a246_observerDetectedSwitchO "Front drive inverter: a246 observer detected switch off path low speed";
CM_ SG_ 1318 DIF_a246_hvIsGood "Front drive inverter: a246 hv is good";
CM_ SG_ 1318 DIF_a246_lvIsGood "Front drive inverter: a246 lv is good";
CM_ SG_ 1318 DIF_a246_codeBranch "Front drive inverter: a246 code branch";
CM_ SG_ 1318 DIF_a246_motorRPM "Front drive inverter: a246 motor RPM";
CM_ SG_ 1318 DIF_a246_eepromOffsetIa "Front drive inverter: a246 eeprom offset ia";
CM_ SG_ 1318 DIF_a246_eepromOffsetIb "Front drive inverter: a246 eeprom offset ib";
CM_ SG_ 1318 DIF_a246_soptPreviouslyPassed "Front drive inverter: a246 sopt previously passed";
CM_ SG_ 1318 DIF_a246_lowSpeedRecoveryEnabled "Front drive inverter: a246 low speed recovery enabled";
CM_ SG_ 1318 DIF_a247_rotorOffsetEst "Front drive inverter: a247 rotor offset est";
CM_ SG_ 1318 DIF_a247_motorRPM "Front drive inverter: a247 motor RPM";
CM_ SG_ 1318 DIF_a247_torqueMotor "Front drive inverter: a247 torque motor";
CM_ SG_ 1318 DIF_a251_oilFlow "Front drive inverter: a251 oil flow; raw 255 = signal not available (SNA)";
CM_ SG_ 1318 DIF_a251_oilTemperature "Front drive inverter: a251 oil temperature; raw 255 = signal not available (SNA)";
CM_ SG_ 1318 DIF_a251_dcVoltage "Front drive inverter: a251 dc voltage; raw 255 = signal not available (SNA)";
CM_ SG_ 1318 DIF_a251_dcCurrent "Front drive inverter: a251 dc current; raw 255 = signal not available (SNA)";
CM_ SG_ 1318 DIF_a251_phaseCurrent "Front drive inverter: a251 phase current; raw 255 = signal not available (SNA)";
CM_ SG_ 1318 DIF_a251_leadAngle "Front drive inverter: a251 lead angle";
CM_ SG_ 1318 DIF_a251_reason "Front drive inverter: a251 reason";
CM_ SG_ 1318 DIF_a253_voltage "Front drive inverter: a253 voltage";
CM_ SG_ 1318 DIF_a253_reason "Front drive inverter: a253 reason";
CM_ BO_ 854 "Front drive inverter message: alert matrix";
CM_ SG_ 854 DIF_matrixIndex "Front drive inverter: matrix index";
CM_ SG_ 854 DIF_a001_hwPhaseAgateDrive "Front drive inverter: a001 hw phase agate drive";
CM_ SG_ 854 DIF_a002_hwPhaseBgateDrive "Front drive inverter: a002 hw phase bgate drive";
CM_ SG_ 854 DIF_a003_hwPhaseCgateDrive "Front drive inverter: a003 hw phase cgate drive";
CM_ SG_ 854 DIF_a004_hwPhaseApeak "Front drive inverter: a004 hw phase apeak";
CM_ SG_ 854 DIF_a005_hwPhaseBpeak "Front drive inverter: a005 hw phase bpeak";
CM_ SG_ 854 DIF_a006_hwPhaseCpeak "Front drive inverter: a006 hw phase cpeak";
CM_ SG_ 854 DIF_a007_statorAnomalyDetected "Front drive inverter: a007 stator anomaly detected";
CM_ SG_ 854 DIF_a008_hwEncoderA "Front drive inverter: a008 hw encoder a";
CM_ SG_ 854 DIF_a009_hwEncoderB "Front drive inverter: a009 hw encoder b";
CM_ SG_ 854 DIF_a010_unintendedReset "Front drive inverter: a010 unintended reset";
CM_ SG_ 854 DIF_a011_swPowerStageNotReady "Front drive inverter: a011 sw power stage not ready";
CM_ SG_ 854 DIF_a012_hvilNotClosed "Front drive inverter: a012 hvil not closed";
CM_ SG_ 854 DIF_a013_eccError "Front drive inverter: a013 ecc error";
CM_ SG_ 854 DIF_a014_activeDamping "Front drive inverter: a014 active damping";
CM_ SG_ 854 DIF_a015_mechSafeStateAnomaly "Front drive inverter: a015 mech safe state anomaly";
CM_ SG_ 854 DIF_a016_safeStateApplied "Front drive inverter: a016 safe state applied";
CM_ SG_ 854 DIF_a017_hwPedalMonitor "Front drive inverter: a017 hw pedal monitor";
CM_ SG_ 854 DIF_a018_hwLVSupplyUV "Front drive inverter: a018 hw LV supply UV";
CM_ SG_ 854 DIF_a020_hwMotorEncoder "Front drive inverter: a020 hw motor encoder";
CM_ SG_ 854 DIF_a021_hwBusOV "Front drive inverter: a021 hw bus OV";
CM_ SG_ 854 DIF_a022_hw5vSupplyUV "Front drive inverter: a022 hw5v supply UV";
CM_ SG_ 854 DIF_a024_selfTest "Front drive inverter: a024 self test";
CM_ SG_ 854 DIF_a025_phaseApeak "Front drive inverter: a025 phase apeak";
CM_ SG_ 854 DIF_a026_phaseBpeak "Front drive inverter: a026 phase bpeak";
CM_ SG_ 854 DIF_a027_phaseCpeak "Front drive inverter: a027 phase cpeak";
CM_ SG_ 854 DIF_a028_phaseArms "Front drive inverter: a028 phase arms";
CM_ SG_ 854 DIF_a029_phaseBrms "Front drive inverter: a029 phase brms";
CM_ SG_ 854 DIF_a030_phaseCrms "Front drive inverter: a030 phase crms";
CM_ SG_ 854 DIF_a031_phaseAcurrentOffset "Front drive inverter: a031 phase acurrent offset";
CM_ SG_ 854 DIF_a032_phaseBcurrentOffset "Front drive inverter: a032 phase bcurrent offset";
CM_ SG_ 854 DIF_a033_phaseAcurrentSensor "Front drive inverter: a033 phase acurrent sensor";
CM_ SG_ 854 DIF_a034_phaseBcurrentSensor "Front drive inverter: a034 phase bcurrent sensor";
CM_ SG_ 854 DIF_a035_phaseCurrentBalance "Front drive inverter: a035 phase current balance";
CM_ SG_ 854 DIF_a036_busOV "Front drive inverter: a036 bus OV";
CM_ SG_ 854 DIF_a037_busUV "Front drive inverter: a037 bus UV";
CM_ SG_ 854 DIF_a038_busVsensor "Front drive inverter: a038 bus vsensor";
CM_ SG_ 854 DIF_a039_exceptionUndefinedInstr "Front drive inverter: a039 exception undefined instruction";
CM_ SG_ 854 DIF_a040_difMIA "Front drive inverter: a040 dif MIA";
CM_ SG_ 854 DIF_a041_sdcMIA "Front drive inverter: a041 sdc MIA";
CM_ SG_ 854 DIF_a042_inletSensor "Front drive inverter: a042 inlet sensor";
CM_ SG_ 854 DIF_a043_outletOT "Front drive inverter: a043 outlet OT";
CM_ SG_ 854 DIF_a044_outletUT "Front drive inverter: a044 outlet UT";
CM_ SG_ 854 DIF_a045_outletSensor "Front drive inverter: a045 outlet sensor";
CM_ SG_ 854 DIF_a046_statorOT "Front drive inverter: a046 stator OT";
CM_ SG_ 854 DIF_a047_statorSensor1 "Front drive inverter: a047 stator sensor1";
CM_ SG_ 854 DIF_a048_statorSensor2 "Front drive inverter: a048 stator sensor2";
CM_ SG_ 854 DIF_a049_statorSensorDiff "Front drive inverter: a049 stator sensor diff";
CM_ SG_ 854 DIF_a050_noStatorSensor "Front drive inverter: a050 no stator sensor";
CM_ SG_ 854 DIF_a052_dirMIA "Front drive inverter: a052 dir MIA";
CM_ SG_ 854 DIF_a053_unexpectedLatchState "Front drive inverter: a053 unexpected latch state";
CM_ SG_ 854 DIF_a054_driveInverterOT "Front drive inverter: a054 drive inverter OT";
CM_ SG_ 854 DIF_a055_trqCrossCheck "Front drive inverter: a055 trq cross check";
CM_ SG_ 854 DIF_a056_ambientOT "Front drive inverter: a056 ambient OT";
CM_ SG_ 854 DIF_a057_ambientUT "Front drive inverter: a057 ambient UT";
CM_ SG_ 854 DIF_a058_ambientSensor "Front drive inverter: a058 ambient sensor";
CM_ SG_ 854 DIF_a059_heatsinkOT "Front drive inverter: a059 heatsink OT";
CM_ SG_ 854 DIF_a060_heatsinkUT "Front drive inverter: a060 heatsink UT";
CM_ SG_ 854 DIF_a061_heatsinkSensor "Front drive inverter: a061 heatsink sensor";
CM_ SG_ 854 DIF_a062_systemLimpMode "Front drive inverter: a062 system limp mode";
CM_ SG_ 854 DIF_a063_bbMIA "Front drive inverter: a063 bb MIA";
CM_ SG_ 854 DIF_a064_torqueIntervention "Front drive inverter: a064 torque intervention";
CM_ SG_ 854 DIF_a065_canHardwareBusB "Front drive inverter: a065 can hardware bus b";
CM_ SG_ 854 DIF_a066_canDataBusB "Front drive inverter: a066 can data bus b";
CM_ SG_ 854 DIF_a067_canOverrunBusB "Front drive inverter: a067 can overrun bus b";
CM_ SG_ 854 DIF_a069_rotorTempLimit "Front drive inverter: a069 rotor temp limit";
CM_ SG_ 854 DIF_a070_udsTransactionInitiated "Front drive inverter: a070 uds transaction initiated";
CM_ SG_ 854 DIF_a071_busDisconnected "Front drive inverter: a071 bus disconnected";
CM_ SG_ 854 DIF_a072_gateDriveFaultCounter "Front drive inverter: a072 gate drive fault counter";
CM_ SG_ 854 DIF_a073_motorSpeed "Front drive inverter: a073 motor speed";
CM_ SG_ 854 DIF_a074_motorEncoder "Front drive inverter: a074 motor encoder";
CM_ SG_ 854 DIF_a075_motorSpeedMismatch "Front drive inverter: a075 motor speed mismatch";
CM_ SG_ 854 DIF_a076_lvSupplyOV "Front drive inverter: a076 lv supply OV";
CM_ SG_ 854 DIF_a077_lvSupplyUV "Front drive inverter: a077 lv supply UV";
CM_ SG_ 854 DIF_a078_adcRefLow "Front drive inverter: a078 adc ref low";
CM_ SG_ 854 DIF_a079_adcRefHigh "Front drive inverter: a079 adc ref high";
CM_ SG_ 854 DIF_a084_eccTestData0 "Front drive inverter: a084 ecc test data0";
CM_ SG_ 854 DIF_d085_driveInverterBoardFailu "Front drive inverter: d085 drive inverter board failure";
CM_ SG_ 854 DIF_a086_activeDischargeOn "Front drive inverter: a086 active discharge on";
CM_ SG_ 854 DIF_a087_gtwMIA "Front drive inverter: a087 gtw MIA";
CM_ SG_ 854 DIF_a088_uiMIA "Front drive inverter: a088 ui MIA";
CM_ SG_ 854 DIF_d089_invalidTorqueCommand "Front drive inverter: d089 invalid torque command";
CM_ SG_ 854 DIF_a090_pmMIA "Front drive inverter: a090 pm MIA";
CM_ SG_ 854 DIF_a091_espMIA "Front drive inverter: a091 esp MIA";
CM_ SG_ 854 DIF_a092_bmsMIA "Front drive inverter: a092 bms MIA";
CM_ SG_ 854 DIF_a093_canHardwareBusA "Front drive inverter: a093 can hardware bus a";
CM_ SG_ 854 DIF_a094_canDataBusA "Front drive inverter: a094 can data bus a";
CM_ SG_ 854 DIF_a095_canOverrunBusA "Front drive inverter: a095 can overrun bus a";
CM_ SG_ 854 DIF_a096_memoryError "Front drive inverter: a096 memory error";
CM_ SG_ 854 DIF_a097_eepromError "Front drive inverter: a097 eeprom error";
CM_ SG_ 854 DIF_a098_intTimeTooLong "Front drive inverter: a098 int time too long";
CM_ SG_ 854 DIF_a099_threadOverrun "Front drive inverter: a099 thread overrun";
CM_ SG_ 854 DIF_a100_assertion "Front drive inverter: a100 assertion";
CM_ SG_ 854 DIF_a101_eccTestData1 "Front drive inverter: a101 ecc test data1";
CM_ SG_ 854 DIF_a102_exceptionPrefetchAbort "Front drive inverter: a102 exception prefetch abort";
CM_ SG_ 854 DIF_a103_lowFlow "Front drive inverter: a103 low flow";
CM_ SG_ 854 DIF_d104_resetUnintended "Front drive inverter: d104 reset unintended";
CM_ SG_ 854 DIF_d105_busVoltageSensorIssue "Front drive inverter: d105 bus voltage sensor issue";
CM_ SG_ 854 DIF_a106_idleTaskStarving "Front drive inverter: a106 idle task starving";
CM_ SG_ 854 DIF_a107_fpgaError "Front drive inverter: a107 fpga error";
CM_ SG_ 854 DIF_a108_stateTrans "Front drive inverter: a108 state trans";
CM_ SG_ 854 DIF_a109_ahbWriteError "Front drive inverter: a109 ahb write error";
CM_ SG_ 854 DIF_a110_brakeMIA "Front drive inverter: a110 brake MIA";
CM_ SG_ 854 DIF_a111_badPhaseSensorCalib "Front drive inverter: a111 bad phase sensor calib";
CM_ SG_ 854 DIF_a112_noPhaseCurrent "Front drive inverter: a112 no phase current";
CM_ SG_ 854 DIF_a113_noFuncHeatsinkSensor "Front drive inverter: a113 no func heatsink sensor";
CM_ SG_ 854 DIF_a114_exceptionDataAbort "Front drive inverter: a114 exception data abort";
CM_ SG_ 854 DIF_a115_exceptionDataAbort2 "Front drive inverter: a115 exception data abort2";
CM_ SG_ 854 DIF_a116_highSpeedWearCounter "Front drive inverter: a116 high speed wear counter";
CM_ SG_ 854 DIF_a117_diMIA "Front drive inverter: a117 di MIA";
CM_ SG_ 854 DIF_d118_oilPumpCommsLost "Front drive inverter: d118 oil pump comms lost";
CM_ SG_ 854 DIF_a119_hvpMIA "Front drive inverter: a119 hvp MIA";
CM_ SG_ 854 DIF_a120_hvlinkMIA "Front drive inverter: a120 hvlink MIA";
CM_ SG_ 854 DIF_a121_motorControlRegulation "Front drive inverter: a121 motor control regulation";
CM_ SG_ 854 DIF_a122_highStackUsage "Front drive inverter: a122 high stack usage";
CM_ SG_ 854 DIF_a123_lossMotorControl "Front drive inverter: a123 loss motor control";
CM_ SG_ 854 DIF_d124_oilPumpServiceRequired "Front drive inverter: d124 oil pump service required";
CM_ SG_ 854 DIF_d125_currentSensorIssue "Front drive inverter: d125 current sensor issue";
CM_ SG_ 854 DIF_a126_limpMode "Front drive inverter: a126 limp mode";
CM_ SG_ 854 DIF_a127_gracefulPowerOff "Front drive inverter: a127 graceful power off";
CM_ SG_ 854 DIF_a128_fpgaVersionMismatch "Front drive inverter: a128 fpga version mismatch";
CM_ SG_ 854 DIF_d129_oilPumpIssue "Front drive inverter: d129 oil pump issue";
CM_ SG_ 854 DIF_d130_positionSensorIssue "Front drive inverter: d130 position sensor issue";
CM_ SG_ 854 DIF_d131_currentSensorOffset "Front drive inverter: d131 current sensor offset";
CM_ SG_ 854 DIF_d132_busUVIssue "Front drive inverter: d132 bus UV issue";
CM_ SG_ 854 DIF_a133_capacitorOT "Front drive inverter: a133 capacitor OT";
CM_ SG_ 854 DIF_a134_wheelSpeedIrrational "Front drive inverter: a134 wheel speed irrational";
CM_ SG_ 854 DIF_d135_rotatedStator "Front drive inverter: d135 rotated stator";
CM_ SG_ 854 DIF_a136_spiError "Front drive inverter: a136 spi error";
CM_ SG_ 854 DIF_d137_currentSensorOutOfRange "Front drive inverter: d137 current sensor out of range";
CM_ SG_ 854 DIF_d138_inverterLVPowerSupplyLo "Front drive inverter: d138 inverter LV power supply low";
CM_ SG_ 854 DIF_d141_coolingSystemIssue "Front drive inverter: d141 cooling system issue";
CM_ SG_ 854 DIF_a142_highLashAngle "Front drive inverter: a142 high lash angle";
CM_ SG_ 854 DIF_d143_wheelSpeedCorrelationIs "Front drive inverter: d143 wheel speed correlation issue";
CM_ SG_ 854 DIF_a144_configMismatch "Front drive inverter: a144 config mismatch";
CM_ SG_ 854 DIF_a147_highTorqueWearLimit "Front drive inverter: a147 high torque wear limit";
CM_ SG_ 854 DIF_a148_burnInCycleEnded "Front drive inverter: a148 burn in cycle ended";
CM_ SG_ 854 DIF_a149_oilPumpFailure "Front drive inverter: a149 oil pump failure";
CM_ SG_ 854 DIF_a150_busVD "Front drive inverter: a150 bus VD";
CM_ SG_ 854 DIF_a151_shockTorqueLimiter "Front drive inverter: a151 shock torque limiter";
CM_ SG_ 854 DIF_a152_linError "Front drive inverter: a152 lin error";
CM_ SG_ 854 DIF_a153_oilPumpDiagnostics "Front drive inverter: a153 oil pump diagnostics";
CM_ SG_ 854 DIF_a154_resolver "Front drive inverter: a154 resolver";
CM_ SG_ 854 DIF_a155_vcfrontMIA "Front drive inverter: a155 vcfront MIA";
CM_ SG_ 854 DIF_a156_currentObserver "Front drive inverter: a156 current observer";
CM_ SG_ 854 DIF_a157_rcmMIA "Front drive inverter: a157 rcm MIA";
CM_ SG_ 854 DIF_a158_ibstMIA "Front drive inverter: a158 ibst MIA";
CM_ SG_ 854 DIF_a160_busVoltageAnomaly "Front drive inverter: a160 bus voltage anomaly";
CM_ SG_ 854 DIF_a161_epas3pMIA "Front drive inverter: a161 epas3p MIA";
CM_ SG_ 854 DIF_a162_endOfLifetimeBurnIn "Front drive inverter: a162 end of lifetime burn in";
CM_ SG_ 854 DIF_d163_recoverableOvercurrent "Front drive inverter: d163 recoverable overcurrent";
CM_ SG_ 854 DIF_d164_firmwareConfigMismatch "Front drive inverter: d164 firmware config mismatch";
CM_ SG_ 854 DIF_d165_statorOverTemperature "Front drive inverter: d165 stator over temperature";
CM_ SG_ 854 DIF_d166_rotorOverTemperature "Front drive inverter: d166 rotor over temperature";
CM_ SG_ 854 DIF_d167_tempSensorIssue "Front drive inverter: d167 temp sensor issue";
CM_ SG_ 854 DIF_d168_clutchPerformance "Front drive inverter: d168 clutch performance";
CM_ SG_ 854 DIF_d169_clutchPosition "Front drive inverter: d169 clutch position";
CM_ SG_ 854 DIF_d170_clutchFailure "Front drive inverter: d170 clutch failure";
CM_ SG_ 854 DIF_a172_statorOilTempOT "Front drive inverter: a172 stator oil temp OT";
CM_ SG_ 854 DIF_a173_ascFdbkDiagnostic "Front drive inverter: a173 asc fdbk diagnostic";
CM_ SG_ 854 DIF_a174_unitMayNotRestart "Front drive inverter: a174 unit may not restart";
CM_ SG_ 854 DIF_a176_safetyICFault "Front drive inverter: a176 safety IC fault";
CM_ SG_ 854 DIF_a177_fluxReferenceCorrected "Front drive inverter: a177 flux reference corrected";
CM_ SG_ 854 DIF_a202_excessHeatUnavailable "Front drive inverter: a202 excess heat unavailable";
CM_ SG_ 854 DIF_a225_tmpEstPlausibility "Front drive inverter: a225 tmp est plausibility";
CM_ SG_ 854 DIF_a229_busVsensorOverCAN "Front drive inverter: a229 bus vsensor over CAN";
CM_ SG_ 854 DIF_a233_diMsgMissed "Front drive inverter: a233 di msg missed";
CM_ SG_ 854 DIF_a234_pcsMIA "Front drive inverter: a234 pcs MIA";
CM_ SG_ 854 DIF_a236_tasMIA "Front drive inverter: a236 tas MIA";
CM_ SG_ 854 DIF_a240_clearFusesRoutine "Front drive inverter: a240 clear fuses routine";
CM_ SG_ 854 DIF_a241_systemThermallyLimited "Front drive inverter: a241 system thermally limited";
CM_ SG_ 854 DIF_a242_spinDownLearning "Front drive inverter: a242 spin down learning";
CM_ SG_ 854 DIF_a243_ecuLogAvailable "Front drive inverter: a243 ecu log available";
CM_ SG_ 854 DIF_a244_mechSafeStateApplied "Front drive inverter: a244 mech safe state applied";
CM_ SG_ 854 DIF_a245_mechSafeStatePreWarn "Front drive inverter: a245 mech safe state pre warn";
CM_ SG_ 854 DIF_a246_recoveryAtSpeedError "Front drive inverter: a246 recovery at speed error";
CM_ SG_ 854 DIF_a247_rotorOffsetError "Front drive inverter: a247 rotor offset error";
CM_ SG_ 854 DIF_a249_highStatorTempFromResis "Front drive inverter: a249 high stator temp from resist";
CM_ SG_ 854 DIF_a250_preregulatorRail "Front drive inverter: a250 preregulator rail";
CM_ SG_ 854 DIF_a251_oilPumpService "Front drive inverter: a251 oil pump service";
CM_ SG_ 854 DIF_a252_currentCoreFallback "Front drive inverter: a252 current core fallback";
CM_ SG_ 854 DIF_a253_lvBoostedRail "Front drive inverter: a253 lv boosted rail";
CM_ SG_ 854 DIF_a254_activeDischargeRail "Front drive inverter: a254 active discharge rail";
CM_ SG_ 854 DIF_a255_currentGainFallback "Front drive inverter: a255 current gain fallback";
CM_ BO_ 1879 "Front drive inverter message: debug";
CM_ SG_ 1879 DIF_debugSelector "Front drive inverter: debug selector";
CM_ SG_ 1879 DIF_motorIA "Position from firmware; message assignment inferred.";
CM_ SG_ 1879 DIF_motorIB "Position from firmware; message assignment inferred.";
CM_ SG_ 1879 DIF_motorIC "Position from firmware; message assignment inferred.";
CM_ SG_ 1879 DIF_statorIDref "Position from firmware; message assignment inferred.";
CM_ SG_ 1879 DIF_statorIDfdb "Position from firmware; message assignment inferred.";
CM_ SG_ 1879 DIF_torquePerAmp "Position from firmware; message assignment inferred.";
CM_ SG_ 1879 DIF_rsScale "Position from firmware; message assignment inferred.";
CM_ SG_ 1879 DIF_statorIQref "Position from firmware; message assignment inferred.";
CM_ SG_ 1879 DIF_statorIQfdb "Position from firmware; message assignment inferred.";
CM_ SG_ 1879 DIF_motorV "Position from firmware; message assignment inferred.";
CM_ SG_ 1879 DIF_tqScaleDifferential "Position from firmware; message assignment inferred.";
CM_ SG_ 1879 DIF_statorFluxRef "Position from firmware; message assignment inferred.";
CM_ SG_ 1879 DIF_statorFluxFdb "Position from firmware; message assignment inferred.";
CM_ SG_ 1879 DIF_lmScale "Position from firmware; message assignment inferred.";
CM_ SG_ 1879 DIF_statorVQ "Position from firmware; message assignment inferred.";
CM_ SG_ 1879 DIF_statorVD "Position from firmware; message assignment inferred.";
CM_ SG_ 1879 DIF_peakFlux "Position from firmware; message assignment inferred.";
CM_ SG_ 1879 DIF_gainScale "Position from firmware; message assignment inferred.";
CM_ SG_ 1879 DIF_usmState "Position from firmware; message assignment inferred.";
CM_ SG_ 1879 DIF_peakIQref "Position from firmware; message assignment inferred.";
CM_ SG_ 1879 DIF_motorIAavg "Position from firmware; message assignment inferred.";
CM_ SG_ 1879 DIF_motorIBavg "Position from firmware; message assignment inferred.";
CM_ SG_ 1879 DIF_tqSatThermal "Position from firmware; message assignment inferred.";
CM_ SG_ 1879 DIF_tqSatMotorVoltage "Position from firmware; message assignment inferred.";
CM_ SG_ 1879 DIF_tqSatMotorCurrent "Position from firmware; message assignment inferred.";
CM_ SG_ 1879 DIF_tcMaxRequest "Position from firmware; message assignment inferred.";
CM_ SG_ 1879 DIF_tcMinRequest "Position from firmware; message assignment inferred.";
CM_ SG_ 1879 DIF_tqScaleMaxMotorSpeed "Position from firmware; message assignment inferred.";
CM_ SG_ 1879 DIF_wasteCurrentLimit "Position from firmware; message assignment inferred.";
CM_ SG_ 1879 DIF_llsScale "Position from firmware; message assignment inferred.";
CM_ SG_ 1879 DIF_llrScale "Position from firmware; message assignment inferred.";
CM_ SG_ 1879 DIF_oilPumpMotorSpeed "Position from firmware; message assignment inferred.";
CM_ SG_ 1879 DIF_rotorFlux "Position from firmware; message assignment inferred.";
CM_ SG_ 1879 DIF_dcCableHeat "Position from firmware; message assignment inferred.";
CM_ SG_ 1879 DIF_magnetTempEst "Position from firmware; message assignment inferred.";
CM_ SG_ 1879 DIF_resolverReady "Position from firmware; message assignment inferred.";
CM_ SG_ 1879 DIF_resolverNoCarrier "Position from firmware; message assignment inferred.";
CM_ SG_ 1879 DIF_resolverNoPhaseLock "Position from firmware; message assignment inferred.";
CM_ SG_ 1879 DIF_resolverClaMIA "Position from firmware; message assignment inferred.";
CM_ SG_ 1879 DIF_soptMaxCurrentMagSqrd "Position from firmware; message assignment inferred.";
CM_ SG_ 1879 DIF_statorVDFiltered "Position from firmware; message assignment inferred.";
CM_ SG_ 1879 DIF_statorVQFiltered "Position from firmware; message assignment inferred.";
CM_ SG_ 1879 DIF_pwmState "Position from firmware; message assignment inferred.";
CM_ SG_ 1879 DIF_dcCapTemp "Position from firmware; message assignment inferred.";
CM_ SG_ 1879 DIF_busbarTemp "Position from firmware; message assignment inferred.";
CM_ SG_ 1879 DIF_pcsTemp "Position from firmware; message assignment inferred.";
CM_ SG_ 1879 DIF_statorTemp1 "Position from firmware; message assignment inferred.";
CM_ SG_ 1879 DIF_statorTemp2 "Position from firmware; message assignment inferred.";
CM_ SG_ 1879 DIF_cpu10HzMin "Position from firmware; message assignment inferred.";
CM_ SG_ 1879 DIF_cpu10HzAvg "Position from firmware; message assignment inferred.";
CM_ SG_ 1879 DIF_cpu100HzMin "Position from firmware; message assignment inferred.";
CM_ SG_ 1879 DIF_cpu100HzAvg "Position from firmware; message assignment inferred.";
CM_ SG_ 1879 DIF_cpu10msMin "Position from firmware; message assignment inferred.";
CM_ SG_ 1879 DIF_cpu1kHzMin "Position from firmware; message assignment inferred.";
CM_ SG_ 1879 DIF_cpu1kHzAvg "Position from firmware; message assignment inferred.";
CM_ SG_ 1879 DIF_cpu20kHzMin "Position from firmware; message assignment inferred.";
CM_ SG_ 1879 DIF_cpu20kHzAvg "Position from firmware; message assignment inferred.";
CM_ SG_ 1879 DIF_hwFaultCount "Position from firmware; message assignment inferred.";
CM_ SG_ 1879 DIF_driveUnitOdometer "Position from firmware; message assignment inferred.";
CM_ SG_ 1879 DIF_phaseOutBusbarTemp "Front drive inverter: phase out busbar temp; raw 0 = signal not available (SNA)";
CM_ SG_ 1879 DIF_phaseOutBusbarWeldTemp "Front drive inverter: phase out busbar weld temp; raw 0 = signal not available (SNA)";
CM_ SG_ 1879 DIF_phaseOutLugTemp "Front drive inverter: phase out lug temp; raw 0 = signal not available (SNA)";
CM_ SG_ 1879 DIF_dcLinkCapTemp "Front drive inverter: dc link cap temp; raw 0 = signal not available (SNA)";
CM_ SG_ 1879 DIF_hvDcCableTemp "Front drive inverter: hv dc cable temp; raw 0 = signal not available (SNA)";
CM_ SG_ 1879 DIF_negDcBusbarTemp "Front drive inverter: neg dc busbar temp; raw 0 = signal not available (SNA)";
CM_ SG_ 1879 DIF_posDcBusbarTemp "Front drive inverter: pos dc busbar temp; raw 0 = signal not available (SNA)";
CM_ SG_ 1879 DIF_statorEndWindingTemp "Front drive inverter: stator end winding temp; raw 0 = signal not available (SNA)";
CM_ SG_ 1879 DIF_rotorMaxMagnetTemp "Reports the maximum temperature of the rotor magnet; raw 0 = signal not available (SNA)";
CM_ SG_ 1879 DIF_lightSenseV "Front drive inverter: light sense v";
CM_ SG_ 1879 DIF_pyroSenseV "Front drive inverter: pyro sense v";
CM_ SG_ 1879 DIF_statorSlotWindingTemp "Front drive inverter: stator slot winding temp; raw 0 = signal not available (SNA)";
CM_ SG_ 1879 DIF_intervalMaxHvBusV "Front drive inverter: interval max hv bus v";
CM_ SG_ 1879 DIF_cpu1HzMin "Position from firmware; message assignment inferred.";
CM_ SG_ 1879 DIF_cpu1HzAvg "Position from firmware; message assignment inferred.";
CM_ SG_ 1879 DIF_cpuIDWord0 "Position from firmware; message assignment inferred.";
CM_ SG_ 1879 DIF_cpuIDWord1 "Position from firmware; message assignment inferred.";
CM_ SG_ 1879 DIF_cpuIDWord2 "Position from firmware; message assignment inferred.";
CM_ SG_ 1879 DIF_cpuIDWord3 "Position from firmware; message assignment inferred.";
CM_ BO_ 634 "Front drive inverter message: hv status";
CM_ SG_ 634 DIF_hvStatusChecksum "Front drive inverter: hv status checksum";
CM_ SG_ 634 DIF_hvStatusCounter "Front drive inverter: hv status counter";
CM_ SG_ 634 DIF_hvilCurrent "HVIL Current";
CM_ SG_ 634 DIF_hvilCmVoltage "HVIL Common Mode Voltage";
CM_ SG_ 634 DIF_hvilStatus "Aggregated hardware and measured HVIL unit status; raw 3 = signal not available (SNA)";
CM_ SG_ 634 DIF_hvilSupplyState "Front drive inverter: hvil supply state";
CM_ SG_ 634 DIF_activeDischargeCtrl "Front drive inverter: active discharge ctrl";
CM_ SG_ 634 DIF_activeDischargeStatus "Active discharge status from HVIL_FAULT signal.";
CM_ SG_ 634 DIF_vBat "Reports the battery voltage measured by the Drive Inverter's local Analog to Digital Converter (ADC).";
CM_ SG_ 634 DIF_vBatQF "Front drive inverter: v bat QF";
CM_ SG_ 634 DIF_powerStageSafeState "Front drive inverter: power stage safe state";
CM_ SG_ 634 DIF_fluxState "Front drive inverter: flux state";
CM_ SG_ 634 DIF_vBusDiag "Front drive inverter: v bus diag";
CM_ SG_ 634 DIF_gateDriveState "Front drive inverter: gate drive state";
CM_ SG_ 634 DIF_gateDriveSupplyState "Front drive inverter: gate drive supply state";
CM_ BO_ 1622 "Front drive inverter message: info";
CM_ SG_ 1622 DIF_infoIndex "Front drive inverter: info index";
CM_ SG_ 1622 DIF_buildType "Front drive inverter: build type";
CM_ SG_ 1622 DIF_buildConfigurationId "Front drive inverter: build configuration id";
CM_ SG_ 1622 DIF_hardwareId "Front drive inverter: hardware id";
CM_ SG_ 1622 DIF_componentId "Front drive inverter: component id";
CM_ SG_ 1622 DIF_pcbaId "Front drive inverter: pcba id";
CM_ SG_ 1622 DIF_assemblyId "Front drive inverter: assembly id";
CM_ SG_ 1622 DIF_usageId "Front drive inverter: usage id";
CM_ SG_ 1622 DIF_subUsageId "Front drive inverter: sub usage id";
CM_ SG_ 1622 DIF_motorType "Front drive inverter: motor type; raw 0 = signal not available (SNA)";
CM_ SG_ 1622 DIF_siliconType "Front drive inverter: silicon type";
CM_ SG_ 1622 DIF_mechSafeStateType "Front drive inverter: mech safe state type; raw 0 = signal not available (SNA)";
CM_ SG_ 1622 DIF_applicationCrc "Front drive inverter: application crc";
CM_ SG_ 1622 DIF_oilPumpBuildType "Front drive inverter: oil pump build type";
CM_ SG_ 1622 DIF_oilPumpAppCrc "Front drive inverter: oil pump app crc";
CM_ SG_ 1622 DIF_FPGA_version "Front drive inverter: FPGA version; raw 255 = signal not available (SNA)";
CM_ SG_ 1622 DIF_appGitHash "Front drive inverter: app git hash";
CM_ SG_ 1622 DIF_bootGitHash "Front drive inverter: boot git hash";
CM_ SG_ 1622 DIF_platformTyp "Front drive inverter: platform typ";
CM_ SG_ 1622 DIF_infoBootLdUdsProtocolVersion "Front drive inverter: info boot ld uds protocol version";
CM_ SG_ 1622 DIF_bootloaderCrc "Front drive inverter: bootloader crc";
CM_ SG_ 1622 DIF_subcomponentGitHash "Position from firmware; message assignment inferred.";
CM_ SG_ 1622 DIF_oilPumpPcbaId "Front drive inverter: oil pump pcba id";
CM_ SG_ 1622 DIF_oilPumpAssemblyId "Front drive inverter: oil pump assembly id";
CM_ SG_ 1622 DIF_oilPumpUsageId "Front drive inverter: oil pump usage id";
CM_ SG_ 1622 DIF_refRotorFlux "Front drive inverter: ref rotor flux";
CM_ SG_ 1622 DIF_refRotorOffset "Front drive inverter: ref rotor offset; raw 2048 = signal not available (SNA)";
CM_ SG_ 1622 DIF_speedWearTotal "Front drive inverter: speed wear total; raw 255 = signal not available (SNA)";
CM_ SG_ 1622 DIF_torqueWearTotal "Front drive inverter: torque wear total; raw 255 = signal not available (SNA)";
CM_ BO_ 421 "Front drive inverter message: motor status";
CM_ SG_ 421 DIF_motorCurrent "Drive Inverer measured motor RMS phase current.";
CM_ SG_ 421 DIF_switchingFrequency "Front drive inverter: switching frequency";
CM_ SG_ 421 DIF_targetFluxMode "Front drive inverter: target flux mode";
CM_ SG_ 421 DIF_switchShortTestRetryCount "Front drive inverter: switch short test retry count";
CM_ SG_ 421 DIF_keepAliveRequest "Used to detect that the Drive Inverter (DI) expects 12V and High Voltage (HV) to be kept up in order to protect hardware.";
CM_ SG_ 421 DIF_motorStatusCounter "Front drive inverter: motor status counter";
CM_ SG_ 421 DIF_motorStatusChecksum "Front drive inverter: motor status checksum";
CM_ BO_ 918 "Front drive inverter message: oil pump";
CM_ SG_ 918 DIF_oilPumpState "Reports the state of the oil pump; raw 7 = signal not available (SNA)";
CM_ SG_ 918 DIF_oilPumpFluidTQF "Front drive inverter: oil pump fluid TQF";
CM_ SG_ 918 DIF_oilPumpLeadAngle "Front drive inverter: oil pump lead angle";
CM_ SG_ 918 DIF_oilPumpFlowTarget "Detects oil pump flow target; raw 255 = signal not available (SNA)";
CM_ SG_ 918 DIF_oilPumpFlowActual "Detects oil pump flow; raw 255 = signal not available (SNA)";
CM_ SG_ 918 DIF_oilPumpFluidT "Detects oil pump fluid tester; raw 255 = signal not available (SNA)";
CM_ SG_ 918 DIF_oilPumpPhaseCurrent "Front drive inverter: oil pump phase current; raw 255 = signal not available (SNA)";
CM_ SG_ 918 DIF_oilPumpPressureEstimate "Oil pump pressure estimate; raw 255 = signal not available (SNA)";
CM_ SG_ 918 DIF_oilPumpPressureExpected "Oil pump pressure expected; raw 255 = signal not available (SNA)";
CM_ SG_ 918 DIF_oilPumpPressureResidual "Oil pressure error outside of allowed tolerance; raw 255 = signal not available (SNA)";
CM_ BO_ 741 "Front drive inverter message: power";
CM_ SG_ 741 DIF_elecPower "Front drive inverter: elec power; raw 1024 = signal not available (SNA)";
CM_ SG_ 741 DIF_heatPowerOptimal "Front drive inverter: heat power optimal";
CM_ SG_ 741 DIF_heatPowerMax "Drive Inverter maximum heat power capability";
CM_ SG_ 741 DIF_heatPowerActual "Drive Inverter heat power";
CM_ SG_ 741 DIF_excessHeatCommand "Drive Inverter excess heat command";
CM_ SG_ 741 DIF_drivePowerMax "Front drive inverter: drive power max; raw 511 = signal not available (SNA)";
CM_ BO_ 725 "Front drive inverter message: status";
CM_ SG_ 725 DIF_statusChecksum "Front drive inverter: status checksum";
CM_ SG_ 725 DIF_statusCounter "Front drive inverter: status counter";
CM_ SG_ 725 DIF_state "DI unit state machine state.";
CM_ SG_ 725 DIF_soptState "Detects the state of the the Switch Off Path Test (SOPT); raw 8 = signal not available (SNA)";
CM_ SG_ 725 DIF_sysLimpRequest "Front drive inverter: sys limp request";
CM_ SG_ 725 DIF_softSysLimpRequest "Front drive inverter: soft sys limp request";
CM_ SG_ 725 DIF_adState "Front drive inverter: ad state";
CM_ SG_ 725 DIF_lvSupplyV "Front drive inverter: lv supply v";
CM_ SG_ 725 DIF_driveModeState "Reports the system drive mode state.";
CM_ SG_ 725 DIF_wasteState "Reports the Drive Inverter (DI) waste heat state.";
CM_ SG_ 725 DIF_haltRequest "Front drive inverter: halt request";
CM_ SG_ 725 DIF_axleSpeedLimitRequest "Front drive inverter: axle speed limit request";
CM_ SG_ 725 DIF_adDirection "Front drive inverter: ad direction";
CM_ SG_ 725 DIF_spinDownLearningState "Front drive inverter: spin down learning state";
CM_ SG_ 725 DIF_spinDownLearningMode "Front drive inverter: spin down learning mode";
CM_ BO_ 886 "Front drive inverter message: temperature";
CM_ SG_ 886 DIF_tempIndex "Front drive inverter: temp index";
CM_ SG_ 886 DIF_inverterTQF "Detects the Drive Inverter (DI) outlet temperature qualifier.";
CM_ SG_ 886 DIF_pcbT "Front drive inverter: pcb t; raw 0 = signal not available (SNA)";
CM_ SG_ 886 DIF_inverterT "Drive Inverter measured outlet temperature";
CM_ SG_ 886 DIF_statorT "Drive Inverter measured stator temperature; raw 0 = signal not available (SNA)";
CM_ SG_ 886 DIF_dcCapT "Front drive inverter: dc cap t; raw 0 = signal not available (SNA)";
CM_ SG_ 886 DIF_heatsinkT "Drive Inverter measured heatsink temperature; raw 0 = signal not available (SNA)";
CM_ SG_ 886 DIF_inverterTpct "Front drive inverter: inverter tpct";
CM_ SG_ 886 DIF_statorTpct "Front drive inverter: stator tpct";
CM_ SG_ 886 DIF_fluidInTemp "Inlet fluid temperature; raw 0 = signal not available (SNA)";
CM_ SG_ 886 DIF_normalFetBurnIn "Front drive inverter: normal fet burn in; raw 65535 = signal not available (SNA)";
CM_ SG_ 886 DIF_additionalFetBurnIn "Front drive inverter: additional fet burn in; raw 65535 = signal not available (SNA)";
CM_ SG_ 886 DIF_currentWeibullMiles "Front drive inverter: current weibull miles; raw 32767 = signal not available (SNA)";
CM_ SG_ 886 DIF_endOfServiceWeibullMiles "Front drive inverter: end of service weibull miles; raw 32767 = signal not available (SNA)";
CM_ SG_ 886 DIF_burnInDamageRatio "Front drive inverter: burn in damage ratio; raw 511 = signal not available (SNA)";
CM_ SG_ 886 DIF_inverterSensorEst "Front drive inverter: inverter sensor est";
CM_ SG_ 886 DIF_inverterHS1Est "Front drive inverter: inverter HS1 est";
CM_ SG_ 886 DIF_initialBurnInVehicleOdometer "Front drive inverter: initial burn in vehicle odometer; raw 4294967295 = signal not available (SNA)";
CM_ SG_ 886 DIF_inverterHS2Est "Front drive inverter: inverter HS2 est";
CM_ SG_ 886 DIF_inverterInletEst "Front drive inverter: inverter inlet est";
CM_ SG_ 886 DIF_statorHousingTemp "Front drive inverter: stator housing temp; raw 0 = signal not available (SNA)";
CM_ BO_ 1367 "Front drive inverter message: thermal control";
CM_ SG_ 1367 DIF_passiveInletTempReq "Front drive inverter: passive inlet temp req";
CM_ SG_ 1367 DIF_activeInletTempReq "Front drive inverter: active inlet temp req";
CM_ SG_ 1367 DIF_coolantFlowReq "Coolant flow requested";
CM_ SG_ 1367 DIF_oilFlowReq "Front drive inverter: oil flow req; raw 255 = signal not available (SNA)";
CM_ SG_ 1367 DIF_criticalFlowReq "Front drive inverter: critical flow req";
CM_ SG_ 1367 DIF_burnInStatus "Front drive inverter: burn in status";
CM_ BO_ 390 "Front drive inverter message: torque";
CM_ SG_ 390 DIF_torqueChecksum "Front drive inverter: torque checksum";
CM_ SG_ 390 DIF_torqueCounter "Front drive inverter: torque counter";
CM_ SG_ 390 DIF_torqueCommand "Torque commanded to the drive unit, referred to the axle/wheel; raw 4096 = signal not available (SNA)";
CM_ SG_ 390 DIF_axleSpeedQF "Front drive inverter: axle speed QF";
CM_ SG_ 390 DIF_torqueActual "Actual torque the drive unit is controlling to referred to the axle/wheel; raw 4096 = signal not available (SNA)";
CM_ SG_ 390 DIF_axleSpeed "Drive Inverter motor speed normalized at axle level; raw 32768 = signal not available (SNA)";
CM_ SG_ 390 DIF_axleTorqueQF "Front drive inverter: axle torque QF";
CM_ SG_ 390 DIF_axlePowerCalcQF "Front drive inverter: axle power calc QF";
CM_ SG_ 390 DIF_gear "Front drive inverter: gear; raw 7 = signal not available (SNA)";
CM_ BO_ 1557 "Front drive inverter message: uds response";
CM_ SG_ 1557 DIF_udsResponseData "Front drive inverter: uds response data";
BA_DEF_ BO_ "GenMsgCycleTime" INT 0 3600000;
BA_DEF_ BO_ "GenMsgSendType" ENUM "Cyclic","NotUsed","NotUsed","NotUsed","NotUsed","NotUsed","NotUsed","IfActive","NoMsgSendType","NotUsed";
BA_DEF_ BO_ "VFrameFormat" ENUM "StandardCAN","ExtendedCAN","reserved","J1939PG","reserved","reserved","reserved","reserved","reserved","reserved","reserved","reserved","reserved","reserved","StandardCAN_FD","ExtendedCAN_FD";
BA_DEF_ BO_ "CANFD_BRS" ENUM "0","1";
BA_DEF_ SG_ "GenSigSNA" STRING;
BA_DEF_ SG_ "SystemSignalLongSymbol" STRING;
BA_DEF_ SG_ "Confidence" ENUM "validated","plausible","layout-only","contradicted";
BA_DEF_DEF_ "GenMsgCycleTime" 0;
BA_DEF_DEF_ "GenMsgSendType" "NoMsgSendType";
BA_DEF_DEF_ "VFrameFormat" "StandardCAN";
BA_DEF_DEF_ "CANFD_BRS" "1";
BA_DEF_DEF_ "GenSigSNA" "";
BA_DEF_DEF_ "SystemSignalLongSymbol" "";
BA_DEF_DEF_ "Confidence" "layout-only";
BA_ "GenMsgCycleTime" BO_ 854 1000;
BA_ "GenMsgSendType" BO_ 854 0;
BA_ "GenMsgCycleTime" BO_ 1879 100;
BA_ "GenMsgSendType" BO_ 1879 0;
BA_ "GenMsgCycleTime" BO_ 634 100;
BA_ "GenMsgSendType" BO_ 634 0;
BA_ "GenMsgCycleTime" BO_ 1622 1000;
BA_ "GenMsgSendType" BO_ 1622 0;
BA_ "GenMsgCycleTime" BO_ 421 100;
BA_ "GenMsgSendType" BO_ 421 0;
BA_ "GenMsgCycleTime" BO_ 918 100;
BA_ "GenMsgSendType" BO_ 918 0;
BA_ "GenMsgCycleTime" BO_ 741 1000;
BA_ "GenMsgSendType" BO_ 741 0;
BA_ "GenMsgCycleTime" BO_ 725 10;
BA_ "GenMsgSendType" BO_ 725 0;
BA_ "GenMsgCycleTime" BO_ 886 1000;
BA_ "GenMsgSendType" BO_ 886 0;
BA_ "GenMsgCycleTime" BO_ 1367 1000;
BA_ "GenMsgSendType" BO_ 1367 0;
BA_ "GenMsgCycleTime" BO_ 390 10;
BA_ "GenMsgSendType" BO_ 390 0;
BA_ "Confidence" SG_ 1318 DIF_alertID 1;
BA_ "Confidence" SG_ 1318 DIF_alertState 1;
BA_ "Confidence" SG_ 1318 DIF_a007_phaseAcurrent 1;
BA_ "Confidence" SG_ 1318 DIF_a007_phaseBcurrent 1;
BA_ "Confidence" SG_ 1318 DIF_a007_offsetError 1;
BA_ "Confidence" SG_ 1318 DIF_a007_idFdbStdDeviation 1;
BA_ "Confidence" SG_ 1318 DIF_a007_iqFdbStdDeviation 1;
BA_ "Confidence" SG_ 1318 DIF_a011_reason 1;
BA_ "Confidence" SG_ 1318 DIF_a012_hvilStatus 1;
BA_ "GenSigSNA" SG_ 1318 DIF_a012_hvilStatus "3";
BA_ "Confidence" SG_ 1318 DIF_a012_hvilCmVoltage 1;
BA_ "Confidence" SG_ 1318 DIF_a012_hvilCurrent 1;
BA_ "Confidence" SG_ 1318 DIF_a013_errorType 1;
BA_ "Confidence" SG_ 1318 DIF_a014_motorSpeed 1;
BA_ "Confidence" SG_ 1318 DIF_a014_adState 1;
BA_ "Confidence" SG_ 1318 DIF_a014_torqueCommandFwd 1;
BA_ "Confidence" SG_ 1318 DIF_a014_brakeMasterCylPress 1;
BA_ "Confidence" SG_ 1318 DIF_a014_rmsTorqueError 1;
BA_ "Confidence" SG_ 1318 DIF_a016_newSafeState 1;
BA_ "Confidence" SG_ 1318 DIF_a016_oldSafeState 1;
BA_ "Confidence" SG_ 1318 DIF_a016_motorRPM 1;
BA_ "Confidence" SG_ 1318 DIF_a016_torqueMotor 1;
BA_ "Confidence" SG_ 1318 DIF_a016_triggerEvent 1;
BA_ "Confidence" SG_ 1318 DIF_a024_vBat 1;
BA_ "Confidence" SG_ 1318 DIF_a024_failReason 1;
BA_ "Confidence" SG_ 1318 DIF_a024_state 1;
BA_ "Confidence" SG_ 1318 DIF_a024_Ia 1;
BA_ "Confidence" SG_ 1318 DIF_a024_Ib 1;
BA_ "Confidence" SG_ 1318 DIF_a024_maxCurrMagSqrd 1;
BA_ "Confidence" SG_ 1318 DIF_a024_rotorAngle 1;
BA_ "Confidence" SG_ 1318 DIF_a025_Ia 1;
BA_ "Confidence" SG_ 1318 DIF_a025_torqueMotor 1;
BA_ "Confidence" SG_ 1318 DIF_a025_motorSpeed 1;
BA_ "Confidence" SG_ 1318 DIF_a026_Ib 1;
BA_ "Confidence" SG_ 1318 DIF_a026_torqueMotor 1;
BA_ "Confidence" SG_ 1318 DIF_a026_motorSpeed 1;
BA_ "Confidence" SG_ 1318 DIF_a027_Ic 1;
BA_ "Confidence" SG_ 1318 DIF_a027_torqueMotor 1;
BA_ "Confidence" SG_ 1318 DIF_a027_motorSpeed 1;
BA_ "Confidence" SG_ 1318 DIF_a028_phaseAirms 1;
BA_ "Confidence" SG_ 1318 DIF_a028_iArmsTorque 1;
BA_ "Confidence" SG_ 1318 DIF_a028_iArmsSpeed 1;
BA_ "Confidence" SG_ 1318 DIF_a029_phaseBirms 1;
BA_ "Confidence" SG_ 1318 DIF_a029_iBrmsTorque 1;
BA_ "Confidence" SG_ 1318 DIF_a029_iBrmsSpeed 1;
BA_ "Confidence" SG_ 1318 DIF_a030_phaseCirms 1;
BA_ "Confidence" SG_ 1318 DIF_a030_iCrmsTorque 1;
BA_ "Confidence" SG_ 1318 DIF_a030_iCrmsSpeed 1;
BA_ "Confidence" SG_ 1318 DIF_a031_phaseAoffset 1;
BA_ "Confidence" SG_ 1318 DIF_a032_phaseBoffset 1;
BA_ "Confidence" SG_ 1318 DIF_a033_phaseAcurrent 1;
BA_ "Confidence" SG_ 1318 DIF_a033_deltaIa 1;
BA_ "Confidence" SG_ 1318 DIF_a033_vRefIa 1;
BA_ "Confidence" SG_ 1318 DIF_a034_phaseBcurrent 1;
BA_ "Confidence" SG_ 1318 DIF_a034_deltaIb 1;
BA_ "Confidence" SG_ 1318 DIF_a034_vRefIb 1;
BA_ "Confidence" SG_ 1318 DIF_a035_phaseDifference 1;
BA_ "Confidence" SG_ 1318 DIF_a035_phaseCurrent 1;
BA_ "Confidence" SG_ 1318 DIF_a035_frequency 1;
BA_ "Confidence" SG_ 1318 DIF_a036_busVoltage 1;
BA_ "Confidence" SG_ 1318 DIF_a036_busHighLimit 1;
BA_ "Confidence" SG_ 1318 DIF_a037_busVoltage 1;
BA_ "Confidence" SG_ 1318 DIF_a037_busLowLimit 1;
BA_ "Confidence" SG_ 1318 DIF_a038_vBMS 1;
BA_ "Confidence" SG_ 1318 DIF_a038_vBat 1;
BA_ "Confidence" SG_ 1318 DIF_a038_iBat 1;
BA_ "Confidence" SG_ 1318 DIF_a038_reason 1;
BA_ "Confidence" SG_ 1318 DIF_a043_outletTemp 1;
BA_ "Confidence" SG_ 1318 DIF_a044_outletTemp 1;
BA_ "Confidence" SG_ 1318 DIF_a045_inletTemp 1;
BA_ "Confidence" SG_ 1318 DIF_a045_outletTemp 1;
BA_ "Confidence" SG_ 1318 DIF_a045_heatsinkTemp 1;
BA_ "Confidence" SG_ 1318 DIF_a045_outletTempSlope 1;
BA_ "Confidence" SG_ 1318 DIF_a046_statorTemp1 1;
BA_ "Confidence" SG_ 1318 DIF_a046_statorTemp2 1;
BA_ "Confidence" SG_ 1318 DIF_a047_statorTemp1 1;
BA_ "Confidence" SG_ 1318 DIF_a047_statorTslope1 1;
BA_ "Confidence" SG_ 1318 DIF_a050_statorTemp1 1;
BA_ "Confidence" SG_ 1318 DIF_a050_statorTemp2 1;
BA_ "Confidence" SG_ 1318 DIF_a054_outletTemp 1;
BA_ "Confidence" SG_ 1318 DIF_a054_heatsinkTemp 1;
BA_ "Confidence" SG_ 1318 DIF_a055_parameterDI 1;
BA_ "Confidence" SG_ 1318 DIF_a055_parameterPM 1;
BA_ "Confidence" SG_ 1318 DIF_a055_torqueType 1;
BA_ "Confidence" SG_ 1318 DIF_a055_motorRPM 1;
BA_ "Confidence" SG_ 1318 DIF_a056_pcbTemp 1;
BA_ "Confidence" SG_ 1318 DIF_a057_pcbTemp 1;
BA_ "Confidence" SG_ 1318 DIF_a058_pcbTemp 1;
BA_ "Confidence" SG_ 1318 DIF_a058_outletTemp 1;
BA_ "Confidence" SG_ 1318 DIF_a058_heatsinkTemp 1;
BA_ "Confidence" SG_ 1318 DIF_a058_pcbTempSlope 1;
BA_ "Confidence" SG_ 1318 DIF_a059_heatsinkTemp 1;
BA_ "Confidence" SG_ 1318 DIF_a060_heatsinkTemp 1;
BA_ "Confidence" SG_ 1318 DIF_a061_sensor 1;
BA_ "Confidence" SG_ 1318 DIF_a061_reason 1;
BA_ "Confidence" SG_ 1318 DIF_a061_phTemp 1;
BA_ "Confidence" SG_ 1318 DIF_a061_otherTemp 1;
BA_ "Confidence" SG_ 1318 DIF_a062_limpReason 1;
BA_ "Confidence" SG_ 1318 DIF_a064_interventionType 1;
BA_ "Confidence" SG_ 1318 DIF_a064_torqueCmdState 1;
BA_ "GenSigSNA" SG_ 1318 DIF_a064_torqueCmdState "0";
BA_ "Confidence" SG_ 1318 DIF_a069_motorSpeed 1;
BA_ "Confidence" SG_ 1318 DIF_a069_rotorCoolingPower 1;
BA_ "Confidence" SG_ 1318 DIF_a069_rotorMagnetTemp 1;
BA_ "Confidence" SG_ 1318 DIF_a069_fittedTorqueLimit 1;
BA_ "Confidence" SG_ 1318 DIF_a072_reason 1;
BA_ "Confidence" SG_ 1318 DIF_a073_motorSpeedrpm 1;
BA_ "Confidence" SG_ 1318 DIF_a075_motorSpeed 1;
BA_ "Confidence" SG_ 1318 DIF_a075_absSpeed 1;
BA_ "Confidence" SG_ 1318 DIF_a076_lvSupplyV 1;
BA_ "Confidence" SG_ 1318 DIF_a077_lvSupplyV 1;
BA_ "Confidence" SG_ 1318 DIF_a090_reason 1;
BA_ "SystemSignalLongSymbol" SG_ 1318 DIF_a091_ESP_redundantBrakingSta "DIF_a091_ESP_redundantBrakingStatus";
BA_ "Confidence" SG_ 1318 DIF_a097_errorType 1;
BA_ "Confidence" SG_ 1318 DIF_a098_fluxState 1;
BA_ "Confidence" SG_ 1318 DIF_a103_fluidTorDeltaT 1;
BA_ "Confidence" SG_ 1318 DIF_a103_inverterTemp 1;
BA_ "Confidence" SG_ 1318 DIF_a103_rmsCurrent 1;
BA_ "Confidence" SG_ 1318 DIF_a103_ambientTemp 1;
BA_ "Confidence" SG_ 1318 DIF_a103_sensorTempEst 1;
BA_ "Confidence" SG_ 1318 DIF_a108_blockingAlert 1;
BA_ "Confidence" SG_ 1318 DIF_a112_modulationIndex 1;
BA_ "Confidence" SG_ 1318 DIF_a113_heatsink1Temp 1;
BA_ "Confidence" SG_ 1318 DIF_a113_heatsink2Temp 1;
BA_ "Confidence" SG_ 1318 DIF_a113_heatsink3Temp 1;
BA_ "Confidence" SG_ 1318 DIF_a121_badRegReason 1;
BA_ "Confidence" SG_ 1318 DIF_a121_torqueDelta 1;
BA_ "Confidence" SG_ 1318 DIF_a121_badCurrent 1;
BA_ "Confidence" SG_ 1318 DIF_a121_badFlux 1;
BA_ "Confidence" SG_ 1318 DIF_a123_lossReason 1;
BA_ "Confidence" SG_ 1318 DIF_a123_busVoltage 1;
BA_ "Confidence" SG_ 1318 DIF_a123_badFlux 1;
BA_ "Confidence" SG_ 1318 DIF_a123_lossRequest 1;
BA_ "Confidence" SG_ 1318 DIF_a123_badCurrent 1;
BA_ "Confidence" SG_ 1318 DIF_a123_motorRPM 1;
BA_ "Confidence" SG_ 1318 DIF_a123_varianceD 1;
BA_ "Confidence" SG_ 1318 DIF_a123_varianceQ 1;
BA_ "Confidence" SG_ 1318 DIF_a126_limpReason 1;
BA_ "Confidence" SG_ 1318 DIF_a127_gpoReason 1;
BA_ "Confidence" SG_ 1318 DIF_a127_temp 1;
BA_ "Confidence" SG_ 1318 DIF_a133_capacitorTemp 1;
BA_ "Confidence" SG_ 1318 DIF_a133_badValue1 1;
BA_ "Confidence" SG_ 1318 DIF_a133_badValue2 1;
BA_ "Confidence" SG_ 1318 DIF_a134_wheelSpeedDiffFrL 1;
BA_ "Confidence" SG_ 1318 DIF_a134_wheelSpeedDiffFrR 1;
BA_ "Confidence" SG_ 1318 DIF_a134_wheelSpeedDiffReL 1;
BA_ "Confidence" SG_ 1318 DIF_a134_wheelSpeedDiffReR 1;
BA_ "SystemSignalLongSymbol" SG_ 1318 DIF_a144_packPerformanceDeviatio "DIF_a144_packPerformanceDeviation";
BA_ "Confidence" SG_ 1318 DIF_a147_accumulatedWear 1;
BA_ "Confidence" SG_ 1318 DIF_a149_flow 1;
BA_ "GenSigSNA" SG_ 1318 DIF_a149_flow "255";
BA_ "Confidence" SG_ 1318 DIF_a149_voltage 1;
BA_ "Confidence" SG_ 1318 DIF_a149_temperature 1;
BA_ "Confidence" SG_ 1318 DIF_a149_state 1;
BA_ "GenSigSNA" SG_ 1318 DIF_a149_state "7";
BA_ "Confidence" SG_ 1318 DIF_a149_pcbaID 1;
BA_ "Confidence" SG_ 1318 DIF_a150_vBatRawMinusFiltered 1;
BA_ "Confidence" SG_ 1318 DIF_a150_vBatFilteredRate 1;
BA_ "Confidence" SG_ 1318 DIF_a150_elapsedMs 1;
BA_ "Confidence" SG_ 1318 DIF_a150_energy 1;
BA_ "Confidence" SG_ 1318 DIF_a152_errorType 1;
BA_ "Confidence" SG_ 1318 DIF_a154_motorRPM 1;
BA_ "Confidence" SG_ 1318 DIF_a154_phaseError 1;
BA_ "Confidence" SG_ 1318 DIF_a154_commonGain 1;
BA_ "SystemSignalLongSymbol" SG_ 1318 DIF_a158_IBST_redundantBrakingSt "DIF_a158_IBST_redundantBrakingStatus";
BA_ "Confidence" SG_ 1318 DIF_a160_vBatRawMinusFiltered 1;
BA_ "Confidence" SG_ 1318 DIF_a160_vBatFilteredRate 1;
BA_ "Confidence" SG_ 1318 DIF_a160_elapsedMs 1;
BA_ "Confidence" SG_ 1318 DIF_a160_energy 1;
BA_ "Confidence" SG_ 1318 DIF_a172_statorTemp1 1;
BA_ "Confidence" SG_ 1318 DIF_a172_statorTemp2 1;
BA_ "Confidence" SG_ 1318 DIF_a202_reason 1;
BA_ "Confidence" SG_ 1318 DIF_a202_movement 1;
BA_ "Confidence" SG_ 1318 DIF_a202_sysStateExitCondition 1;
BA_ "Confidence" SG_ 1318 DIF_a240_fuseA_I2t 1;
BA_ "Confidence" SG_ 1318 DIF_a240_fuseB_I2t 1;
BA_ "Confidence" SG_ 1318 DIF_a244_irSensorV 1;
BA_ "SystemSignalLongSymbol" SG_ 1318 DIF_a244_plausibleSingleSwitchSh "DIF_a244_plausibleSingleSwitchShortOnly";
BA_ "Confidence" SG_ 1318 DIF_a244_delay 1;
BA_ "SystemSignalLongSymbol" SG_ 1318 DIF_a246_didPMCauseSwitchOf_0001 "DIF_a246_didPMCauseSwitchOffPathNominal";
BA_ "SystemSignalLongSymbol" SG_ 1318 DIF_a246_didPMCauseSwitchOffPath "DIF_a246_didPMCauseSwitchOffPathLowSpeed";
BA_ "SystemSignalLongSymbol" SG_ 1318 DIF_a246_observerDetectedSw_0001 "DIF_a246_observerDetectedSwitchOffPathNominal";
BA_ "SystemSignalLongSymbol" SG_ 1318 DIF_a246_observerDetectedSwitchO "DIF_a246_observerDetectedSwitchOffPathLowSpeed";
BA_ "Confidence" SG_ 1318 DIF_a246_codeBranch 1;
BA_ "Confidence" SG_ 1318 DIF_a246_motorRPM 1;
BA_ "Confidence" SG_ 1318 DIF_a246_eepromOffsetIa 1;
BA_ "Confidence" SG_ 1318 DIF_a246_eepromOffsetIb 1;
BA_ "Confidence" SG_ 1318 DIF_a247_rotorOffsetEst 1;
BA_ "Confidence" SG_ 1318 DIF_a247_motorRPM 1;
BA_ "Confidence" SG_ 1318 DIF_a247_torqueMotor 1;
BA_ "Confidence" SG_ 1318 DIF_a251_oilFlow 1;
BA_ "GenSigSNA" SG_ 1318 DIF_a251_oilFlow "255";
BA_ "Confidence" SG_ 1318 DIF_a251_oilTemperature 1;
BA_ "GenSigSNA" SG_ 1318 DIF_a251_oilTemperature "255";
BA_ "Confidence" SG_ 1318 DIF_a251_dcVoltage 1;
BA_ "GenSigSNA" SG_ 1318 DIF_a251_dcVoltage "255";
BA_ "Confidence" SG_ 1318 DIF_a251_dcCurrent 1;
BA_ "GenSigSNA" SG_ 1318 DIF_a251_dcCurrent "255";
BA_ "Confidence" SG_ 1318 DIF_a251_phaseCurrent 1;
BA_ "GenSigSNA" SG_ 1318 DIF_a251_phaseCurrent "255";
BA_ "Confidence" SG_ 1318 DIF_a251_leadAngle 1;
BA_ "Confidence" SG_ 1318 DIF_a251_reason 1;
BA_ "Confidence" SG_ 1318 DIF_a253_voltage 1;
BA_ "Confidence" SG_ 1318 DIF_a253_reason 1;
BA_ "Confidence" SG_ 854 DIF_matrixIndex 0;
BA_ "SystemSignalLongSymbol" SG_ 854 DIF_a039_exceptionUndefinedInstr "DIF_a039_exceptionUndefinedInstruction";
BA_ "SystemSignalLongSymbol" SG_ 854 DIF_d085_driveInverterBoardFailu "DIF_d085_driveInverterBoardFailure";
BA_ "SystemSignalLongSymbol" SG_ 854 DIF_d138_inverterLVPowerSupplyLo "DIF_d138_inverterLVPowerSupplyLow";
BA_ "SystemSignalLongSymbol" SG_ 854 DIF_d143_wheelSpeedCorrelationIs "DIF_d143_wheelSpeedCorrelationIssue";
BA_ "Confidence" SG_ 854 DIF_a154_resolver 0;
BA_ "SystemSignalLongSymbol" SG_ 854 DIF_a249_highStatorTempFromResis "DIF_a249_highStatorTempFromResist";
BA_ "Confidence" SG_ 1879 DIF_debugSelector 1;
BA_ "Confidence" SG_ 1879 DIF_motorIA 1;
BA_ "Confidence" SG_ 1879 DIF_motorIB 1;
BA_ "Confidence" SG_ 1879 DIF_motorIC 1;
BA_ "Confidence" SG_ 1879 DIF_statorIDref 1;
BA_ "Confidence" SG_ 1879 DIF_statorIDfdb 1;
BA_ "Confidence" SG_ 1879 DIF_torquePerAmp 1;
BA_ "Confidence" SG_ 1879 DIF_rsScale 1;
BA_ "Confidence" SG_ 1879 DIF_statorIQref 1;
BA_ "Confidence" SG_ 1879 DIF_statorIQfdb 1;
BA_ "Confidence" SG_ 1879 DIF_motorV 1;
BA_ "Confidence" SG_ 1879 DIF_tqScaleDifferential 1;
BA_ "Confidence" SG_ 1879 DIF_statorFluxRef 1;
BA_ "Confidence" SG_ 1879 DIF_statorFluxFdb 1;
BA_ "Confidence" SG_ 1879 DIF_lmScale 1;
BA_ "Confidence" SG_ 1879 DIF_statorVQ 1;
BA_ "Confidence" SG_ 1879 DIF_statorVD 1;
BA_ "Confidence" SG_ 1879 DIF_peakFlux 1;
BA_ "Confidence" SG_ 1879 DIF_gainScale 1;
BA_ "Confidence" SG_ 1879 DIF_usmState 1;
BA_ "Confidence" SG_ 1879 DIF_peakIQref 1;
BA_ "Confidence" SG_ 1879 DIF_motorIAavg 1;
BA_ "Confidence" SG_ 1879 DIF_motorIBavg 1;
BA_ "Confidence" SG_ 1879 DIF_tqSatThermal 1;
BA_ "Confidence" SG_ 1879 DIF_tqSatMotorVoltage 1;
BA_ "Confidence" SG_ 1879 DIF_tqSatMotorCurrent 1;
BA_ "Confidence" SG_ 1879 DIF_tcMaxRequest 1;
BA_ "Confidence" SG_ 1879 DIF_tcMinRequest 1;
BA_ "Confidence" SG_ 1879 DIF_tqScaleMaxMotorSpeed 1;
BA_ "Confidence" SG_ 1879 DIF_wasteCurrentLimit 1;
BA_ "Confidence" SG_ 1879 DIF_llsScale 1;
BA_ "Confidence" SG_ 1879 DIF_llrScale 1;
BA_ "Confidence" SG_ 1879 DIF_oilPumpMotorSpeed 1;
BA_ "Confidence" SG_ 1879 DIF_rotorFlux 1;
BA_ "Confidence" SG_ 1879 DIF_dcCableHeat 1;
BA_ "Confidence" SG_ 1879 DIF_magnetTempEst 1;
BA_ "Confidence" SG_ 1879 DIF_resolverReady 1;
BA_ "Confidence" SG_ 1879 DIF_resolverNoCarrier 1;
BA_ "Confidence" SG_ 1879 DIF_resolverNoPhaseLock 1;
BA_ "Confidence" SG_ 1879 DIF_resolverClaMIA 1;
BA_ "Confidence" SG_ 1879 DIF_soptMaxCurrentMagSqrd 1;
BA_ "Confidence" SG_ 1879 DIF_statorVDFiltered 1;
BA_ "Confidence" SG_ 1879 DIF_statorVQFiltered 1;
BA_ "Confidence" SG_ 1879 DIF_pwmState 1;
BA_ "Confidence" SG_ 1879 DIF_dcCapTemp 1;
BA_ "Confidence" SG_ 1879 DIF_busbarTemp 1;
BA_ "Confidence" SG_ 1879 DIF_pcsTemp 1;
BA_ "Confidence" SG_ 1879 DIF_statorTemp1 1;
BA_ "Confidence" SG_ 1879 DIF_statorTemp2 1;
BA_ "Confidence" SG_ 1879 DIF_cpu10HzMin 1;
BA_ "Confidence" SG_ 1879 DIF_cpu10HzAvg 1;
BA_ "Confidence" SG_ 1879 DIF_cpu100HzMin 1;
BA_ "Confidence" SG_ 1879 DIF_cpu100HzAvg 1;
BA_ "Confidence" SG_ 1879 DIF_cpu10msMin 1;
BA_ "Confidence" SG_ 1879 DIF_cpu1kHzMin 1;
BA_ "Confidence" SG_ 1879 DIF_cpu1kHzAvg 1;
BA_ "Confidence" SG_ 1879 DIF_cpu20kHzMin 1;
BA_ "Confidence" SG_ 1879 DIF_cpu20kHzAvg 1;
BA_ "Confidence" SG_ 1879 DIF_hwFaultCount 1;
BA_ "Confidence" SG_ 1879 DIF_driveUnitOdometer 1;
BA_ "Confidence" SG_ 1879 DIF_phaseOutBusbarTemp 1;
BA_ "GenSigSNA" SG_ 1879 DIF_phaseOutBusbarTemp "0";
BA_ "Confidence" SG_ 1879 DIF_phaseOutBusbarWeldTemp 1;
BA_ "GenSigSNA" SG_ 1879 DIF_phaseOutBusbarWeldTemp "0";
BA_ "Confidence" SG_ 1879 DIF_phaseOutLugTemp 1;
BA_ "GenSigSNA" SG_ 1879 DIF_phaseOutLugTemp "0";
BA_ "Confidence" SG_ 1879 DIF_dcLinkCapTemp 1;
BA_ "GenSigSNA" SG_ 1879 DIF_dcLinkCapTemp "0";
BA_ "Confidence" SG_ 1879 DIF_hvDcCableTemp 1;
BA_ "GenSigSNA" SG_ 1879 DIF_hvDcCableTemp "0";
BA_ "Confidence" SG_ 1879 DIF_negDcBusbarTemp 1;
BA_ "GenSigSNA" SG_ 1879 DIF_negDcBusbarTemp "0";
BA_ "Confidence" SG_ 1879 DIF_posDcBusbarTemp 1;
BA_ "GenSigSNA" SG_ 1879 DIF_posDcBusbarTemp "0";
BA_ "Confidence" SG_ 1879 DIF_statorEndWindingTemp 1;
BA_ "GenSigSNA" SG_ 1879 DIF_statorEndWindingTemp "0";
BA_ "Confidence" SG_ 1879 DIF_rotorMaxMagnetTemp 1;
BA_ "GenSigSNA" SG_ 1879 DIF_rotorMaxMagnetTemp "0";
BA_ "Confidence" SG_ 1879 DIF_lightSenseV 1;
BA_ "Confidence" SG_ 1879 DIF_pyroSenseV 1;
BA_ "Confidence" SG_ 1879 DIF_statorSlotWindingTemp 1;
BA_ "GenSigSNA" SG_ 1879 DIF_statorSlotWindingTemp "0";
BA_ "Confidence" SG_ 1879 DIF_intervalMaxHvBusV 1;
BA_ "Confidence" SG_ 1879 DIF_cpu1HzMin 1;
BA_ "Confidence" SG_ 1879 DIF_cpu1HzAvg 1;
BA_ "Confidence" SG_ 1879 DIF_cpuIDWord0 1;
BA_ "Confidence" SG_ 1879 DIF_cpuIDWord1 1;
BA_ "Confidence" SG_ 1879 DIF_cpuIDWord2 1;
BA_ "Confidence" SG_ 1879 DIF_cpuIDWord3 1;
BA_ "Confidence" SG_ 634 DIF_hvStatusChecksum 0;
BA_ "Confidence" SG_ 634 DIF_hvStatusCounter 0;
BA_ "Confidence" SG_ 634 DIF_hvilCurrent 0;
BA_ "Confidence" SG_ 634 DIF_hvilCmVoltage 0;
BA_ "Confidence" SG_ 634 DIF_hvilStatus 0;
BA_ "GenSigSNA" SG_ 634 DIF_hvilStatus "3";
BA_ "Confidence" SG_ 634 DIF_hvilSupplyState 0;
BA_ "Confidence" SG_ 634 DIF_activeDischargeCtrl 0;
BA_ "Confidence" SG_ 634 DIF_activeDischargeStatus 0;
BA_ "Confidence" SG_ 634 DIF_vBat 0;
BA_ "Confidence" SG_ 634 DIF_vBatQF 1;
BA_ "Confidence" SG_ 634 DIF_powerStageSafeState 1;
BA_ "Confidence" SG_ 634 DIF_fluxState 1;
BA_ "Confidence" SG_ 634 DIF_vBusDiag 0;
BA_ "Confidence" SG_ 634 DIF_gateDriveState 1;
BA_ "Confidence" SG_ 634 DIF_gateDriveSupplyState 1;
BA_ "Confidence" SG_ 1622 DIF_infoIndex 1;
BA_ "Confidence" SG_ 1622 DIF_buildType 1;
BA_ "Confidence" SG_ 1622 DIF_hardwareId 1;
BA_ "Confidence" SG_ 1622 DIF_motorType 1;
BA_ "GenSigSNA" SG_ 1622 DIF_motorType "0";
BA_ "Confidence" SG_ 1622 DIF_siliconType 1;
BA_ "Confidence" SG_ 1622 DIF_mechSafeStateType 1;
BA_ "GenSigSNA" SG_ 1622 DIF_mechSafeStateType "0";
BA_ "Confidence" SG_ 1622 DIF_oilPumpBuildType 1;
BA_ "Confidence" SG_ 1622 DIF_FPGA_version 1;
BA_ "GenSigSNA" SG_ 1622 DIF_FPGA_version "255";
BA_ "Confidence" SG_ 1622 DIF_subcomponentGitHash 1;
BA_ "Confidence" SG_ 1622 DIF_refRotorFlux 1;
BA_ "Confidence" SG_ 1622 DIF_refRotorOffset 1;
BA_ "GenSigSNA" SG_ 1622 DIF_refRotorOffset "2048";
BA_ "Confidence" SG_ 1622 DIF_speedWearTotal 1;
BA_ "GenSigSNA" SG_ 1622 DIF_speedWearTotal "255";
BA_ "Confidence" SG_ 1622 DIF_torqueWearTotal 1;
BA_ "GenSigSNA" SG_ 1622 DIF_torqueWearTotal "255";
BA_ "Confidence" SG_ 421 DIF_motorCurrent 1;
BA_ "Confidence" SG_ 421 DIF_switchingFrequency 1;
BA_ "Confidence" SG_ 421 DIF_targetFluxMode 1;
BA_ "Confidence" SG_ 421 DIF_keepAliveRequest 1;
BA_ "Confidence" SG_ 918 DIF_oilPumpState 1;
BA_ "GenSigSNA" SG_ 918 DIF_oilPumpState "7";
BA_ "Confidence" SG_ 918 DIF_oilPumpFluidTQF 1;
BA_ "Confidence" SG_ 918 DIF_oilPumpLeadAngle 1;
BA_ "Confidence" SG_ 918 DIF_oilPumpFlowTarget 1;
BA_ "GenSigSNA" SG_ 918 DIF_oilPumpFlowTarget "255";
BA_ "Confidence" SG_ 918 DIF_oilPumpFlowActual 1;
BA_ "GenSigSNA" SG_ 918 DIF_oilPumpFlowActual "255";
BA_ "Confidence" SG_ 918 DIF_oilPumpFluidT 1;
BA_ "GenSigSNA" SG_ 918 DIF_oilPumpFluidT "255";
BA_ "Confidence" SG_ 918 DIF_oilPumpPhaseCurrent 1;
BA_ "GenSigSNA" SG_ 918 DIF_oilPumpPhaseCurrent "255";
BA_ "Confidence" SG_ 918 DIF_oilPumpPressureEstimate 1;
BA_ "GenSigSNA" SG_ 918 DIF_oilPumpPressureEstimate "255";
BA_ "Confidence" SG_ 918 DIF_oilPumpPressureExpected 1;
BA_ "GenSigSNA" SG_ 918 DIF_oilPumpPressureExpected "255";
BA_ "Confidence" SG_ 918 DIF_oilPumpPressureResidual 1;
BA_ "GenSigSNA" SG_ 918 DIF_oilPumpPressureResidual "255";
BA_ "Confidence" SG_ 741 DIF_elecPower 0;
BA_ "GenSigSNA" SG_ 741 DIF_elecPower "1024";
BA_ "Confidence" SG_ 741 DIF_heatPowerOptimal 0;
BA_ "Confidence" SG_ 741 DIF_heatPowerMax 0;
BA_ "Confidence" SG_ 741 DIF_heatPowerActual 0;
BA_ "Confidence" SG_ 741 DIF_excessHeatCommand 0;
BA_ "Confidence" SG_ 741 DIF_drivePowerMax 0;
BA_ "GenSigSNA" SG_ 741 DIF_drivePowerMax "511";
BA_ "Confidence" SG_ 725 DIF_state 1;
BA_ "Confidence" SG_ 725 DIF_soptState 1;
BA_ "GenSigSNA" SG_ 725 DIF_soptState "8";
BA_ "Confidence" SG_ 725 DIF_adState 1;
BA_ "Confidence" SG_ 725 DIF_lvSupplyV 1;
BA_ "Confidence" SG_ 725 DIF_driveModeState 1;
BA_ "Confidence" SG_ 725 DIF_wasteState 1;
BA_ "Confidence" SG_ 725 DIF_haltRequest 1;
BA_ "Confidence" SG_ 725 DIF_axleSpeedLimitRequest 1;
BA_ "Confidence" SG_ 725 DIF_adDirection 1;
BA_ "Confidence" SG_ 725 DIF_spinDownLearningState 1;
BA_ "Confidence" SG_ 725 DIF_spinDownLearningMode 1;
BA_ "Confidence" SG_ 886 DIF_tempIndex 1;
BA_ "Confidence" SG_ 886 DIF_inverterTQF 0;
BA_ "Confidence" SG_ 886 DIF_pcbT 0;
BA_ "GenSigSNA" SG_ 886 DIF_pcbT "0";
BA_ "Confidence" SG_ 886 DIF_inverterT 0;
BA_ "Confidence" SG_ 886 DIF_statorT 0;
BA_ "GenSigSNA" SG_ 886 DIF_statorT "0";
BA_ "Confidence" SG_ 886 DIF_dcCapT 0;
BA_ "GenSigSNA" SG_ 886 DIF_dcCapT "0";
BA_ "Confidence" SG_ 886 DIF_heatsinkT 0;
BA_ "GenSigSNA" SG_ 886 DIF_heatsinkT "0";
BA_ "Confidence" SG_ 886 DIF_inverterTpct 0;
BA_ "Confidence" SG_ 886 DIF_statorTpct 0;
BA_ "Confidence" SG_ 886 DIF_fluidInTemp 0;
BA_ "GenSigSNA" SG_ 886 DIF_fluidInTemp "0";
BA_ "Confidence" SG_ 886 DIF_normalFetBurnIn 0;
BA_ "GenSigSNA" SG_ 886 DIF_normalFetBurnIn "65535";
BA_ "Confidence" SG_ 886 DIF_additionalFetBurnIn 0;
BA_ "GenSigSNA" SG_ 886 DIF_additionalFetBurnIn "65535";
BA_ "Confidence" SG_ 886 DIF_currentWeibullMiles 0;
BA_ "GenSigSNA" SG_ 886 DIF_currentWeibullMiles "32767";
BA_ "Confidence" SG_ 886 DIF_endOfServiceWeibullMiles 0;
BA_ "GenSigSNA" SG_ 886 DIF_endOfServiceWeibullMiles "32767";
BA_ "Confidence" SG_ 886 DIF_burnInDamageRatio 0;
BA_ "GenSigSNA" SG_ 886 DIF_burnInDamageRatio "511";
BA_ "Confidence" SG_ 886 DIF_inverterSensorEst 0;
BA_ "Confidence" SG_ 886 DIF_inverterHS1Est 0;
BA_ "Confidence" SG_ 886 DIF_initialBurnInVehicleOdometer 0;
BA_ "GenSigSNA" SG_ 886 DIF_initialBurnInVehicleOdometer "4294967295";
BA_ "Confidence" SG_ 886 DIF_inverterHS2Est 0;
BA_ "Confidence" SG_ 886 DIF_inverterInletEst 0;
BA_ "Confidence" SG_ 886 DIF_statorHousingTemp 0;
BA_ "GenSigSNA" SG_ 886 DIF_statorHousingTemp "0";
BA_ "Confidence" SG_ 1367 DIF_passiveInletTempReq 0;
BA_ "Confidence" SG_ 1367 DIF_activeInletTempReq 0;
BA_ "Confidence" SG_ 1367 DIF_coolantFlowReq 0;
BA_ "Confidence" SG_ 1367 DIF_oilFlowReq 0;
BA_ "GenSigSNA" SG_ 1367 DIF_oilFlowReq "255";
BA_ "Confidence" SG_ 1367 DIF_criticalFlowReq 0;
BA_ "Confidence" SG_ 1367 DIF_burnInStatus 0;
BA_ "Confidence" SG_ 390 DIF_torqueCommand 1;
BA_ "GenSigSNA" SG_ 390 DIF_torqueCommand "4096";
BA_ "Confidence" SG_ 390 DIF_axleSpeedQF 1;
BA_ "Confidence" SG_ 390 DIF_torqueActual 1;
BA_ "GenSigSNA" SG_ 390 DIF_torqueActual "4096";
BA_ "Confidence" SG_ 390 DIF_axleSpeed 1;
BA_ "GenSigSNA" SG_ 390 DIF_axleSpeed "32768";
BA_ "Confidence" SG_ 390 DIF_axleTorqueQF 1;
BA_ "Confidence" SG_ 390 DIF_axlePowerCalcQF 1;
BA_ "Confidence" SG_ 390 DIF_gear 1;
BA_ "GenSigSNA" SG_ 390 DIF_gear "7";
BA_ "Confidence" SG_ 1557 DIF_udsResponseData 1;
VAL_ 1318 DIF_alertID 255 "a255_currentGainFallback" 254 "a254_activeDischargeRail" 253 "a253_lvBoostedRail" 252 "a252_currentCoreFallback" 251 "a251_oilPumpService" 250 "a250_preregulatorRail" 249 "a249_highStatorTempFromResist" 247 "a247_rotorOffsetError" 246 "a246_recoveryAtSpeedError" 245 "a245_mechSafeStatePreWarn" 244 "a244_mechSafeStateApplied" 243 "a243_ecuLogAvailable" 242 "a242_spinDownLearning" 241 "a241_systemThermallyLimited" 240 "a240_clearFusesRoutine" 236 "a236_tasMIA" 234 "a234_pcsMIA" 233 "a233_diMsgMissed" 229 "a229_busVsensorOverCAN" 225 "a225_tmpEstPlausibility" 202 "a202_excessHeatUnavailable" 177 "a177_fluxReferenceCorrected" 176 "a176_safetyICFault" 174 "a174_unitMayNotRestart" 173 "a173_ascFdbkDiagnostic" 172 "a172_statorOilTempOT" 170 "d170_clutchFailure" 169 "d169_clutchPosition" 168 "d168_clutchPerformance" 167 "d167_tempSensorIssue" 166 "d166_rotorOverTemperature" 165 "d165_statorOverTemperature" 164 "d164_firmwareConfigMismatch" 163 "d163_recoverableOvercurrent" 162 "a162_endOfLifetimeBurnIn" 161 "a161_epas3pMIA" 160 "a160_busVoltageAnomaly" 158 "a158_ibstMIA" 157 "a157_rcmMIA" 156 "a156_currentObserver" 155 "a155_vcfrontMIA" 154 "a154_resolver" 153 "a153_oilPumpDiagnostics" 152 "a152_linError" 151 "a151_shockTorqueLimiter" 150 "a150_busVD" 149 "a149_oilPumpFailure" 148 "a148_burnInCycleEnded" 147 "a147_highTorqueWearLimit" 144 "a144_configMismatch" 143 "d143_wheelSpeedCorrelationIssue" 142 "a142_highLashAngle" 141 "d141_coolingSystemIssue" 138 "d138_inverterLVPowerSupplyLow" 137 "d137_currentSensorOutOfRange" 136 "a136_spiError" 135 "d135_rotatedStator" 134 "a134_wheelSpeedIrrational" 133 "a133_capacitorOT" 132 "d132_busUVIssue" 131 "d131_currentSensorOffset" 130 "d130_positionSensorIssue" 129 "d129_oilPumpIssue" 128 "a128_fpgaVersionMismatch" 127 "a127_gracefulPowerOff" 126 "a126_limpMode" 125 "d125_currentSensorIssue" 124 "d124_oilPumpServiceRequired" 123 "a123_lossMotorControl" 122 "a122_highStackUsage" 121 "a121_motorControlRegulation" 120 "a120_hvlinkMIA" 119 "a119_hvpMIA" 118 "d118_oilPumpCommsLost" 117 "a117_diMIA" 116 "a116_highSpeedWearCounter" 115 "a115_exceptionDataAbort2" 114 "a114_exceptionDataAbort" 113 "a113_noFuncHeatsinkSensor" 112 "a112_noPhaseCurrent" 111 "a111_badPhaseSensorCalib" 110 "a110_brakeMIA" 109 "a109_ahbWriteError" 108 "a108_stateTrans" 107 "a107_fpgaError" 106 "a106_idleTaskStarving" 105 "d105_busVoltageSensorIssue" 104 "d104_resetUnintended" 103 "a103_lowFlow" 102 "a102_exceptionPrefetchAbort" 101 "a101_eccTestData1" 100 "a100_assertion" 99 "a099_threadOverrun" 98 "a098_intTimeTooLong" 97 "a097_eepromError" 96 "a096_memoryError" 95 "a095_canOverrunBusA" 94 "a094_canDataBusA" 93 "a093_canHardwareBusA" 92 "a092_bmsMIA" 91 "a091_espMIA" 90 "a090_pmMIA" 89 "d089_invalidTorqueCommand" 88 "a088_uiMIA" 87 "a087_gtwMIA" 86 "a086_activeDischargeOn" 85 "d085_driveInverterBoardFailure" 84 "a084_eccTestData0" 79 "a079_adcRefHigh" 78 "a078_adcRefLow" 77 "a077_lvSupplyUV" 76 "a076_lvSupplyOV" 75 "a075_motorSpeedMismatch" 74 "a074_motorEncoder" 73 "a073_motorSpeed" 72 "a072_gateDriveFaultCounter" 71 "a071_busDisconnected" 70 "a070_udsTransactionInitiated" 69 "a069_rotorTempLimit" 67 "a067_canOverrunBusB" 66 "a066_canDataBusB" 65 "a065_canHardwareBusB" 64 "a064_torqueIntervention" 63 "a063_bbMIA" 62 "a062_systemLimpMode" 61 "a061_heatsinkSensor" 60 "a060_heatsinkUT" 59 "a059_heatsinkOT" 58 "a058_ambientSensor" 57 "a057_ambientUT" 56 "a056_ambientOT" 55 "a055_trqCrossCheck" 54 "a054_driveInverterOT" 53 "a053_unexpectedLatchState" 52 "a052_dirMIA" 50 "a050_noStatorSensor" 49 "a049_statorSensorDiff" 48 "a048_statorSensor2" 47 "a047_statorSensor1" 46 "a046_statorOT" 45 "a045_outletSensor" 44 "a044_outletUT" 43 "a043_outletOT" 42 "a042_inletSensor" 41 "a041_sdcMIA" 40 "a040_difMIA" 39 "a039_exceptionUndefinedInstruction" 38 "a038_busVsensor" 37 "a037_busUV" 36 "a036_busOV" 35 "a035_phaseCurrentBalance" 34 "a034_phaseBcurrentSensor" 33 "a033_phaseAcurrentSensor" 32 "a032_phaseBcurrentOffset" 31 "a031_phaseAcurrentOffset" 30 "a030_phaseCrms" 29 "a029_phaseBrms" 28 "a028_phaseArms" 27 "a027_phaseCpeak" 26 "a026_phaseBpeak" 25 "a025_phaseApeak" 24 "a024_selfTest" 22 "a022_hw5vSupplyUV" 21 "a021_hwBusOV" 20 "a020_hwMotorEncoder" 18 "a018_hwLVSupplyUV" 17 "a017_hwPedalMonitor" 16 "a016_safeStateApplied" 15 "a015_mechSafeStateAnomaly" 14 "a014_activeDamping" 13 "a013_eccError" 12 "a012_hvilNotClosed" 11 "a011_swPowerStageNotReady" 10 "a010_unintendedReset" 9 "a009_hwEncoderB" 8 "a008_hwEncoderA" 7 "a007_statorAnomalyDetected" 6 "a006_hwPhaseCpeak" 5 "a005_hwPhaseBpeak" 4 "a004_hwPhaseApeak" 3 "a003_hwPhaseCgateDrive" 2 "a002_hwPhaseBgateDrive" 1 "a001_hwPhaseAgateDrive" 0 "ALERT_DO_NOT_USE_ZERO" ;
VAL_ 1318 DIF_alertState 1 "SET" 0 "CLEARED" ;
VAL_ 1318 DIF_a011_reason 4 "SPI_ERROR" 3 "FAULT_DURING_CONFIG" 2 "CRC_MISMATCH" 1 "REG_DATA_MISMATCH" 0 "GATE_DRIVE_SUPPLY" ;
VAL_ 1318 DIF_a012_hvilStatus 3 "SNA" 2 "CLOSED" 1 "OPEN" 0 "DISABLED" ;
VAL_ 1318 DIF_a013_errorType 12 "RAM_CORRECTABLE_DMA" 11 "RAM_CORRECTABLE_CLA" 10 "RAM_CORRECTABLE_CPU" 9 "RAM_UNCORRECTABLE_DMA" 8 "RAM_UNCORRECTABLE_CLA" 7 "RAM_UNCORRECTABLE_CPU" 6 "FLASH_FAIL1_HIGH" 5 "FLASH_FAIL1_LOW" 4 "FLASH_FAIL0_HIGH" 3 "FLASH_FAIL0_LOW" 2 "FLASH_UNCORRECTABLE_HIGH" 1 "FLASH_UNCORRECTABLE_LOW" 0 "UNKNOWN" ;
VAL_ 1318 DIF_a014_adState 3 "FAULTED" 2 "BACKUP" 1 "NORMAL" 0 "STARTUP" ;
VAL_ 1318 DIF_a016_newSafeState 3 "3PS_LOW" 2 "3PS_HIGH" 1 "ALL_OFF" 0 "NONE" ;
VAL_ 1318 DIF_a016_oldSafeState 3 "3PS_LOW" 2 "3PS_HIGH" 1 "ALL_OFF" 0 "NONE" ;
VAL_ 1318 DIF_a016_triggerEvent 31 "HV_SENSE_OVER_CAN" 30 "SWITCH_SHORT_DISABLE_CONDITIONS_MET" 29 "AT_SPEED_RECOVERY" 28 "CURRENT_OBSERVER" 27 "MECHSS_CALLBACK" 26 "3PS_FEEDBACK" 25 "SWITCH_OFF_PATH_TRIP" 24 "BUS_ANOMALY" 23 "GDIC_FAULT" 22 "SELFTEST_FAIL" 21 "CLEAR_FUSES" 20 "SPEED_INVALID" 19 "BUS_UV" 18 "BUS_IRRATIONAL" 17 "BUS_OV" 16 "PEAK_CURRENT" 15 "NO_CURRENT" 14 "IRRATIONAL_CURRENT_DELTA_PHASEW" 13 "IRRATIONAL_CURRENT_DELTA_PHASEV" 12 "IRRATIONAL_CURRENT_DELTA_PHASEC" 11 "IRRATIONAL_CURRENT_DELTA_PHASEB" 10 "IRRATIONAL_CURRENT_DELTA_PHASEA" 9 "IRRATIONAL_CURRENT_VREF" 8 "IRRATIONAL_CURRENT_PHASEW" 7 "IRRATIONAL_CURRENT_PHASEV" 6 "IRRATIONAL_CURRENT_PHASEC" 5 "IRRATIONAL_CURRENT_PHASEB" 4 "IRRATIONAL_CURRENT_PHASEA" 3 "RESOLVER" 2 "MOTOR_SPEED" 1 "LV_SUPPLY_UV" 0 "UNKNOWN" ;
VAL_ 1318 DIF_a024_failReason 7 "ASC_TEST" 6 "FAULT_PRESENT" 5 "SWITCH_SHORT_DISABLE_CONDITIONS_MET" 4 "TIMEDOUT" 3 "DISAGREE" 2 "NEG_CURRENT" 1 "POS_CURRENT" 0 "CACHED" ;
VAL_ 1318 DIF_a024_state 13 "DISABLED" 12 "TEST_RESTART" 11 "TEST_FAILED" 10 "TEST_SKIPPED" 9 "TEST_PASSED" 8 "TEST_PRE_PASSED" 7 "CURRENT_TEST_NEG" 6 "CURRENT_TEST_POS" 5 "PWM_ENABLE" 4 "ASC_TEST_PASSED" 3 "ASC_TEST" 2 "PSTG_BRING_UP_AT_SPEED" 1 "PSTG_BRING_UP" 0 "INIT" ;
VAL_ 1318 DIF_a038_reason 2 "DI_BMS_VOLTAGE_MISMATCH" 1 "UNDERVOLTAGE_HV_UP" 0 "UNDERVOLTAGE_PRE_CHARGE" ;
VAL_ 1318 DIF_a055_torqueType 2 "PEDAL_POSITION" 1 "TORQUE_COMMAND" 0 "TORQUE_ESTIMATE" ;
VAL_ 1318 DIF_a061_sensor 2 "PH3" 1 "PH2" 0 "PH1" ;
VAL_ 1318 DIF_a061_reason 1 "RAILED" 0 "RATE_OF_CHANGE" ;
VAL_ 1318 DIF_a062_limpReason 43 "UNIT_CHILL_REQUEST" 42 "DEGRADED_REQUEST_VCRIGHT" 41 "DEGRADED_REQUEST_VCLEFT" 40 "DEGRADED_REQUEST_PEPS" 39 "DEGRADED_REQUEST_SEPS" 38 "DEGRADED_REQUEST_PSFA" 37 "DEGRADED_REQUEST_SSFA" 36 "XTAL_OSCILLATOR" 35 "CURRENT_CORE_FALLBACK" 34 "MECHANICAL_SAFE_ST_UNAVAIL" 33 "MOTION_IN_DYNO" 32 "RESIST_STATOR_TEMP" 31 "OIL_PRESSURE_LOW" 30 "HEATSINK_SENSOR_IRRATIONAL" 29 "OIL_PUMP_FLUID_OVERTEMP" 28 "OIL_PUMP_FAILURE" 27 "FACTORY_GLIDER" 26 "SLAVE_MIA" 25 "SLAVE_REQUEST" 24 "CONTACTOR_WELD" 23 "CAPACITOR_OVERTEMP" 22 "GTW_MIA" 21 "TRQCMD_VALIDITY_UNKNOWN" 20 "DI_MIA" 19 "CONFIG_MISMATCH" 18 "HEATSINK_TEMP" 17 "PMREQUEST" 16 "PMHEARTBEAT" 15 "TRQ_CROSS_CHECK" 14 "EXTERNAL_COMMAND" 13 "WRONG_CS_CALIBRATION" 12 "STATOR_TEMP" 11 "DELTAT_TOO_NEGATIVE" 10 "DELTAT_TOO_POSITIVE" 9 "AMBIENT_TEMP" 8 "OUTLET_TEMP" 7 "LOW_FLOW" 6 "BMS_MIA" 5 "LV_SUPPLY_UNDERVOLTAGE" 4 "NO_FLUID" 3 "NO_FUNC_HEATSINK_SENSOR" 2 "NO_FUNC_STATORT_SENSOR" 1 "BUSV_SENSOR_IRRATIONAL" 0 "PHASE_IMBALANCE" ;
VAL_ 1318 DIF_a064_interventionType 15 "excessiveMotorMz" 14 "inconsistentAxleTorque" 13 "diHeartbeat" 12 "currentAfterIntervention" 11 "switchingAfterIntervention" 10 "switchOffPathTestFail" 9 "inconsistentTorqueSign" 8 "torqueInNeutral" 7 "excessiveRegenTorque" 6 "torqueReversal" 5 "accumulatedTorque" 4 "motorMovementDetected" 3 "cruiseFault" 2 "torqueCmdInvalid" 1 "resolver" 0 "masterTorqueMonitorShutoff" ;
VAL_ 1318 DIF_a064_torqueCmdState 8 "Invalid" 6 "Valid" 0 "SNA" ;
VAL_ 1318 DIF_a072_reason 3 "SWITCH_SHORT_TEST" 2 "MECHSS" 1 "EXTERNAL_OSCILLATOR" 0 "DEFAULT" ;
VAL_ 1318 DIF_a090_reason 1 "TOOFAST" 0 "TOOSLOW" ;
VAL_ 1318 DIF_a097_errorType 6 "DPOT_WRITE" 5 "DPOT_READ" 4 "LOST" 3 "CRC" 2 "WRITE" 1 "READ" 0 "OPEN" ;
VAL_ 1318 DIF_a098_fluxState 12 "DISABLED" 11 "MAGNET_FLUX_DETECT" 10 "STATIONARY_WASTE" 9 "FAULT" 7 "VCONTROL" 6 "ICONTROL" 5 "ENABLED" 4 "FLUX_DOWN" 3 "FLUX_UP" 2 "STANDBY" 1 "TEST" 0 "START" ;
VAL_ 1318 DIF_a108_blockingAlert 255 "a255_currentGainFallback" 254 "a254_activeDischargeRail" 253 "a253_lvBoostedRail" 252 "a252_currentCoreFallback" 251 "a251_oilPumpService" 250 "a250_preregulatorRail" 249 "a249_highStatorTempFromResist" 247 "a247_rotorOffsetError" 246 "a246_recoveryAtSpeedError" 245 "a245_mechSafeStatePreWarn" 244 "a244_mechSafeStateApplied" 243 "a243_ecuLogAvailable" 242 "a242_spinDownLearning" 241 "a241_systemThermallyLimited" 240 "a240_clearFusesRoutine" 236 "a236_tasMIA" 234 "a234_pcsMIA" 233 "a233_diMsgMissed" 229 "a229_busVsensorOverCAN" 225 "a225_tmpEstPlausibility" 202 "a202_excessHeatUnavailable" 177 "a177_fluxReferenceCorrected" 176 "a176_safetyICFault" 174 "a174_unitMayNotRestart" 173 "a173_ascFdbkDiagnostic" 172 "a172_statorOilTempOT" 170 "d170_clutchFailure" 169 "d169_clutchPosition" 168 "d168_clutchPerformance" 167 "d167_tempSensorIssue" 166 "d166_rotorOverTemperature" 165 "d165_statorOverTemperature" 164 "d164_firmwareConfigMismatch" 163 "d163_recoverableOvercurrent" 162 "a162_endOfLifetimeBurnIn" 161 "a161_epas3pMIA" 160 "a160_busVoltageAnomaly" 158 "a158_ibstMIA" 157 "a157_rcmMIA" 156 "a156_currentObserver" 155 "a155_vcfrontMIA" 154 "a154_resolver" 153 "a153_oilPumpDiagnostics" 152 "a152_linError" 151 "a151_shockTorqueLimiter" 150 "a150_busVD" 149 "a149_oilPumpFailure" 148 "a148_burnInCycleEnded" 147 "a147_highTorqueWearLimit" 144 "a144_configMismatch" 143 "d143_wheelSpeedCorrelationIssue" 142 "a142_highLashAngle" 141 "d141_coolingSystemIssue" 138 "d138_inverterLVPowerSupplyLow" 137 "d137_currentSensorOutOfRange" 136 "a136_spiError" 135 "d135_rotatedStator" 134 "a134_wheelSpeedIrrational" 133 "a133_capacitorOT" 132 "d132_busUVIssue" 131 "d131_currentSensorOffset" 130 "d130_positionSensorIssue" 129 "d129_oilPumpIssue" 128 "a128_fpgaVersionMismatch" 127 "a127_gracefulPowerOff" 126 "a126_limpMode" 125 "d125_currentSensorIssue" 124 "d124_oilPumpServiceRequired" 123 "a123_lossMotorControl" 122 "a122_highStackUsage" 121 "a121_motorControlRegulation" 120 "a120_hvlinkMIA" 119 "a119_hvpMIA" 118 "d118_oilPumpCommsLost" 117 "a117_diMIA" 116 "a116_highSpeedWearCounter" 115 "a115_exceptionDataAbort2" 114 "a114_exceptionDataAbort" 113 "a113_noFuncHeatsinkSensor" 112 "a112_noPhaseCurrent" 111 "a111_badPhaseSensorCalib" 110 "a110_brakeMIA" 109 "a109_ahbWriteError" 108 "a108_stateTrans" 107 "a107_fpgaError" 106 "a106_idleTaskStarving" 105 "d105_busVoltageSensorIssue" 104 "d104_resetUnintended" 103 "a103_lowFlow" 102 "a102_exceptionPrefetchAbort" 101 "a101_eccTestData1" 100 "a100_assertion" 99 "a099_threadOverrun" 98 "a098_intTimeTooLong" 97 "a097_eepromError" 96 "a096_memoryError" 95 "a095_canOverrunBusA" 94 "a094_canDataBusA" 93 "a093_canHardwareBusA" 92 "a092_bmsMIA" 91 "a091_espMIA" 90 "a090_pmMIA" 89 "d089_invalidTorqueCommand" 88 "a088_uiMIA" 87 "a087_gtwMIA" 86 "a086_activeDischargeOn" 85 "d085_driveInverterBoardFailure" 84 "a084_eccTestData0" 79 "a079_adcRefHigh" 78 "a078_adcRefLow" 77 "a077_lvSupplyUV" 76 "a076_lvSupplyOV" 75 "a075_motorSpeedMismatch" 74 "a074_motorEncoder" 73 "a073_motorSpeed" 72 "a072_gateDriveFaultCounter" 71 "a071_busDisconnected" 70 "a070_udsTransactionInitiated" 69 "a069_rotorTempLimit" 67 "a067_canOverrunBusB" 66 "a066_canDataBusB" 65 "a065_canHardwareBusB" 64 "a064_torqueIntervention" 63 "a063_bbMIA" 62 "a062_systemLimpMode" 61 "a061_heatsinkSensor" 60 "a060_heatsinkUT" 59 "a059_heatsinkOT" 58 "a058_ambientSensor" 57 "a057_ambientUT" 56 "a056_ambientOT" 55 "a055_trqCrossCheck" 54 "a054_driveInverterOT" 53 "a053_unexpectedLatchState" 52 "a052_dirMIA" 50 "a050_noStatorSensor" 49 "a049_statorSensorDiff" 48 "a048_statorSensor2" 47 "a047_statorSensor1" 46 "a046_statorOT" 45 "a045_outletSensor" 44 "a044_outletUT" 43 "a043_outletOT" 42 "a042_inletSensor" 41 "a041_sdcMIA" 40 "a040_difMIA" 39 "a039_exceptionUndefinedInstruction" 38 "a038_busVsensor" 37 "a037_busUV" 36 "a036_busOV" 35 "a035_phaseCurrentBalance" 34 "a034_phaseBcurrentSensor" 33 "a033_phaseAcurrentSensor" 32 "a032_phaseBcurrentOffset" 31 "a031_phaseAcurrentOffset" 30 "a030_phaseCrms" 29 "a029_phaseBrms" 28 "a028_phaseArms" 27 "a027_phaseCpeak" 26 "a026_phaseBpeak" 25 "a025_phaseApeak" 24 "a024_selfTest" 22 "a022_hw5vSupplyUV" 21 "a021_hwBusOV" 20 "a020_hwMotorEncoder" 18 "a018_hwLVSupplyUV" 17 "a017_hwPedalMonitor" 16 "a016_safeStateApplied" 15 "a015_mechSafeStateAnomaly" 14 "a014_activeDamping" 13 "a013_eccError" 12 "a012_hvilNotClosed" 11 "a011_swPowerStageNotReady" 10 "a010_unintendedReset" 9 "a009_hwEncoderB" 8 "a008_hwEncoderA" 7 "a007_statorAnomalyDetected" 6 "a006_hwPhaseCpeak" 5 "a005_hwPhaseBpeak" 4 "a004_hwPhaseApeak" 3 "a003_hwPhaseCgateDrive" 2 "a002_hwPhaseBgateDrive" 1 "a001_hwPhaseAgateDrive" 0 "ALERT_DO_NOT_USE_ZERO" ;
VAL_ 1318 DIF_a121_badRegReason 5 "TORQUE_OFF_TARGET" 4 "FLUX_OFF_TARGET" 3 "IQ_OFF_TARGET" 2 "ID_OFF_TARGET" 1 "RMS_I_HIGH" ;
VAL_ 1318 DIF_a123_lossReason 4 "HIGH_FLUX_DISTURBANCE" 3 "HIGH_VAR_CURR" 2 "HIGH_VAR_FLUX" 1 "NO_FLUX_UP" ;
VAL_ 1318 DIF_a126_limpReason 43 "UNIT_CHILL_REQUEST" 42 "DEGRADED_REQUEST_VCRIGHT" 41 "DEGRADED_REQUEST_VCLEFT" 40 "DEGRADED_REQUEST_PEPS" 39 "DEGRADED_REQUEST_SEPS" 38 "DEGRADED_REQUEST_PSFA" 37 "DEGRADED_REQUEST_SSFA" 36 "XTAL_OSCILLATOR" 35 "CURRENT_CORE_FALLBACK" 34 "MECHANICAL_SAFE_ST_UNAVAIL" 33 "MOTION_IN_DYNO" 32 "RESIST_STATOR_TEMP" 31 "OIL_PRESSURE_LOW" 30 "HEATSINK_SENSOR_IRRATIONAL" 29 "OIL_PUMP_FLUID_OVERTEMP" 28 "OIL_PUMP_FAILURE" 27 "FACTORY_GLIDER" 26 "SLAVE_MIA" 25 "SLAVE_REQUEST" 24 "CONTACTOR_WELD" 23 "CAPACITOR_OVERTEMP" 22 "GTW_MIA" 21 "TRQCMD_VALIDITY_UNKNOWN" 20 "DI_MIA" 19 "CONFIG_MISMATCH" 18 "HEATSINK_TEMP" 17 "PMREQUEST" 16 "PMHEARTBEAT" 15 "TRQ_CROSS_CHECK" 14 "EXTERNAL_COMMAND" 13 "WRONG_CS_CALIBRATION" 12 "STATOR_TEMP" 11 "DELTAT_TOO_NEGATIVE" 10 "DELTAT_TOO_POSITIVE" 9 "AMBIENT_TEMP" 8 "OUTLET_TEMP" 7 "LOW_FLOW" 6 "BMS_MIA" 5 "LV_SUPPLY_UNDERVOLTAGE" 4 "NO_FLUID" 3 "NO_FUNC_HEATSINK_SENSOR" 2 "NO_FUNC_STATORT_SENSOR" 1 "BUSV_SENSOR_IRRATIONAL" 0 "PHASE_IMBALANCE" ;
VAL_ 1318 DIF_a127_gpoReason 15 "MANUAL_RECOVERY_DISTANCE_EXCEEDED" 14 "MOTION_EXPECTED_DURING_SPINDOWN_LEARNING" 13 "FACTORY_DRIVE_DISTANCE_EXCEEDED" 12 "DEGRADED_LIMP_NO_DECEL" 11 "DEGRADED_LIMP_TIMEOUT" 10 "SBW_NODE_UNAVAILABLE" 9 "MOTION_DURING_SPINDOWN_LEARNING" 8 "MOTOR_HALT_REQUEST" 7 "CAPACITOR_OVERTEMP" 6 "NOT_ENOUGH_12V" 5 "NO_BATTERY_POWER" 4 "AMBIENT_OVERTEMP" 3 "FLUID_DELTAT" 2 "STATOR_OVERTEMP" 1 "HEATSINK_OVERTEMP" 0 "OUTLET_OVERTEMP" ;
VAL_ 1318 DIF_a149_flow 255 "SNA" ;
VAL_ 1318 DIF_a149_state 7 "SNA" 6 "FAULTED" 2 "COLD_STARTUP" 1 "ENABLE" 0 "STANDBY" ;
VAL_ 1318 DIF_a149_pcbaID 1 "5" 0 "LESS_THAN_5" ;
VAL_ 1318 DIF_a152_errorType 6 "TIMEOUT_ERROR" 5 "HEADER_ERROR" 4 "OVERFLOW_ERROR" 3 "SCHEDULE_ERROR" 2 "CHECKSUM_ERROR" 1 "FRAMING_ERROR" 0 "NO_ERROR" ;
VAL_ 1318 DIF_a202_reason 12 "HV_DOWN" 11 "CRUISE" 10 "OPD" 9 "DRV_FAULT" 8 "IMMEDIATE" 7 "SERVICE_MODE" 6 "UPDATE_STARTED" 5 "GPO" 4 "LIMP" 3 "MOVEMENT" 2 "PARKBRAKE" 1 "NO_ALERT" 0 "NONE" ;
VAL_ 1318 DIF_a202_sysStateExitCondition 20 "IDLE_USB_ETHERNET_CABLE_CONNECTED" 19 "IDLE_TRUNK_OPEN" 18 "UNAVAILABLE_EXIT_OK" 17 "UNAVAILABLE_UNITS_NOT_AVAILABLE" 16 "UNAVAILABLE_SSPD_SPEED_IS_NOT_PUBLISHED" 15 "UNAVAILABLE_ALERTS_ACTIVE" 14 "UNAVAILABLE_HV_IS_NOT_UP" 13 "UNAVAILABLE_SLIM_GPO_OR_CAN_DRIVE_GOING_DOWN" 12 "IDLE_EXIT_OK" 11 "IDLE_FIRMWARE_VERIFICATION" 10 "IDLE_BATTERY_POWER_LIMITS" 9 "IDLE_NON_ZERO_PEDAL_POS" 8 "IDLE_FALCON_DOOR_OPEN" 7 "IDLE_PROX_DETECTED" 6 "IDLE_FRUNK_NOT_LATCHED" 5 "IDLE_IMMOBILIZER_INHIBIT" 4 "IDLE_HV_NOT_UP_FOR_DRIVE" 3 "IDLE_LV_OR_SBW_STATUS_LIMP" 2 "IDLE_LV_OR_SBW_STATUS_NOT_READY" 1 "IDLE_DRIVE_RAIL_NOT_REQUESTED" 0 "IDLE_VEHICLE_POWER_STATE_NOT_DRIVE" ;
VAL_ 1318 DIF_a246_codeBranch 3 "SAFESTATE_RELEASE_LATCH" 2 "SAFESTATE_RELEASE_ASC" 1 "PSTG_INIT" 0 "QUALIFICATION" ;
VAL_ 1318 DIF_a251_oilFlow 255 "SNA" ;
VAL_ 1318 DIF_a251_oilTemperature 255 "SNA" ;
VAL_ 1318 DIF_a251_dcVoltage 255 "SNA" ;
VAL_ 1318 DIF_a251_dcCurrent 255 "SNA" ;
VAL_ 1318 DIF_a251_phaseCurrent 255 "SNA" ;
VAL_ 1318 DIF_a251_reason 4 "INSUFFICIENT_FLOW" 3 "CURRENT_SENSOR" 2 "PRESSURE_HIGH" 1 "PRESSURE_LOW" 0 "NONE" ;
VAL_ 1318 DIF_a253_reason 2 "OVERVOLTAGE" 1 "UNDERVOLTAGE" 0 "NONE" ;
VAL_ 854 DIF_matrixIndex 4 "AlertMatrix4" 3 "AlertMatrix3" 2 "AlertMatrix2" 1 "AlertMatrix1" 0 "AlertMatrix0" ;
VAL_ 1879 DIF_debugSelector 132 "Mux132" 131 "Mux131" 128 "Mux128" 73 "Mux73" 72 "Mux72" 70 "Mux70" 69 "Mux69" 68 "Mux68" 67 "Mux67" 66 "Mux66" 64 "Mux64" 63 "Mux63" 52 "Mux52" 50 "Mux50" 49 "Mux49" 48 "Mux48" 47 "Mux47" 46 "Mux46" 44 "Mux44" 43 "Mux43" 42 "Mux42" 41 "Mux41" 40 "Mux40" 39 "Mux39" 38 "Mux38" 37 "Mux37" 36 "Mux36" 35 "Mux35" 34 "Mux34" 33 "Mux33" 32 "Mux32" ;
VAL_ 1879 DIF_usmState 7 "USM_STATE_WAIT_FOR_RETRY" 6 "USM_STATE_UNAVAILABLE" 5 "USM_STATE_FAULT" 4 "USM_STATE_ENABLE" 3 "USM_STATE_ABORT" 2 "USM_STATE_RETRY" 1 "USM_STATE_STANDBY" 0 "USM_STATE_START" ;
VAL_ 1879 DIF_pwmState 3 "PWMSTATE_OPWM2" 2 "PWMSTATE_OPWM1" 1 "PWMSTATE_DPWM2" 0 "PWMSTATE_SVPWM" ;
VAL_ 1879 DIF_phaseOutBusbarTemp 0 "SNA" ;
VAL_ 1879 DIF_phaseOutBusbarWeldTemp 0 "SNA" ;
VAL_ 1879 DIF_phaseOutLugTemp 0 "SNA" ;
VAL_ 1879 DIF_dcLinkCapTemp 0 "SNA" ;
VAL_ 1879 DIF_hvDcCableTemp 0 "SNA" ;
VAL_ 1879 DIF_negDcBusbarTemp 0 "SNA" ;
VAL_ 1879 DIF_posDcBusbarTemp 0 "SNA" ;
VAL_ 1879 DIF_statorEndWindingTemp 0 "SNA" ;
VAL_ 1879 DIF_rotorMaxMagnetTemp 0 "SNA" ;
VAL_ 1879 DIF_statorSlotWindingTemp 0 "SNA" ;
VAL_ 634 DIF_hvilStatus 3 "SNA" 2 "CLOSED" 1 "OPEN" 0 "DISABLED" ;
VAL_ 634 DIF_hvilSupplyState 2 "ACTIVE" 1 "INACTIVE" 0 "NOT_AVAILABLE" ;
VAL_ 634 DIF_vBatQF 1 "QUALIFIED" 0 "NOT_QUALIFIED" ;
VAL_ 634 DIF_powerStageSafeState 3 "PSTG_SAFESTATE_3PS_LOW" 2 "PSTG_SAFESTATE_3PS_HIGH" 1 "PSTG_SAFESTATE_ALL_OFF" 0 "PSTG_SAFESTATE_NONE" ;
VAL_ 634 DIF_fluxState 12 "DI_FLUXSTATE_DISABLED" 11 "DI_FLUXSTATE_MAGNET_FLUX_DETECT" 10 "DI_FLUXSTATE_STATIONARY_WASTE" 9 "DI_FLUXSTATE_FAULT" 7 "DI_FLUXSTATE_VCONTROL" 6 "DI_FLUXSTATE_ICONTROL" 5 "DI_FLUXSTATE_ENABLED" 4 "DI_FLUXSTATE_FLUX_DOWN" 3 "DI_FLUXSTATE_FLUX_UP" 2 "DI_FLUXSTATE_STANDBY" 1 "DI_FLUXSTATE_TEST" 0 "DI_FLUXSTATE_START" ;
VAL_ 634 DIF_gateDriveState 4 "PSTG_GD_STATE_NOT_CONFIGURED" 3 "PSTG_GD_STATE_CONFIGURED" 2 "PSTG_GD_STATE_CONFIGURING" 1 "PSTG_GD_STATE_SELFTEST" 0 "PSTG_GD_STATE_INIT" ;
VAL_ 634 DIF_gateDriveSupplyState 3 "PSTG_GD_SUPPLY_FALLING" 2 "PSTG_GD_SUPPLY_UP" 1 "PSTG_GD_SUPPLY_RISING" 0 "PSTG_GD_SUPPLY_DOWN" ;
VAL_ 1622 DIF_infoIndex 255 "INFO_END" 44 "TRACKING_DATA_5" 43 "TRACKING_DATA_4" 42 "TRACKING_DATA_3" 41 "TRACKING_DATA_2" 40 "TRACKING_DATA_1" 34 "INFO_SUBCOMPONENT2_HWID" 33 "INFO_SUBCOMPONENT_HWID" 32 "INFO_SUBCOMPONENT2_GITHASH" 31 "INFO_SUBCOMPONENT_GITHASH" 23 "INFO_SUBCOMPONENT2" 20 "INFO_UDS_PROTOCOL_BOOTCRC" 19 "INFO_VERSION_DEPRECATED" 18 "INFO_BOOTLOADER_GITHASH" 17 "INFO_APP_GITHASH" 16 "INFO_SUBCOMPONENT" 15 "INFO_BOOTLOADER_CRC" 14 "INFO_BOOTLOADER_SVN" 13 "INFO_APP_CRC" 11 "INFO_PCBAID_ASSYID_USAGEID" 10 "INFO_BUILD_HWID_COMPONENTID" 9 "INFO_DEPRECATED_9" 8 "INFO_DEPRECATED_8" 7 "INFO_DEPRECATED_7" 6 "INFO_DEPRECATED_6" 5 "INFO_DEPRECATED_5" 4 "INFO_DEPRECATED_4" 3 "INFO_DEPRECATED_3" 2 "INFO_DEPRECATED_2" 1 "INFO_DEPRECATED_1" 0 "INFO_DEPRECATED_0" ;
VAL_ 1622 DIF_buildType 4 "INFO_MFG_BUILD" 3 "INFO_TRACEABLE_CI_BUILD" 2 "INFO_LOCAL_BUILD" 1 "INFO_PLATFORM_BUILD" 0 "INFO_UNKNOWN_BUILD" ;
VAL_ 1622 DIF_hardwareId 252 "CONFIGURABLE_HWID_PLACEHOLDER" ;
VAL_ 1622 DIF_motorType 36 "DI_MOTOR_PM240C" 35 "DI_MOTOR_IM188A" 34 "DI_MOTOR_IM130E_AL" 32 "DI_MOTOR_PM261D" 31 "DI_MOTOR_PM216E" 20 "DI_MOTOR_PM215D_1KV" 18 "DI_MOTOR_IM260E_1KV" 17 "DI_MOTOR_IM260D_1KV" 16 "DI_MOTOR_PM261C" 15 "DI_MOTOR_PM215C_1KV" 14 "DI_MOTOR_IM260C_1KV" 13 "DI_MOTOR_PM215A_1KV" 12 "DI_MOTOR_IM260A_1KV" 11 "DI_MOTOR_IM228HEA" 10 "DI_MOTOR_PM228HEA" 9 "DI_MOTOR_PM275C" 8 "DI_MOTOR_PM291D" 7 "DI_MOTOR_PM291C" 6 "DI_MOTOR_PM228C" 5 "DI_MOTOR_PM350B" 4 "DI_MOTOR_PM275B" 3 "DI_MOTOR_IM130D_AL" 2 "DI_MOTOR_IM130D" 1 "DI_MOTOR_PM216D" 0 "DI_MOTOR_SNA" ;
VAL_ 1622 DIF_siliconType 1 "IGBT" 0 "MOSFET" ;
VAL_ 1622 DIF_mechSafeStateType 2 "DI_MECH_SAFE_STATE_TYPE_PRESENT" 1 "DI_MECH_SAFE_STATE_TYPE_NONE" 0 "DI_MECH_SAFE_STATE_TYPE_SNA" ;
VAL_ 1622 DIF_oilPumpBuildType 4 "INFO_MFG_BUILD" 3 "INFO_TRACEABLE_CI_BUILD" 2 "INFO_LOCAL_BUILD" 1 "INFO_PLATFORM_BUILD" 0 "INFO_UNKNOWN_BUILD" ;
VAL_ 1622 DIF_FPGA_version 255 "SNA" 254 "LOCAL_BUILD" ;
VAL_ 1622 DIF_refRotorOffset -2048 "SNA" ;
VAL_ 1622 DIF_speedWearTotal 255 "SNA" ;
VAL_ 1622 DIF_torqueWearTotal 255 "SNA" ;
VAL_ 421 DIF_targetFluxMode 2 "DI_FLUXMODE_FW" 1 "DI_FLUXMODE_FS" 0 "DI_FLUXMODE_OPTIMUM" ;
VAL_ 421 DIF_keepAliveRequest 1 "KEEP_ALIVE" 0 "NO_REQUEST" ;
VAL_ 918 DIF_oilPumpState 7 "OIL_PUMP_SNA" 6 "OIL_PUMP_FAULTED" 2 "OIL_PUMP_COLD_STARTUP" 1 "OIL_PUMP_ENABLE" 0 "OIL_PUMP_STANDBY" ;
VAL_ 918 DIF_oilPumpFluidTQF 1 "OIL_PUMP_FLUIDT_HIGH_CONFIDENCE" 0 "OIL_PUMP_FLUIDT_LOW_CONFIDENCE" ;
VAL_ 918 DIF_oilPumpFlowTarget 255 "SNA" ;
VAL_ 918 DIF_oilPumpFlowActual 255 "SNA" ;
VAL_ 918 DIF_oilPumpFluidT 255 "SNA" ;
VAL_ 918 DIF_oilPumpPhaseCurrent 255 "SNA" ;
VAL_ 918 DIF_oilPumpPressureEstimate 255 "SNA" ;
VAL_ 918 DIF_oilPumpPressureExpected 255 "SNA" ;
VAL_ 918 DIF_oilPumpPressureResidual 255 "SNA" ;
VAL_ 741 DIF_elecPower -1024 "SNA" ;
VAL_ 741 DIF_drivePowerMax 511 "SNA" ;
VAL_ 725 DIF_state 4 "DI_STATE_ENABLE" 3 "DI_STATE_ABORT" 2 "DI_STATE_FAULT" 1 "DI_STATE_STANDBY" 0 "DI_STATE_UNAVAILABLE" ;
VAL_ 725 DIF_soptState 9 "SOPT_DISABLED" 8 "SOPT_SNA" 7 "SOPT_TEST_FAILED" 6 "SOPT_TEST_SKIPPED" 5 "SOPT_TEST_PASSED" 4 "SOPT_CURRENT_TEST" 3 "SOPT_ASC_TEST" 2 "SOPT_PSTG_BRING_UP_AT_SPEED" 1 "SOPT_PSTG_BRING_UP" 0 "SOPT_INIT" ;
VAL_ 725 DIF_adState 3 "AD_STATE_FAULTED" 2 "AD_STATE_BACKUP" 1 "AD_STATE_NORMAL" 0 "AD_STATE_STARTUP" ;
VAL_ 725 DIF_driveModeState 1 "DM_STATE_DRIVE" 0 "DM_STATE_NONDRIVE" ;
VAL_ 725 DIF_wasteState 3 "DI_WASTE_STATIONARY" 2 "DI_WASTE_ON" 1 "DI_WASTE_AVAILABLE" 0 "DI_WASTE_UNAVAILABLE" ;
VAL_ 725 DIF_haltRequest 2 "DI_HALT_GRACEFUL" 1 "DI_HALT_IMMEDIATE" 0 "DI_HALT_NONE" ;
VAL_ 725 DIF_adDirection 1 "AD_FORWARD" 0 "AD_BACKWARD" ;
VAL_ 725 DIF_spinDownLearningState 9 "SPINDOWN_STATE_DONE" 8 "SPINDOWN_STATE_WRITE" 7 "SPINDOWN_STATE_VERIFY" 6 "SPINDOWN_STATE_CORRECT" 5 "SPINDOWN_STATE_MEASURE" 4 "SPINDOWN_STATE_COAST" 3 "SPINDOWN_STATE_ACCELERATE" 2 "SPINDOWN_STATE_WAIT" 1 "SPINDOWN_STATE_PRECHECK" 0 "SPINDOWN_STATE_INIT" ;
VAL_ 725 DIF_spinDownLearningMode 1 "SPINDOWN_MODE_ON_GROUND" 0 "SPINDOWN_MODE_ON_LIFT" ;
VAL_ 886 DIF_tempIndex 4 "Mux4" 3 "Mux3" 2 "Mux2" 1 "Mux1" 0 "Mux0" ;
VAL_ 886 DIF_inverterTQF 3 "INVERTERT_UNKNOWN" 2 "INVERTERT_RATIONAL" 1 "INVERTERT_IRRATIONAL" 0 "INVERTERT_INIT" ;
VAL_ 886 DIF_pcbT 0 "SNA" ;
VAL_ 886 DIF_statorT 0 "SNA" ;
VAL_ 886 DIF_dcCapT 0 "SNA" ;
VAL_ 886 DIF_heatsinkT 0 "SNA" ;
VAL_ 886 DIF_fluidInTemp 0 "SNA" ;
VAL_ 886 DIF_normalFetBurnIn 65535 "SNA" ;
VAL_ 886 DIF_additionalFetBurnIn 65535 "SNA" ;
VAL_ 886 DIF_currentWeibullMiles 32767 "SNA" ;
VAL_ 886 DIF_endOfServiceWeibullMiles 32767 "SNA" ;
VAL_ 886 DIF_burnInDamageRatio 511 "SNA" 510 "DEFAULT_1" ;
VAL_ 886 DIF_initialBurnInVehicleOdometer 4294967295 "SNA" ;
VAL_ 886 DIF_statorHousingTemp 0 "SNA" ;
VAL_ 1367 DIF_oilFlowReq 255 "SNA" ;
VAL_ 1367 DIF_criticalFlowReq 1 "ACTIVE" 0 "NOT_ACTIVE" ;
VAL_ 1367 DIF_burnInStatus 5 "COMPLETE" 4 "ACTIVE" 3 "INCOMPLETE" 2 "UNAVAILABLE" 1 "NOT_REQUIRED" 0 "INIT" ;
VAL_ 390 DIF_torqueCommand -4096 "SNA" ;
VAL_ 390 DIF_axleSpeedQF 2 "FAULTED" 1 "VALID" 0 "INVALID" ;
VAL_ 390 DIF_torqueActual -4096 "SNA" ;
VAL_ 390 DIF_axleSpeed -32768 "SNA" ;
VAL_ 390 DIF_axleTorqueQF 2 "FAULTED" 1 "VALID" 0 "INVALID" ;
VAL_ 390 DIF_axlePowerCalcQF 1 "VALID" 0 "INVALID" ;
VAL_ 390 DIF_gear 7 "DI_GEAR_SNA" 4 "DI_GEAR_D" 3 "DI_GEAR_N" 2 "DI_GEAR_R" 1 "DI_GEAR_P" 0 "DI_GEAR_INVALID" ;
